[part 1 of 2: packages /CAN4/ISignalGroup to /CAN4/Cluster]
AUTOSAR XML (schema 4-3-0)
package /CAN4/ISignalGroup
  21 x i signal group:
    CAN4_SG_DKC1: i-signal=[CAN4_DKC_KeyNum_Sta, CAN4_DKC_KeyType_Sta, CAN4_DKC_PDkeyAreaRAPS_Sta, CAN4_DKC_ParkingMode_Cmd, CAN4_DKC_Re_VehData, CAN4_P_CommandToBCM, CAN4_P_CommandToPTG, CAN4_P_DKey_Area_LockUnlock, CAN4_P_DKey_Area_PS, CAN4_P_DKey_Area_PTG, CAN4_P_DKey_Welcome, CAN4_P_Dkey_Show_IVI, CAN4_P_KeyMiss, CAN4_P_KeyMode, CAN4_P_UID_LowPower], system-signal-group=CAN4_SG_DKC1
    CAN4_SG_DKC2: i-signal=[CAN4_EncryptionDATA_0_63, CAN4_EncryptionDATA_64_127, CAN4_Random_Number_X], system-signal-group=CAN4_SG_DKC2
    CAN4_SG_FD4_C100_0: i-signal=CAN4_FDC_CHA_EACEnDemand_Cmd, system-signal-group=CAN4_SG_FD4_C100_0
    CAN4_SG_FD4_CE100_0: i-signal=[CAN4_APS_Sta_System, CAN4_AllDoorSW, CAN4_AntiTheftSeatFold, CAN4_AntitheftSta, CAN4_BCM_DoorLock_Sta, CAN4_BrakeLamp, CAN4_CC_Crl_Sta, CAN4_CS_VCU1_CAN4, CAN4_CTDCtrl, CAN4_CTDLockSW, CAN4_CTDUnlockSW, CAN4_CrashDetd, CAN4_CtrlDrPwrStbA2, CAN4_CtrlFrBMSCCUCIR, CAN4_CtrlFrEDUINVERTER, CAN4_CtrlFrIRC1, CAN4_CtrlFrPwrStbA1P, CAN4_DKCAuthSta, CAN4_DKCTimeSN, CAN4_Dimmer, CAN4_DimmerEN, CAN4_DoorLockIND, CAN4_DrDoorSW, CAN4_Dr_SeatSta, CAN4_EquivAccPedalSWSta, CAN4_FD_DKC_VehData_Err, CAN4_FD_DKC_VehData_Sta, CAN4_FD_TBOX_DTCData_Err, CAN4_FD_TBOX_DTCData_Sta, CAN4_FD_TBOX_VehData_Err, CAN4_FD_TBOX_VehData_Sta, CAN4_Fr_ChargingDoorCtrl, CAN4_Fr_FogLamp, CAN4_Fr_Wiper_H, CAN4_Fr_Wiper_L, CAN4_HWResetSta, CAN4_H_Beam, CAN4_H_Beam_ADB, CAN4_HazardSW, CAN4_HoodSW, CAN4_HornCtrl, CAN4_LBSD, CAN4_LDRL, CAN4_LTurnLP, CAN4_L_APM_WdwEnable, CAN4_L_Beam, CAN4_LampPwr, CAN4_LockSetting, CAN4_MSA_Crl_Sta, CAN4_MirrorCtrl, CAN4_MirrorDefog, CAN4_PosLamp, CAN4_PsDoorSW, CAN4_PwrSta, CAN4_RBSD, CAN4_RC_VCU1_CAN4, CAN4_RDRL, CAN4_RLDoorSW, CAN4_RRDoorSW, CAN4_RTurnLP, CAN4_ReBrakeLPReq, CAN4_ReverseLamp, CAN4_RoomLampH, CAN4_RoomLampL, CAN4_Rr_ChargingDoorCtrl, CAN4_Rr_Defog, CAN4_Rr_FogLamp, CAN4_Rr_Wiper, CAN4_ShiftGearPosn, CAN4_TailgateHDSW, CAN4_TailgateRemote, CAN4_Tailgate_SW, CAN4_TimeSNDKCFbk, CAN4_TrunkRel, CAN4_WasherCtrl, CAN4_WiperFixMode], system-signal-group=CAN4_SG_FD4_CE100_0
    CAN4_SG_FD4_CE100_1: i-signal=[CAN4_ACSubMode, CAN4_APTC_ActFrRiPwr, CAN4_BatLoopActWtFlw, CAN4_BatteryMode, CAN4_CCU_ACLampSts, CAN4_CCU_ACMaxLampSts, CAN4_CCU_AutoLampSts, CAN4_CCU_AutoMidLampSts, CAN4_CCU_CbnPreACWkSts, CAN4_CCU_CbnPreEstimdTi, CAN4_CCU_CbnPreSts, CAN4_CCU_Dispaly_Request, CAN4_CCU_EcoSts, CAN4_CCU_FrtOnOffLampSts, CAN4_CCU_HEATMaxLampSts, CAN4_CCU_HiVoltageReq, CAN4_CCU_RrOnOffLampSts, CAN4_CCU_SyncLampSts, CAN4_CabinMode, CAN4_CoolgFanActDuty, CAN4_DeiceModReq, CAN4_EDriveMode, CAN4_FDC_THCM_CLEVentY_Sta, CAN4_FDC_THCM_CLEVentZ_Sta, CAN4_FDC_THCM_CLVent_Sta, CAN4_FDC_THCM_CREVentY_Sta, CAN4_FDC_THCM_CREVentZ_Sta, CAN4_FDC_THCM_CRVent_Sta, CAN4_FDC_THCM_DrEVentMode_Sta, CAN4_FDC_THCM_DrEVentY_Sta, CAN4_FDC_THCM_DrEVentZ_Sta, CAN4_FDC_THCM_DrVent_Sta, CAN4_FDC_THCM_PsEVentMode_Sta, CAN4_FDC_THCM_PsEVentY_Sta, CAN4_FDC_THCM_PsEVentZ_Sta, CAN4_FDC_THCM_PsVent_Sta, CAN4_FD_Blower_Cmd, CAN4_FD_Comp_Cmd, CAN4_FD_EWP1_Cmd, CAN4_FD_EWP2_Cmd, CAN4_FD_EWP3_Cmd, CAN4_FD_EXV1_Cmd, CAN4_FD_EXV2_Cmd, CAN4_FD_FWV_Cmd, CAN4_FD_FrLeAPTCHeatPwr_Cmd, CAN4_FD_FrRiAPTCHeatPwr_Cmd, CAN4_FD_FrWPTCHeatPwr_Cmd, CAN4_FD_RecyAuto_Cmd, CAN4_FD_RrAPTCHeatPwr_Cmd, CAN4_FD_SOTXV_Cmd, CAN4_FD_SOV1_Cmd, CAN4_FD_SOV2_Cmd, CAN4_FD_SOV3_Cmd, CAN4_FD_TWV_Cmd, CAN4_Fr_Coolantflow, CAN4_Fr_Coolanttemp, CAN4_HPThermalRecoveryReq, CAN4_Rr_Coolantflow, CAN4_Rr_Coolanttemp, CAN4_sigAirIntenZon1St, CAN4_sigAirIntenZon3St, CAN4_sigAmbAirT, CAN4_sigCbnAirT, CAN4_sigCbnPTCPwrAct, CAN4_sigCbnSolarLeft, CAN4_sigCbnSolarRight, CAN4_sigClmtCmprPwrAct, CAN4_sigClntTHvBattOut, CAN4_sigDfrstSt, CAN4_sigHvacSt, CAN4_sigRecircSt, CAN4_sigSetTempZon1St, CAN4_sigSetTempZon2St, CAN4_sigSetTempZon3St, CAN4_sigWindDirZon1St, CAN4_sigWindDirZon3St], system-signal-group=CAN4_SG_FD4_CE100_1
    CAN4_SG_FD4_CE100_2: i-signal=[CAN4_FD4_CE100_2_CS, CAN4_FD4_CE100_2_RC, CAN4_FDC_VCU_ReqHWReset_Cmd], system-signal-group=CAN4_SG_FD4_CE100_2
    CAN4_SG_FD4_CE100_3: i-signal=[CAN4_FDC_BCM_BBuzzer_Cmd, CAN4_FDC_BCM_BBuzzerout_Cmd, CAN4_FDC_BCM_EmExitLight_Cmd, CAN4_FDC_BCM_FrAtmoLamp_Cmd, CAN4_FDC_BCM_FrRmLampBright_Cmd, CAN4_FDC_BCM_FrRoomlamp_Cmd, CAN4_FDC_BCM_IBuzzerReq_Sta, CAN4_FDC_BCM_LSMLP_Cmd, CAN4_FDC_BCM_LTgateRel_Cmd, CAN4_FDC_BCM_RSMLP_Cmd, CAN4_FDC_BCM_RTgateRel_Cmd, CAN4_FDC_BCM_RevBuzzerout_Cmd, CAN4_FDC_BCM_RrAtmoLamp_Cmd, CAN4_FDC_BCM_RrRmLampBright_Cmd, CAN4_FDC_BCM_RrRoomlamp_Cmd, CAN4_FDC_BCM_STurnLpLeft_Cmd, CAN4_FDC_BCM_STurnLpRight_Cmd, CAN4_FDC_BCM_TgateHDSWL_Sta, CAN4_FDC_BCM_TgateHDSWR_Sta, CAN4_FDC_BCM_TgateSWL_Sta, CAN4_FDC_BCM_TgateSWR_Sta, CAN4_FDC_BCM_TurnLpLActive_Cmd, CAN4_FDC_BCM_TurnLpRActive_Cmd, CAN4_FDC_BCM_innerBuzzer_Cmd], system-signal-group=CAN4_SG_FD4_CE100_3
    CAN4_SG_FD4_CE200_0: i-signal=[CAN4_AmbLightBreath1, CAN4_AmbLightBreath2, CAN4_AmbLightBreath3, CAN4_AmbLightBreath4, CAN4_AmbLightBreath5, CAN4_AmbLightBreath6, CAN4_AmbLightBrightness1, CAN4_AmbLightBrightness2, CAN4_AmbLightBrightness3, CAN4_AmbLightBrightness4, CAN4_AmbLightBrightness5, CAN4_AmbLightBrightness6, CAN4_AmbLightColor1, CAN4_AmbLightColor2, CAN4_AmbLightColor3, CAN4_AmbLightColor4, CAN4_AmbLightColor5, CAN4_AmbLightColor6, CAN4_BCM_Buzzer_Req, CAN4_FDC_BCM_ATCtrl_Cmd, CAN4_FDC_BCM_DimSw, CAN4_FDC_BCM_FWasSw_Sta, CAN4_FDC_BCM_FWipSw_Sta, CAN4_FDC_BCM_HazardIND_Cmd, CAN4_FDC_BCM_LockAlarm_Cmd, CAN4_FDC_BCM_OutMode_Cmd, CAN4_FDC_BCM_PTGOpenHeight_Sta, CAN4_FDC_BCM_PassSW_Sta, CAN4_FDC_BCM_TurnSwTSetSta_Sta, CAN4_FDC_BCM_TurnSw_Sta, CAN4_FDC_BCM_UserHeightSet_Sta, CAN4_FDC_BCM_UserNow_Sta, CAN4_FDC_DKC_CommandToBCM_Cmd, CAN4_FDC_DKC_DKeyAreaPE_Sta, CAN4_FDC_DKC_SPTGDet_Cmd, CAN4_FDC_DKC_SPTGOpen_Cmd, CAN4_FDC_EChrg_SW_Sta, CAN4_FDC_THCM_ACTInitial_Cmd, CAN4_FDC_THCM_AirIntZ3_Sta, CAN4_FDHandleCmd, CAN4_FDLHandleLampCmd, CAN4_FDRHandleLampCmd, CAN4_WelcomeLight], system-signal-group=CAN4_SG_FD4_CE200_0
    CAN4_SG_FD4_OTA1: i-signal=[CAN4_OTA_DL_Available, CAN4_OTA_DL_Speed, CAN4_OTA_Debug_Code, CAN4_OTA_Emergency_Sta, CAN4_OTA_InVehicle_FW, CAN4_OTA_Lock_Req, CAN4_OTA_MDA_Status, CAN4_OTA_Mode, CAN4_OTA_Network_Type, CAN4_OTA_Permit_Agreed, CAN4_OTA_Progress_Rate, CAN4_OTA_Remained_Time, CAN4_OTA_TBOXResetReq, CAN4_OTA_Update_Available, CAN4_OTA_Updating_ECU_8bit], system-signal-group=CAN4_SG_FD4_OTA1
    CAN4_SG_GW4_CE100_0: i-signal=[CAN4_BrkPedalPos, CAN4_BrkPedalPos_Sta, CAN4_BrkSw_Sta, CAN4_BrkSw_V, CAN4_FDC_PTG_inner_SW_2, CAN4_L_Drv_CtrlCmd, CAN4_L_Pas_CtrlCmd, CAN4_L_RLD_CtrlCmd, CAN4_L_RRD_CtrlCmd, CAN4_MCPressure, CAN4_MCPressure_V, CAN4_VehSpeed], system-signal-group=CAN4_SG_GW4_CE100_0
    CAN4_SG_CGW_GW4_CE100_0: i-signal=[CAN4_AVM_parking_excute, CAN4_Approach_Unlock_SW, CAN4_ChrgInLockReq, CAN4_ChrgPlugSta, CAN4_DSEAT_anti_set, CAN4_DSEAT_entryfun_set, CAN4_DSEAT_vent_req, CAN4_Distance_unit, CAN4_ExtChrgSta, CAN4_HeadLampSW, CAN4_Hood_Latch_SW, CAN4_IVI_ChargePortSW_Sta, CAN4_IVI_DSEATHeater_Cmd, CAN4_IVI_ISA_OffsetSpd, CAN4_IVI_Located_STA, CAN4_IVI_PSEATHeater_Cmd, CAN4_IVI_PTG_Mode_SW, CAN4_IVI_PTG_Open_Height, CAN4_IVI_PTG_Sta_SW, CAN4_IVI_Time_Check, CAN4_IVI_Time_Day, CAN4_IVI_Time_Hour, CAN4_IVI_Time_Minute, CAN4_IVI_Time_Month, CAN4_IVI_Time_Second, CAN4_IVI_Time_Year, CAN4_IVI_TrailerCheckReq_Sta, CAN4_IVI_TrailerModeSW_Sta, CAN4_Light_ShowStart_Req, CAN4_Light_ShowStop_Req, CAN4_METER_KPH_Calcu, CAN4_OBCV2LSta, CAN4_OFF_AC_MODE, CAN4_PSEAT_vent_req, CAN4_SenstivityPosition, CAN4_TBOX_Remote_PW, CAN4_V2LSta, CAN4_Walkaway_Lock_SW, CAN4_WlcmLight_Mode], system-signal-group=CAN4_SG_CGW_GW4_CE100_0
    CAN4_SG_GW4_CE200_0: i-signal=[CAN4_IVI_LSEATvent_Cmd, CAN4_IVI_MLFMost_Cmd, CAN4_IVI_MLFootLift_Cmd, CAN4_IVI_MLNapMode_Cmd, CAN4_IVI_MLRecliner_Cmd, CAN4_IVI_MLRestore_Cmd, CAN4_IVI_MLSEATvent_Cmd, CAN4_IVI_MLSeatLift_Cmd, CAN4_IVI_MLSldRestore_Cmd, CAN4_IVI_MLSlider_Cmd, CAN4_IVI_MLZeroGravity_Cmd, CAN4_IVI_MRFMost_Cmd, CAN4_IVI_MRFootLift_Cmd, CAN4_IVI_MRNapMode_Cmd, CAN4_IVI_MRRecliner_Cmd, CAN4_IVI_MRRestore_Cmd, CAN4_IVI_MRSEATvent_Cmd, CAN4_IVI_MRSeatLift_Cmd, CAN4_IVI_MRSldRestore_Cmd, CAN4_IVI_MRSlider_Cmd, CAN4_IVI_MRZeroGravity_Cmd, CAN4_IVI_RSEATvent_Cmd], system-signal-group=CAN4_SG_GW4_CE200_0
    CAN4_SG_Z24_C1000_0: i-signal=[CAN4_Z24_CHA_AirPressureFC2_Sta, CAN4_Z24_CHA_AirPressurePC3_Sta, CAN4_Z24_CHA_AirPressureRC1_Sta], system-signal-group=CAN4_SG_Z24_C1000_0
    CAN4_SG_Z24_CE100_0: i-signal=[CAN4_Z24_BCM_EmExitOP_Sta, CAN4_Z24_BCM_FLTurnLampC_Sta, CAN4_Z24_BCM_FRTurnLampC_Sta, CAN4_Z24_BCM_FWiperAS_Sta, CAN4_Z24_BCM_FWiperProtection_Sta, CAN4_Z24_BCM_RLTurnLampC_Sta, CAN4_Z24_BCM_RRTurnLampC_Sta, CAN4_Z24_BCM_SeatBeltSW_Sta, CAN4_Z24_BCM_innerBuzzer_Sta], system-signal-group=CAN4_SG_Z24_CE100_0
    CAN4_SG_ZONE_DR1: i-signal=[CAN4_ACT1_Actuator_address, CAN4_ACT1_Actuator_set_position, CAN4_ACT1_Actuator_start_position, CAN4_ACT1_Applied_holding_current, CAN4_ACT1_Clear_Event_Flags, CAN4_ACT1_Emergency_run_position, CAN4_ACT1_Emergency_run_release, CAN4_ACT1_Rotation_direction, CAN4_ACT1_Save_programming_data, CAN4_ACT1_Select_position_specification, CAN4_ACT1_Speed_specification, CAN4_ACT1_Stall_detection_release, CAN4_ACT1_Stop_mode, CAN4_ACT2_Actuator_address, CAN4_ACT2_Actuator_set_position, CAN4_ACT2_Actuator_start_position, CAN4_ACT2_Applied_holding_current, CAN4_ACT2_Clear_Event_Flags, CAN4_ACT2_Emergency_run_position, CAN4_ACT2_Emergency_run_release, CAN4_ACT2_Rotation_direction, CAN4_ACT2_Save_programming_data, CAN4_ACT2_Select_position_specification, CAN4_ACT2_Speed_specification, CAN4_ACT2_Stall_detection_release, CAN4_ACT2_Stop_mode, CAN4_ACT3_Actuator_address, CAN4_ACT3_Actuator_set_position, CAN4_ACT3_Actuator_start_position, CAN4_ACT3_Applied_holding_current, CAN4_ACT3_Clear_Event_Flags, CAN4_ACT3_Emergency_run_position, CAN4_ACT3_Emergency_run_release, CAN4_ACT3_Rotation_direction, CAN4_ACT3_Save_programming_data, CAN4_ACT3_Select_position_specification, CAN4_ACT3_Speed_specification, CAN4_ACT3_Stall_detection_release, CAN4_ACT3_Stop_mode, CAN4_ACT4_Actuator_address, CAN4_ACT4_Actuator_set_position, CAN4_ACT4_Actuator_start_position, CAN4_ACT4_Applied_holding_current, CAN4_ACT4_Clear_Event_Flags, CAN4_ACT4_Emergency_run_position, CAN4_ACT4_Emergency_run_release, CAN4_ACT4_Rotation_direction, CAN4_ACT4_Save_programming_data, CAN4_ACT4_Select_position_specification, CAN4_ACT4_Speed_specification, CAN4_ACT4_Stall_detection_release, CAN4_ACT4_Stop_mode, CAN4_ACT5_Actuator_address, CAN4_ACT5_Actuator_set_position, CAN4_ACT5_Actuator_start_position, CAN4_ACT5_Applied_holding_current, CAN4_ACT5_Clear_Event_Flags, CAN4_ACT5_Emergency_run_position, CAN4_ACT5_Emergency_run_release, CAN4_ACT5_Rotation_direction, CAN4_ACT5_Save_programming_data, CAN4_ACT5_Select_position_specification, CAN4_ACT5_Speed_specification, CAN4_ACT5_Stall_detection_release, CAN4_ACT5_Stop_mode, CAN4_AllLockSta, CAN4_AutoLightSW, CAN4_BrakeLampFail, CAN4_DrLockSta, CAN4_HornSW, CAN4_MIRROR_FOLD_SW, CAN4_PsLockSta, CAN4_RLLockSta, CAN4_RLS_Exist, CAN4_RLTurnLPErr, CAN4_RLTurnLampC, CAN4_RRLockSta, CAN4_RRTurnLPErr, CAN4_RRTurnLampC, CAN4_RWiperAS, CAN4_RWiperProtection, CAN4_Wip_Speed, CAN4_WiperSWPos, CAN4_WiperZeroPosSW, CAN4_ZDR_THCM_IntakeFail_Sta, CAN4_ZDR_THCM_LINACT1_Sta, CAN4_ZDR_THCM_LINACT2_Sta, CAN4_ZDR_THCM_LINACT3_Sta, CAN4_ZDR_THCM_LINACT4_Sta, CAN4_ZDR_THCM_LINACT5_Sta, CAN4_ZDR_THCM_ModeFail_Sta], system-signal-group=CAN4_SG_ZONE_DR1
    CAN4_SG_ZONE_DR_VCU: i-signal=[CAN4_APTC_Err, CAN4_Blower_Err, CAN4_Blower_FB, CAN4_DrADASCurr, CAN4_DrAPWLINErr, CAN4_DrAPWStaErr, CAN4_DrAuBoxPwrN1Curr, CAN4_DrAuBoxPwrN2Curr, CAN4_DrColumnSWFault, CAN4_DrCtrlBDVolt, CAN4_DrCtrlTemp, CAN4_DrEOBDFault, CAN4_DrIVIFault, CAN4_DrInfoErrSta, CAN4_DrInfoFault, CAN4_DrONA1ErrSta, CAN4_DrPMMLVOutPErrLmp, CAN4_DrPMMLimpHomeActReq, CAN4_DrPMMSysErrLmp, CAN4_DrPowerTemp1, CAN4_DrPowerTemp2, CAN4_DrPwrInformationSta, CAN4_DrPwrONA1Curr, CAN4_DrPwrONA2Curr, CAN4_DrPwrSta, CAN4_DrPwrStdbyACurr, CAN4_DrPwrWinErrSta, CAN4_DrPwrWindowECUFault, CAN4_DrSCPSysErrLmp, CAN4_DrStdAErrSta, CAN4_DrTHCMFault, CAN4_RegenSW_Err, CAN4_SolarL, CAN4_SolarL_Err, CAN4_SolarR, CAN4_SolarR_Err, CAN4_T_Face_L, CAN4_T_Face_L_Err, CAN4_T_Face_R, CAN4_T_Face_R_Err, CAN4_T_Face_Rr, CAN4_T_Face_Rr_Err, CAN4_T_Foot_L, CAN4_T_Foot_L_Err, CAN4_T_Foot_R, CAN4_T_Foot_R_Err, CAN4_T_Foot_Rr, CAN4_T_Foot_Rr_Err, CAN4_Tevap, CAN4_Tevap_Err, CAN4_Tincar, CAN4_Tincar_Err, CAN4_ZDR_SYS_APMRetryCnt_Sta, CAN4_ZDR_SYS_BSWSleepReq_Sta, CAN4_ZDR_SYS_CSWRetryCnt_Sta, CAN4_ZDR_VCU_HWReset_Sta, CAN4_ZDR_VCU_PwrSupply_Sta, CAN4_ZoneDrMalfunLevel], system-signal-group=CAN4_SG_ZONE_DR_VCU
    CAN4_SG_ZONE_FR1: i-signal=[CAN4_BDC_1_MoveEnable, CAN4_BDC_1_ReqMovePos, CAN4_BMSChksmHSC6, CAN4_BMSEnbPTCHSC6, CAN4_BMSInptClntTemHSC6, CAN4_BMSPackVol_h6HSC6, CAN4_BMSReqMdHSC6, CAN4_BMSReqPWMHSC6, CAN4_BMSReqPwrHSC6, CAN4_BMSReqRlngCtrHSC6, CAN4_BMSReqTapPosHSC6, CAN4_CCM_SpdCmd, CAN4_CCV4_MoveEnable, CAN4_CCV4_ReqMovePos, CAN4_ChargeInletLockSta, CAN4_CompProEN, CAN4_EWP1_Default_Operation_EWP_Rq, CAN4_EWP1_RPM_Target_EWP_Rq, CAN4_EWP2_Default_Operation_EWP_Rq, CAN4_EWP2_RPM_Target_EWP_Rq, CAN4_EWP3_Default_Operation_EWP_Rq, CAN4_EWP3_RPM_Target_EWP_Rq, CAN4_EXV2_Cmd_Init_Rq, CAN4_EXV2_Cmd_Move_Enbl, CAN4_EXV2_Cmd_Set_Rq, CAN4_EXV_Cmd_Init_Rq, CAN4_EXV_Cmd_Move_Enbl, CAN4_EXV_Cmd_Set_Rq, CAN4_FLPosLPErr, CAN4_FLTurnLPErr, CAN4_FLTurnLampC, CAN4_FLTurn_Light_Warning, CAN4_FRPosLPErr, CAN4_FRTurnLPErr, CAN4_FRTurnLampC, CAN4_FRTurn_Light_Warning, CAN4_FWiperAS, CAN4_FWiperProtection, CAN4_LADBErr, CAN4_LADB_Hibeam_Indication, CAN4_LADB_Operation_Status, CAN4_LADB_Warning, CAN4_LAHB_Warning, CAN4_LDRLErr, CAN4_LDRL_Warning, CAN4_LH_BeamErr, CAN4_LLB_Warning, CAN4_LL_BeamErr, CAN4_Lposition_Lamp_Warning, CAN4_RADBErr, CAN4_RADB_Hibeam_Indication, CAN4_RADB_Operation_Status, CAN4_RADB_Warning, CAN4_RAHB_Warning, CAN4_RDRLErr, CAN4_RDRL_Warning, CAN4_RH_BeamErr, CAN4_RLB_Warning, CAN4_RL_BeamErr, CAN4_Rposition_Lamp_Warning, CAN4_TrailerCheck, CAN4_TrailerModeSta, CAN4_ZFR_BCM_ChargerDoorSW_Sta, CAN4_ZFR_EChrg_Active_Sta, CAN4_ZFR_EChrg_Sys_Sta, CAN4_ZFR_THCM_CLEVentActY_Sta, CAN4_ZFR_THCM_CLEVentActZ_Sta, CAN4_ZFR_THCM_CREVentActY_Sta, CAN4_ZFR_THCM_CREVentActZ_Sta, CAN4_ZFR_THCM_DrEVentActY_Sta, CAN4_ZFR_THCM_DrEVentActZ_Sta, CAN4_ZFR_THCM_PsEVentActY_Sta, CAN4_ZFR_THCM_PsEVentActZ_Sta], system-signal-group=CAN4_SG_ZONE_FR1
    CAN4_SG_ZONE_FR_VCU: i-signal=[CAN4_Bat_In_Temp, CAN4_Bat_In_Temp_Err, CAN4_Bat_Out_Temp, CAN4_Bat_Out_Temp_Err, CAN4_COMP_Err, CAN4_EACProtectEnable, CAN4_EWP1_Err, CAN4_EWP2_Err, CAN4_EWP3_Err, CAN4_EXV1_Err, CAN4_EXV2_Err, CAN4_FWV_Err, CAN4_Fan_Err, CAN4_FrBMSCCUCErr, CAN4_FrBMS_CCU_CIRCurr, CAN4_FrBMS_CCU_CIRFault, CAN4_FrCtrlBDVolt, CAN4_FrCtrlTemp, CAN4_FrEDUErr, CAN4_FrEDU_INVERTERCurr, CAN4_FrEDU_INVERTERFault, CAN4_FrIRC_1Curr, CAN4_FrIRC_2Curr, CAN4_FrPMMLVOutPErrLmp, CAN4_FrPMMLimpHomeActReq, CAN4_FrPMMSysErrLmp, CAN4_FrPowerTemp1, CAN4_FrPowerTemp2, CAN4_FrPwrONA1Fault, CAN4_FrPwrONA2Curr, CAN4_FrPwrONA3Curr, CAN4_FrPwrSta, CAN4_FrPwrStdbyA1Fault, CAN4_FrPwrStdbyA1PlusCurr, CAN4_FrPwrStdbyA1PlusFault, CAN4_FrPwrStdbyA2Curr, CAN4_FrPwrStdbyA2PlusCurr, CAN4_FrPwrStdbyA2PlusFault, CAN4_FrStdA1PCErr, CAN4_FrStdA2PCErr, CAN4_FrStdA2PErr, CAN4_Motor_In_Temp, CAN4_Motor_In_Temp_Err, CAN4_Motor_Out_Temp, CAN4_Motor_Out_Temp_Err, CAN4_PT_High_P, CAN4_PT_High_P_Err, CAN4_PT_High_T, CAN4_PT_High_Tact, CAN4_PT_High_Tact_Err, CAN4_PT_Low_P1, CAN4_PT_Low_P1_Err, CAN4_PT_Low_P2, CAN4_PT_Low_P2_Err, CAN4_PT_Low_T1, CAN4_PT_Low_T1_Err, CAN4_PT_Low_T2, CAN4_PT_Low_T2_Err, CAN4_SOTXV_Err, CAN4_SOV1_Err, CAN4_SOV2_Err, CAN4_SOV3_Err, CAN4_TWV_Err, CAN4_Tamb, CAN4_Tamb_Err, CAN4_WPTC_Err, CAN4_ZFR_SYS_BMSCCURetryCnt_Sta, CAN4_ZFR_SYS_BSWSleepReq_Sta, CAN4_ZFR_SYS_MCURetryCnt_Sta, CAN4_ZFR_VCU_HWReset_Sta, CAN4_ZFR_VCU_PwrSupply_Sta, CAN4_ZoneFrMalfunLevel], system-signal-group=CAN4_SG_ZONE_FR_VCU
    CAN4_SG_zGW_APTC1: i-signal=[CAN4_FrntPTCBusLineHiV, CAN4_FrntPTCComFlt, CAN4_FrntPTCFltSt, CAN4_FrntPTCHVOverUFlt, CAN4_FrntPTCHVUnderUFlt, CAN4_FrntPTCHWVers, CAN4_FrntPTCLVOverUFlt, CAN4_FrntPTCLVUnderUFlt, CAN4_FrntPTCLeActHeatPwr, CAN4_FrntPTCLeBusLineC, CAN4_FrntPTCLeCoreOverTFlt, CAN4_FrntPTCLeCoreT, CAN4_FrntPTCLeCoreTSnsrFlt, CAN4_FrntPTCLeIGBTOverTFlt, CAN4_FrntPTCLeIGBTShoCircFlt, CAN4_FrntPTCLeIGBTT, CAN4_FrntPTCLeIGBTTSnsrFlt, CAN4_FrntPTCLeOpentCircFlt, CAN4_FrntPTCLeOverAFlt, CAN4_FrntPTCPCBOverTFlt, CAN4_FrntPTCPCBT, CAN4_FrntPTCPCBTSnsrFlt, CAN4_FrntPTCRearLeActHeatPwr, CAN4_FrntPTCRearLeBusLineC, CAN4_FrntPTCRearLeCoreOverTFlt, CAN4_FrntPTCRearLeCoreT, CAN4_FrntPTCRearLeCoreTSnsrFlt, CAN4_FrntPTCRearLeIGBTShoCFlt, CAN4_FrntPTCRearLeOpentCircFlt, CAN4_FrntPTCRearLeOverAFlt, CAN4_FrntPTCRearRiActHeatPwr, CAN4_FrntPTCRearRiBusLineC, CAN4_FrntPTCRearRiCoreOverTFlt, CAN4_FrntPTCRearRiCoreT, CAN4_FrntPTCRearRiCoreTSnsrFlt, CAN4_FrntPTCRearRiIGBTShoCFlt, CAN4_FrntPTCRearRiOpentCircFlt, CAN4_FrntPTCRearRiOverAFlt, CAN4_FrntPTCRiActHeatPwr, CAN4_FrntPTCRiBusLineC, CAN4_FrntPTCRiCoreOverTFlt, CAN4_FrntPTCRiCoreT, CAN4_FrntPTCRiCoreTSnsrFlt, CAN4_FrntPTCRiIGBTOverTFlt, CAN4_FrntPTCRiIGBTShoCircFlt, CAN4_FrntPTCRiIGBTT, CAN4_FrntPTCRiIGBTTSnsrFlt, CAN4_FrntPTCRiOpentCircFlt, CAN4_FrntPTCRiOverAFlt, CAN4_FrntPTCSWVers, CAN4_FrntPTCSts, CAN4_FrntPTCSupplierCod], system-signal-group=CAN4_SG_zGW_APTC1
    CAN4_SG_zGW_CANFr1: i-signal=[CAN4_COMP_ActualPwr, CAN4_COMP_ComLost, CAN4_COMP_ConCur, CAN4_COMP_ConVolt, CAN4_COMP_CtrlCircFlt, CAN4_COMP_CurOverProtect, CAN4_COMP_CurVaild, CAN4_COMP_IPM_HWFLt, CAN4_COMP_IPM_TempOverFlt, CAN4_COMP_Init, CAN4_COMP_SpdVaild, CAN4_COMP_Sta, CAN4_COMP_StatorSpd, CAN4_COMP_VoltLessErr, CAN4_COMP_VoltOverErr, CAN4_COMP_VoltVaild, CAN4_EAC_DrvVoltFalt, CAN4_EAC_MotCrt, CAN4_EAC_MotorLackFalt, CAN4_EAC_OvLoadFalt, CAN4_EAC_Temp, CAN4_EAC_TempSnsrFalt, CAN4_PTC1_PowerConsumption, CAN4_PTCActuCrntHSC6, CAN4_PTCActuPWMDutyHSC6, CAN4_PTCActuPwrHSC6, CAN4_PTCActuVolHSC6, CAN4_PTCChksmHSC6, CAN4_PTCFltLvlHSC6, CAN4_PTCHVLckStsHSC6, CAN4_PTCIGBTOverHeatHSC6, CAN4_PTCIGBTStsHSC6, CAN4_PTCIGBTTemHSC6, CAN4_PTCNTCStsHSC6, CAN4_PTCOtptTemHSC6, CAN4_PTCOverCrntHSC6, CAN4_PTCOverHeatHSC6, CAN4_PTCOverVolHSC6, CAN4_PTCPCBTemHSC6, CAN4_PTCRlngCtrHSC6, CAN4_PTCSecChksmHSC6, CAN4_PTCSecRlngCtrHSC6, CAN4_PTCStsHSC6, CAN4_PTCUnderVolHSC6], system-signal-group=CAN4_SG_zGW_CANFr1
    CAN4_SG_zGW_LINDr1: i-signal=[CAN4_CSW_DimSw, CAN4_CSW_FWasSw_Sta, CAN4_CSW_FWipSw_Sta, CAN4_CSW_HW_version, CAN4_CSW_PassSW_Sta, CAN4_CSW_RWasSW_Sta, CAN4_CSW_RWipIntSw_Sta, CAN4_CSW_SW_version, CAN4_CSW_TurnSw_Sta, CAN4_CSW_resp_error, CAN4_FAPWL_01_LIN_Response_Error, CAN4_L_Drv_Motor_Relay_Error, CAN4_L_Drv_Motor_Ripple_Error, CAN4_L_Drv_OverHeat_Protect, CAN4_L_Drv_Val_Wdw_Opened, CAN4_L_Drv_Wdw_Init, CAN4_L_Drv_Wdw_LocalSwitch, CAN4_L_Drv_Wdw_OD_Sts, CAN4_L_Drv_Wdw_Obs_InhibitSts, CAN4_L_Drv_Wdw_Pas_Switch, CAN4_L_Drv_Wdw_PositionSts, CAN4_L_Drv_Wdw_RLD_Switch, CAN4_L_Drv_Wdw_RRD_Switch, CAN4_L_Drv_Wdw_Running_Sts, CAN4_L_Pas_Motor_Relay_Error, CAN4_L_Pas_Motor_Ripple_Error, CAN4_L_Pas_OverHeat_Protect, CAN4_L_Pas_Val_Wdw_Opened, CAN4_L_Pas_Wdw_Init, CAN4_L_Pas_Wdw_LocalSwitch, CAN4_L_Pas_Wdw_OD_Sts, CAN4_L_Pas_Wdw_Obs_InhibitSts, CAN4_L_Pas_Wdw_PositionSts, CAN4_L_Pas_Wdw_Running_Sts, CAN4_L_Power_Status, CAN4_L_RLD_Motor_Relay_Error, CAN4_L_RLD_Motor_Ripple_Error, CAN4_L_RLD_OverHeat_Protect, CAN4_L_RLD_Val_Wdw_Opened, CAN4_L_RLD_Wdw_Init, CAN4_L_RLD_Wdw_LocalSwitch, CAN4_L_RLD_Wdw_OD_Sts, CAN4_L_RLD_Wdw_Obs_InhibitSts, CAN4_L_RLD_Wdw_PositionSts, CAN4_L_RLD_Wdw_Running_Sts, CAN4_L_RRD_Motor_Relay_Error, CAN4_L_RRD_Motor_Ripple_Error, CAN4_L_RRD_OverHeat_Protect, CAN4_L_RRD_Val_Wdw_Opened, CAN4_L_RRD_Wdw_Init, CAN4_L_RRD_Wdw_LocalSwitch, CAN4_L_RRD_Wdw_OD_Sts, CAN4_L_RRD_Wdw_Obs_InhibitSts, CAN4_L_RRD_Wdw_PositionSts, CAN4_L_RRD_Wdw_Running_Sts, CAN4_RAPWL_01_LIN_Response_Error, CAN4_RLS_LIN_Resp_Err, CAN4_RLS_Lamp_Sta, CAN4_RLS_LightSnrErr, CAN4_RLS_RainSnrErr, CAN4_RLS_RainSnrWiperCmd, CAN4_SWC2_HW_Version, CAN4_SWC2_L_ADAS_Sta, CAN4_SWC2_L_DriveMode_Sta, CAN4_SWC2_L_Home_Sta, CAN4_SWC2_L_Left_Sta, CAN4_SWC2_L_RegenUp_Sta, CAN4_SWC2_L_Right_Sta, CAN4_SWC2_L_ScrollDown_Sta, CAN4_SWC2_L_ScrollPress_Sta, CAN4_SWC2_L_ScrollUp_Sta, CAN4_SWC2_R_Customize_Sta, CAN4_SWC2_R_Left_Sta, CAN4_SWC2_R_PageSwitch_Sta, CAN4_SWC2_R_RegenDown_Sta, CAN4_SWC2_R_Right_Sta, CAN4_SWC2_R_ScrollDown_Sta, CAN4_SWC2_R_ScrollPress_Sta, CAN4_SWC2_R_ScrollUp_Sta, CAN4_SWC2_R_VR_Sta, CAN4_SWC2_ResponseError, CAN4_SWC2_SW_Version, CAN4_SWC_ACC_Sta, CAN4_SWC_A_HW_version, CAN4_SWC_A_Resp_Err, CAN4_SWC_A_SW_version, CAN4_SWC_CANCEL_Sta, CAN4_SWC_Distance_Sta, CAN4_SWC_Down_Sta, CAN4_SWC_Drivemode_Sta, CAN4_SWC_LKA_Sta, CAN4_SWC_Left_Sta, CAN4_SWC_RegenDown, CAN4_SWC_RegenUp, CAN4_SWC_Res_Up_Sta, CAN4_SWC_Right_Sta, CAN4_SWC_Set_down_Sta, CAN4_SWC_Trip_Sta, CAN4_SWC_Undefined_Sta, CAN4_SWC_Up_Sta, CAN4_SWC_VR_Sta, CAN4_SWC_mode_Sta, CAN4_SWC_resp_error], system-signal-group=CAN4_SG_zGW_LINDr1
package /CAN4/Cluster
  can cluster CAN4: baudrate=500, can-fd-baudrate=2000
    can physical channel CAN4: comm-connectors=ConnCAN4
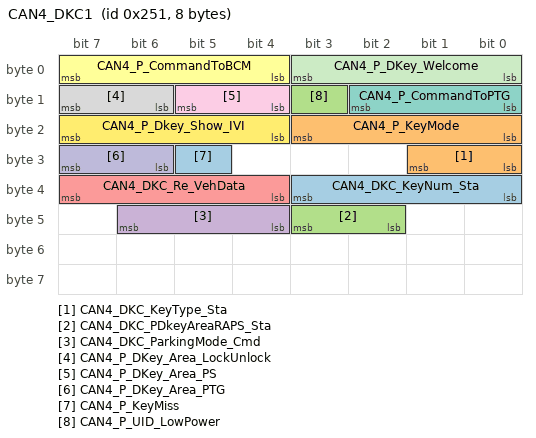
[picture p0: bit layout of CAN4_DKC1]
      frame CAN4_DKC1: id 0x251, frame-length=8, can-addressing-mode=STANDARD, can-fd-frame-support=true, can-frame-rx-behavior=CAN-FD, can-frame-tx-behavior=CAN-FD
        pdu CAN4_DKC1: length=8, minimum-delay=0.0, transmission-mode-true-timing={cyclic-timing=time-period=0.1, event-controlled-timing={number-of-repetitions=0, repetition-period=0}}, unused-bit-pattern=0
          mapping CAN4_SG_DKC1: i-signal-group=CAN4_SG_DKC1, start-position=0, transfer-property=TRIGGERED-ON-CHANGE
          signal CAN4_DKC_KeyNum_Sta: start 35, 4 bit, big-endian, i-signal-type=PRIMITIVE, init-value=constant-reference=Init_CAN4_DKC_KeyNum_Sta, base-type=uint8, implementation-data-type=uint8, transfer-property=TRIGGERED-ON-CHANGE
          signal CAN4_DKC_KeyType_Sta: start 25, 2 bit, big-endian, i-signal-type=PRIMITIVE, init-value=constant-reference=Init_CAN4_DKC_KeyType_Sta, base-type=uint8, implementation-data-type=uint8, transfer-property=TRIGGERED-ON-CHANGE
          signal CAN4_DKC_PDkeyAreaRAPS_Sta: start 43, 2 bit, big-endian, i-signal-type=PRIMITIVE, init-value=constant-reference=Init_CAN4_DKC_PDkeyAreaRAPS_Sta, base-type=uint8, implementation-data-type=uint8, transfer-property=TRIGGERED-ON-CHANGE
          signal CAN4_DKC_ParkingMode_Cmd: start 46, 3 bit, big-endian, i-signal-type=PRIMITIVE, init-value=constant-reference=Init_CAN4_DKC_ParkingMode_Cmd, base-type=uint8, implementation-data-type=uint8, transfer-property=TRIGGERED-ON-CHANGE
          signal CAN4_DKC_Re_VehData: start 39, 4 bit, big-endian, i-signal-type=PRIMITIVE, init-value=constant-reference=Init_CAN4_DKC_Re_VehData, base-type=uint8, implementation-data-type=uint8, transfer-property=TRIGGERED-ON-CHANGE
          signal CAN4_P_CommandToBCM: start 7, 4 bit, big-endian, i-signal-type=PRIMITIVE, init-value=constant-reference=Init_CAN4_P_CommandToBCM, base-type=uint8, implementation-data-type=uint8, transfer-property=TRIGGERED-ON-CHANGE
          signal CAN4_P_CommandToPTG: start 10, 3 bit, big-endian, i-signal-type=PRIMITIVE, init-value=constant-reference=Init_CAN4_P_CommandToPTG, base-type=uint8, implementation-data-type=uint8, transfer-property=PENDING
          signal CAN4_P_DKey_Area_LockUnlock: start 15, 2 bit, big-endian, i-signal-type=PRIMITIVE, init-value=constant-reference=Init_CAN4_P_DKey_Area_LockUnlock, base-type=uint8, implementation-data-type=uint8, transfer-property=PENDING
          signal CAN4_P_DKey_Area_PS: start 13, 2 bit, big-endian, i-signal-type=PRIMITIVE, init-value=constant-reference=Init_CAN4_P_DKey_Area_PS, base-type=uint8, implementation-data-type=uint8, transfer-property=PENDING
          signal CAN4_P_DKey_Area_PTG: start 31, 2 bit, big-endian, i-signal-type=PRIMITIVE, init-value=constant-reference=Init_CAN4_P_DKey_Area_PTG, base-type=uint8, implementation-data-type=uint8, transfer-property=PENDING
          signal CAN4_P_DKey_Welcome: start 3, 4 bit, big-endian, i-signal-type=PRIMITIVE, init-value=constant-reference=Init_CAN4_P_DKey_Welcome, base-type=uint8, implementation-data-type=uint8, transfer-property=PENDING
          signal CAN4_P_Dkey_Show_IVI: start 23, 4 bit, big-endian, i-signal-type=PRIMITIVE, init-value=constant-reference=Init_CAN4_P_Dkey_Show_IVI, base-type=uint8, implementation-data-type=uint8, transfer-property=PENDING
          signal CAN4_P_KeyMiss: start 29, 1 bit, big-endian, i-signal-type=PRIMITIVE, init-value=constant-reference=Init_CAN4_P_KeyMiss, base-type=uint8, implementation-data-type=uint8, transfer-property=PENDING
          signal CAN4_P_KeyMode: start 19, 4 bit, big-endian, i-signal-type=PRIMITIVE, init-value=constant-reference=Init_CAN4_P_KeyMode, base-type=uint8, implementation-data-type=uint8, transfer-property=TRIGGERED-ON-CHANGE
          signal CAN4_P_UID_LowPower: start 11, 1 bit, big-endian, i-signal-type=PRIMITIVE, init-value=constant-reference=Init_CAN4_P_UID_LowPower, base-type=uint8, implementation-data-type=uint8, transfer-property=TRIGGERED-ON-CHANGE
      frame CAN4_DKC2: id 0x252, frame-length=24, can-addressing-mode=STANDARD, can-fd-frame-support=true, can-frame-rx-behavior=CAN-FD, can-frame-tx-behavior=CAN-FD
        pdu CAN4_DKC2: length=24, minimum-delay=0.0, transmission-mode-true-timing={cyclic-timing=time-period=0.1, event-controlled-timing={number-of-repetitions=0, repetition-period=0}}, unused-bit-pattern=0
          mapping CAN4_SG_DKC2: i-signal-group=CAN4_SG_DKC2, start-position=0, transfer-property=TRIGGERED-ON-CHANGE
          signal CAN4_EncryptionDATA_0_63: start 135, 64 bit, big-endian, i-signal-type=PRIMITIVE, init-value=constant-reference=Init_CAN4_EncryptionDATA_0_63, base-type=uint64, implementation-data-type=uint64, transfer-property=TRIGGERED-ON-CHANGE
          signal CAN4_EncryptionDATA_64_127: start 71, 64 bit, big-endian, i-signal-type=PRIMITIVE, init-value=constant-reference=Init_CAN4_EncryptionDATA_64_127, base-type=uint64, implementation-data-type=uint64, transfer-property=TRIGGERED-ON-CHANGE
          signal CAN4_Random_Number_X: start 7, 64 bit, big-endian, i-signal-type=PRIMITIVE, init-value=constant-reference=Init_CAN4_Random_Number_X, base-type=uint64, implementation-data-type=uint64, transfer-property=PENDING
      frame CAN4_DiagFuncReqFT: id 0x7D0, frame-length=8, can-addressing-mode=STANDARD, can-fd-frame-support=true, can-frame-rx-behavior=CAN-FD, can-frame-tx-behavior=CAN-FD
        n pdu CAN4_DiagFuncReqFT: length=8
      frame CAN4_DiagPhysReqToAirPTC: id 0x6A5, frame-length=8, can-addressing-mode=STANDARD, can-fd-frame-support=true, can-frame-rx-behavior=CAN-FD, can-frame-tx-behavior=CAN-FD
        n pdu CAN4_DiagPhysReqToAirPTC: length=8
      frame CAN4_DiagPhysReqToCompressor: id 0x6C5, frame-length=8, can-addressing-mode=STANDARD, can-fd-frame-support=true, can-frame-rx-behavior=CAN-FD, can-frame-tx-behavior=CAN-FD
        n pdu CAN4_DiagPhysReqToCompressor: length=8
      frame CAN4_DiagPhysReqToDKC: id 0x685, frame-length=32, can-addressing-mode=STANDARD, can-fd-frame-support=true, can-frame-rx-behavior=CAN-FD, can-frame-tx-behavior=CAN-FD
        n pdu CAN4_DiagPhysReqToDKC: length=8
      frame CAN4_DiagPhysReqToWPTC: id 0x6B5, frame-length=8, can-addressing-mode=STANDARD, can-fd-frame-support=true, can-frame-rx-behavior=CAN-FD, can-frame-tx-behavior=CAN-FD
        n pdu CAN4_DiagPhysReqToWPTC: length=8
      frame CAN4_DiagPhysReqToZONE_DR: id 0x6C0, frame-length=64, can-addressing-mode=STANDARD, can-fd-frame-support=true, can-frame-rx-behavior=CAN-FD, can-frame-tx-behavior=CAN-FD
        n pdu CAN4_DiagPhysReqToZONE_DR: length=8
      frame CAN4_DiagPhysReqToZONE_FR: id 0x684, frame-length=64, can-addressing-mode=STANDARD, can-fd-frame-support=true, can-frame-rx-behavior=CAN-FD, can-frame-tx-behavior=CAN-FD
        n pdu CAN4_DiagPhysReqToZONE_FR: length=8
      frame CAN4_DiagPhysReqToZONE_FR_24: id 0x697, frame-length=64, can-addressing-mode=STANDARD, can-fd-frame-support=true, can-frame-rx-behavior=CAN-FD, can-frame-tx-behavior=CAN-FD
        n pdu CAN4_DiagPhysReqToZONE_FR_24: length=8
      frame CAN4_DiagRespFromAirPTC: id 0x625, frame-length=8, can-addressing-mode=STANDARD, can-fd-frame-support=true, can-frame-rx-behavior=CAN-FD, can-frame-tx-behavior=CAN-FD
        n pdu CAN4_DiagRespFromAirPTC: length=8
      frame CAN4_DiagRespFromCompressor: id 0x645, frame-length=8, can-addressing-mode=STANDARD, can-fd-frame-support=true, can-frame-rx-behavior=CAN-FD, can-frame-tx-behavior=CAN-FD
        n pdu CAN4_DiagRespFromCompressor: length=8
      frame CAN4_DiagRespFromDKC: id 0x605, frame-length=32, can-addressing-mode=STANDARD, can-fd-frame-support=true, can-frame-rx-behavior=CAN-FD, can-frame-tx-behavior=CAN-FD
        n pdu CAN4_DiagRespFromDKC: length=8
      frame CAN4_DiagRespFromWPTC: id 0x635, frame-length=8, can-addressing-mode=STANDARD, can-fd-frame-support=true, can-frame-rx-behavior=CAN-FD, can-frame-tx-behavior=CAN-FD
        n pdu CAN4_DiagRespFromWPTC: length=8
      frame CAN4_DiagRespFromZONE_DR: id 0x640, frame-length=64, can-addressing-mode=STANDARD, can-fd-frame-support=true, can-frame-rx-behavior=CAN-FD, can-frame-tx-behavior=CAN-FD
        n pdu CAN4_DiagRespFromZONE_DR: length=8
      frame CAN4_DiagRespFromZONE_FR: id 0x604, frame-length=64, can-addressing-mode=STANDARD, can-fd-frame-support=true, can-frame-rx-behavior=CAN-FD, can-frame-tx-behavior=CAN-FD
        n pdu CAN4_DiagRespFromZONE_FR: length=8
      frame CAN4_DiagRespFromZONE_FR_24: id 0x617, frame-length=64, can-addressing-mode=STANDARD, can-fd-frame-support=true, can-frame-rx-behavior=CAN-FD, can-frame-tx-behavior=CAN-FD
        n pdu CAN4_DiagRespFromZONE_FR_24: length=8
      frame CAN4_FD4_C100_0: id 0x202, frame-length=32, can-addressing-mode=STANDARD, can-fd-frame-support=true, can-frame-rx-behavior=CAN-FD, can-frame-tx-behavior=CAN-FD
        pdu CAN4_FD4_C100_0: length=32, minimum-delay=0.0, transmission-mode-true-timing=cyclic-timing=time-period=0.1, unused-bit-pattern=0
          mapping CAN4_SG_FD4_C100_0: i-signal-group=CAN4_SG_FD4_C100_0, start-position=0, transfer-property=PENDING
          signal CAN4_FDC_CHA_EACEnDemand_Cmd: start 8, 8 bit, little-endian, i-signal-type=PRIMITIVE, init-value=constant-reference=Init_CAN4_FDC_CHA_EACEnDemand_Cmd, base-type=uint8, implementation-data-type=uint8, transfer-property=PENDING
      frame CAN4_FD4_CE100_0: id 0x116, frame-length=32, can-addressing-mode=STANDARD, can-fd-frame-support=true, can-frame-rx-behavior=CAN-FD, can-frame-tx-behavior=CAN-FD
        pdu CAN4_FD4_CE100_0: length=32, minimum-delay=0.0, transmission-mode-true-timing=event-controlled-timing={number-of-repetitions=0, repetition-period=0}, unused-bit-pattern=0
          mapping CAN4_SG_FD4_CE100_0: i-signal-group=CAN4_SG_FD4_CE100_0, start-position=0, transfer-property=TRIGGERED
          signal CAN4_APS_Sta_System: start 213, 3 bit, big-endian, i-signal-type=PRIMITIVE, init-value=constant-reference=Init_CAN4_APS_Sta_System, base-type=uint8, implementation-data-type=uint8, transfer-property=TRIGGERED
          signal CAN4_AllDoorSW: start 155, 1 bit, big-endian, i-signal-type=PRIMITIVE, init-value=constant-reference=Init_CAN4_AllDoorSW, base-type=uint8, implementation-data-type=uint8, transfer-property=TRIGGERED
          signal CAN4_AntiTheftSeatFold: start 115, 1 bit, big-endian, i-signal-type=PRIMITIVE, init-value=constant-reference=Init_CAN4_AntiTheftSeatFold, base-type=uint8, implementation-data-type=uint8, transfer-property=TRIGGERED
          signal CAN4_AntitheftSta: start 114, 2 bit, big-endian, i-signal-type=PRIMITIVE, init-value=constant-reference=Init_CAN4_AntitheftSta, base-type=uint8, implementation-data-type=uint8, transfer-property=TRIGGERED
          signal CAN4_BCM_DoorLock_Sta: start 101, 1 bit, big-endian, i-signal-type=PRIMITIVE, init-value=constant-reference=Init_CAN4_BCM_DoorLock_Sta, base-type=uint8, implementation-data-type=uint8, transfer-property=TRIGGERED
          signal CAN4_BrakeLamp: start 121, 1 bit, big-endian, i-signal-type=PRIMITIVE, init-value=constant-reference=Init_CAN4_BrakeLamp, base-type=uint8, implementation-data-type=uint8, transfer-property=TRIGGERED
          signal CAN4_CC_Crl_Sta: start 18, 3 bit, big-endian, i-signal-type=PRIMITIVE, init-value=constant-reference=Init_CAN4_CC_Crl_Sta, base-type=uint8, implementation-data-type=uint8, transfer-property=TRIGGERED
          signal CAN4_CS_VCU1_CAN4: start 7, 8 bit, big-endian, i-signal-type=PRIMITIVE, init-value=constant-reference=Init_CAN4_CS_VCU1_CAN4, base-type=uint8, implementation-data-type=uint8, transfer-property=TRIGGERED
          signal CAN4_CTDCtrl: start 165, 2 bit, big-endian, i-signal-type=PRIMITIVE, init-value=constant-reference=Init_CAN4_CTDCtrl, base-type=uint8, implementation-data-type=uint8, transfer-property=TRIGGERED
          signal CAN4_CTDLockSW: start 215, 1 bit, big-endian, i-signal-type=PRIMITIVE, init-value=constant-reference=Init_CAN4_CTDLockSW, base-type=uint8, implementation-data-type=uint8, transfer-property=TRIGGERED
          signal CAN4_CTDUnlockSW: start 214, 1 bit, big-endian, i-signal-type=PRIMITIVE, init-value=constant-reference=Init_CAN4_CTDUnlockSW, base-type=uint8, implementation-data-type=uint8, transfer-property=TRIGGERED
          signal CAN4_CrashDetd: start 116, 1 bit, big-endian, i-signal-type=PRIMITIVE, init-value=constant-reference=Init_CAN4_CrashDetd, base-type=uint8, implementation-data-type=uint8, transfer-property=TRIGGERED
          signal CAN4_CtrlDrPwrStbA2: start 222, 1 bit, big-endian, i-signal-type=PRIMITIVE, init-value=constant-reference=Init_CAN4_CtrlDrPwrStbA2, base-type=uint8, implementation-data-type=uint8, transfer-property=TRIGGERED
          signal CAN4_CtrlFrBMSCCUCIR: start 200, 1 bit, big-endian, i-signal-type=PRIMITIVE, init-value=constant-reference=Init_CAN4_CtrlFrBMSCCUCIR, base-type=uint8, implementation-data-type=uint8, transfer-property=TRIGGERED
          signal CAN4_CtrlFrEDUINVERTER: start 201, 1 bit, big-endian, i-signal-type=PRIMITIVE, init-value=constant-reference=Init_CAN4_CtrlFrEDUINVERTER, base-type=uint8, implementation-data-type=uint8, transfer-property=TRIGGERED
          signal CAN4_CtrlFrIRC1: start 202, 1 bit, big-endian, i-signal-type=PRIMITIVE, init-value=constant-reference=Init_CAN4_CtrlFrIRC1, base-type=uint8, implementation-data-type=uint8, transfer-property=TRIGGERED
          signal CAN4_CtrlFrPwrStbA1P: start 203, 1 bit, big-endian, i-signal-type=PRIMITIVE, init-value=constant-reference=Init_CAN4_CtrlFrPwrStbA1P, base-type=uint8, implementation-data-type=uint8, transfer-property=TRIGGERED
          signal CAN4_DKCAuthSta: start 185, 2 bit, big-endian, i-signal-type=PRIMITIVE, init-value=constant-reference=Init_CAN4_DKCAuthSta, base-type=uint8, implementation-data-type=uint8, transfer-property=TRIGGERED
          signal CAN4_DKCTimeSN: start 39, 32 bit, big-endian, i-signal-type=PRIMITIVE, init-value=constant-reference=Init_CAN4_DKCTimeSN, base-type=uint32, implementation-data-type=uint32, transfer-property=TRIGGERED
          signal CAN4_Dimmer: start 110, 7 bit, big-endian, i-signal-type=PRIMITIVE, init-value=constant-reference=Init_CAN4_Dimmer, base-type=uint8, implementation-data-type=uint8, transfer-property=TRIGGERED
          signal CAN4_DimmerEN: start 100, 1 bit, big-endian, i-signal-type=PRIMITIVE, init-value=constant-reference=Init_CAN4_DimmerEN, base-type=uint8, implementation-data-type=uint8, transfer-property=TRIGGERED
          signal CAN4_DoorLockIND: start 156, 1 bit, big-endian, i-signal-type=PRIMITIVE, init-value=constant-reference=Init_CAN4_DoorLockIND, base-type=uint8, implementation-data-type=uint8, transfer-property=TRIGGERED
          signal CAN4_DrDoorSW: start 206, 1 bit, big-endian, i-signal-type=PRIMITIVE, init-value=constant-reference=Init_CAN4_DrDoorSW, base-type=uint8, implementation-data-type=uint8, transfer-property=TRIGGERED
          signal CAN4_Dr_SeatSta: start 23, 2 bit, big-endian, i-signal-type=PRIMITIVE, init-value=constant-reference=Init_CAN4_Dr_SeatSta, base-type=uint8, implementation-data-type=uint8, transfer-property=TRIGGERED
          signal CAN4_EquivAccPedalSWSta: start 103, 1 bit, big-endian, i-signal-type=PRIMITIVE, init-value=constant-reference=Init_CAN4_EquivAccPedalSWSta, base-type=uint8, implementation-data-type=uint8, transfer-property=TRIGGERED
          signal CAN4_FD_DKC_VehData_Err: start 183, 4 bit, big-endian, i-signal-type=PRIMITIVE, init-value=constant-reference=Init_CAN4_FD_DKC_VehData_Err, base-type=uint8, implementation-data-type=uint8, transfer-property=TRIGGERED
          signal CAN4_FD_DKC_VehData_Sta: start 171, 4 bit, big-endian, i-signal-type=PRIMITIVE, init-value=constant-reference=Init_CAN4_FD_DKC_VehData_Sta, base-type=uint8, implementation-data-type=uint8, transfer-property=TRIGGERED
          signal CAN4_FD_TBOX_DTCData_Err: start 191, 4 bit, big-endian, i-signal-type=PRIMITIVE, init-value=constant-reference=Init_CAN4_FD_TBOX_DTCData_Err, base-type=uint8, implementation-data-type=uint8, transfer-property=TRIGGERED
          signal CAN4_FD_TBOX_DTCData_Sta: start 179, 4 bit, big-endian, i-signal-type=PRIMITIVE, init-value=constant-reference=Init_CAN4_FD_TBOX_DTCData_Sta, base-type=uint8, implementation-data-type=uint8, transfer-property=TRIGGERED
          signal CAN4_FD_TBOX_VehData_Err: start 175, 4 bit, big-endian, i-signal-type=PRIMITIVE, init-value=constant-reference=Init_CAN4_FD_TBOX_VehData_Err, base-type=uint8, implementation-data-type=uint8, transfer-property=TRIGGERED
          signal CAN4_FD_TBOX_VehData_Sta: start 163, 4 bit, big-endian, i-signal-type=PRIMITIVE, init-value=constant-reference=Init_CAN4_FD_TBOX_VehData_Sta, base-type=uint8, implementation-data-type=uint8, transfer-property=TRIGGERED
          signal CAN4_Fr_ChargingDoorCtrl: start 159, 2 bit, big-endian, i-signal-type=PRIMITIVE, init-value=constant-reference=Init_CAN4_Fr_ChargingDoorCtrl, base-type=uint8, implementation-data-type=uint8, transfer-property=TRIGGERED
          signal CAN4_Fr_FogLamp: start 124, 1 bit, big-endian, i-signal-type=PRIMITIVE, init-value=constant-reference=Init_CAN4_Fr_FogLamp, base-type=uint8, implementation-data-type=uint8, transfer-property=TRIGGERED
          signal CAN4_Fr_Wiper_H: start 141, 1 bit, big-endian, i-signal-type=PRIMITIVE, init-value=constant-reference=Init_CAN4_Fr_Wiper_H, base-type=uint8, implementation-data-type=uint8, transfer-property=TRIGGERED
          signal CAN4_Fr_Wiper_L: start 142, 1 bit, big-endian, i-signal-type=PRIMITIVE, init-value=constant-reference=Init_CAN4_Fr_Wiper_L, base-type=uint8, implementation-data-type=uint8, transfer-property=TRIGGERED
          signal CAN4_HWResetSta: start 205, 2 bit, big-endian, i-signal-type=PRIMITIVE, init-value=constant-reference=Init_CAN4_HWResetSta, base-type=uint8, implementation-data-type=uint8, transfer-property=TRIGGERED
          signal CAN4_H_Beam: start 132, 1 bit, big-endian, i-signal-type=PRIMITIVE, init-value=constant-reference=Init_CAN4_H_Beam, base-type=uint8, implementation-data-type=uint8, transfer-property=TRIGGERED
          signal CAN4_H_Beam_ADB: start 24, 1 bit, big-endian, i-signal-type=PRIMITIVE, init-value=constant-reference=Init_CAN4_H_Beam_ADB, base-type=uint8, implementation-data-type=uint8, transfer-property=TRIGGERED
          signal CAN4_HazardSW: start 126, 1 bit, big-endian, i-signal-type=PRIMITIVE, init-value=constant-reference=Init_CAN4_HazardSW, base-type=uint8, implementation-data-type=uint8, transfer-property=TRIGGERED
          signal CAN4_HoodSW: start 157, 1 bit, big-endian, i-signal-type=PRIMITIVE, init-value=constant-reference=Init_CAN4_HoodSW, base-type=uint8, implementation-data-type=uint8, transfer-property=TRIGGERED
          signal CAN4_HornCtrl: start 102, 1 bit, big-endian, i-signal-type=PRIMITIVE, init-value=constant-reference=Init_CAN4_HornCtrl, base-type=uint8, implementation-data-type=uint8, transfer-property=TRIGGERED
          signal CAN4_LBSD: start 122, 1 bit, big-endian, i-signal-type=PRIMITIVE, init-value=constant-reference=Init_CAN4_LBSD, base-type=uint8, implementation-data-type=uint8, transfer-property=TRIGGERED
          signal CAN4_LDRL: start 134, 1 bit, big-endian, i-signal-type=PRIMITIVE, init-value=constant-reference=Init_CAN4_LDRL, base-type=uint8, implementation-data-type=uint8, transfer-property=TRIGGERED
          signal CAN4_LTurnLP: start 127, 1 bit, big-endian, i-signal-type=PRIMITIVE, init-value=constant-reference=Init_CAN4_LTurnLP, base-type=uint8, implementation-data-type=uint8, transfer-property=TRIGGERED
          signal CAN4_L_APM_WdwEnable: start 117, 1 bit, big-endian, i-signal-type=PRIMITIVE, init-value=constant-reference=Init_CAN4_L_APM_WdwEnable, base-type=uint8, implementation-data-type=uint8, transfer-property=TRIGGERED
          signal CAN4_L_Beam: start 131, 1 bit, big-endian, i-signal-type=PRIMITIVE, init-value=constant-reference=Init_CAN4_L_Beam, base-type=uint8, implementation-data-type=uint8, transfer-property=TRIGGERED
          signal CAN4_LampPwr: start 187, 1 bit, big-endian, i-signal-type=PRIMITIVE, init-value=constant-reference=Init_CAN4_LampPwr, base-type=uint8, implementation-data-type=uint8, transfer-property=TRIGGERED
          signal CAN4_LockSetting: start 118, 1 bit, big-endian, i-signal-type=PRIMITIVE, init-value=constant-reference=Init_CAN4_LockSetting, base-type=uint8, implementation-data-type=uint8, transfer-property=TRIGGERED
          signal CAN4_MSA_Crl_Sta: start 21, 3 bit, big-endian, i-signal-type=PRIMITIVE, init-value=constant-reference=Init_CAN4_MSA_Crl_Sta, base-type=uint8, implementation-data-type=uint8, transfer-property=TRIGGERED
          signal CAN4_MirrorCtrl: start 140, 2 bit, big-endian, i-signal-type=PRIMITIVE, init-value=constant-reference=Init_CAN4_MirrorCtrl, base-type=uint8, implementation-data-type=uint8, transfer-property=TRIGGERED
          signal CAN4_MirrorDefog: start 207, 1 bit, big-endian, i-signal-type=PRIMITIVE, init-value=constant-reference=Init_CAN4_MirrorDefog, base-type=uint8, implementation-data-type=uint8, transfer-property=TRIGGERED
          signal CAN4_PosLamp: start 133, 1 bit, big-endian, i-signal-type=PRIMITIVE, init-value=constant-reference=Init_CAN4_PosLamp, base-type=uint8, implementation-data-type=uint8, transfer-property=TRIGGERED
          signal CAN4_PsDoorSW: start 152, 1 bit, big-endian, i-signal-type=PRIMITIVE, init-value=constant-reference=Init_CAN4_PsDoorSW, base-type=uint8, implementation-data-type=uint8, transfer-property=TRIGGERED
          signal CAN4_PwrSta: start 28, 3 bit, big-endian, i-signal-type=PRIMITIVE, init-value=constant-reference=Init_CAN4_PwrSta, base-type=uint8, implementation-data-type=uint8, transfer-property=TRIGGERED
          signal CAN4_RBSD: start 123, 1 bit, big-endian, i-signal-type=PRIMITIVE, init-value=constant-reference=Init_CAN4_RBSD, base-type=uint8, implementation-data-type=uint8, transfer-property=TRIGGERED
          signal CAN4_RC_VCU1_CAN4: start 11, 4 bit, big-endian, i-signal-type=PRIMITIVE, init-value=constant-reference=Init_CAN4_RC_VCU1_CAN4, base-type=uint8, implementation-data-type=uint8, transfer-property=TRIGGERED
          signal CAN4_RDRL: start 135, 1 bit, big-endian, i-signal-type=PRIMITIVE, init-value=constant-reference=Init_CAN4_RDRL, base-type=uint8, implementation-data-type=uint8, transfer-property=TRIGGERED
          signal CAN4_RLDoorSW: start 153, 1 bit, big-endian, i-signal-type=PRIMITIVE, init-value=constant-reference=Init_CAN4_RLDoorSW, base-type=uint8, implementation-data-type=uint8, transfer-property=TRIGGERED
          signal CAN4_RRDoorSW: start 154, 1 bit, big-endian, i-signal-type=PRIMITIVE, init-value=constant-reference=Init_CAN4_RRDoorSW, base-type=uint8, implementation-data-type=uint8, transfer-property=TRIGGERED
          signal CAN4_RTurnLP: start 112, 1 bit, big-endian, i-signal-type=PRIMITIVE, init-value=constant-reference=Init_CAN4_RTurnLP, base-type=uint8, implementation-data-type=uint8, transfer-property=TRIGGERED
          signal CAN4_ReBrakeLPReq: start 25, 1 bit, big-endian, i-signal-type=PRIMITIVE, init-value=constant-reference=Init_CAN4_ReBrakeLPReq, base-type=uint8, implementation-data-type=uint8, transfer-property=TRIGGERED
          signal CAN4_ReverseLamp: start 120, 1 bit, big-endian, i-signal-type=PRIMITIVE, init-value=constant-reference=Init_CAN4_ReverseLamp, base-type=uint8, implementation-data-type=uint8, transfer-property=TRIGGERED
          signal CAN4_RoomLampH: start 99, 1 bit, big-endian, i-signal-type=PRIMITIVE, init-value=constant-reference=Init_CAN4_RoomLampH, base-type=uint8, implementation-data-type=uint8, transfer-property=TRIGGERED
          signal CAN4_RoomLampL: start 98, 1 bit, big-endian, i-signal-type=PRIMITIVE, init-value=constant-reference=Init_CAN4_RoomLampL, base-type=uint8, implementation-data-type=uint8, transfer-property=TRIGGERED
          signal CAN4_Rr_ChargingDoorCtrl: start 167, 2 bit, big-endian, i-signal-type=PRIMITIVE, init-value=constant-reference=Init_CAN4_Rr_ChargingDoorCtrl, base-type=uint8, implementation-data-type=uint8, transfer-property=TRIGGERED
          signal CAN4_Rr_Defog: start 136, 1 bit, big-endian, i-signal-type=PRIMITIVE, init-value=constant-reference=Init_CAN4_Rr_Defog, base-type=uint8, implementation-data-type=uint8, transfer-property=TRIGGERED
          signal CAN4_Rr_FogLamp: start 125, 1 bit, big-endian, i-signal-type=PRIMITIVE, init-value=constant-reference=Init_CAN4_Rr_FogLamp, base-type=uint8, implementation-data-type=uint8, transfer-property=TRIGGERED
          signal CAN4_Rr_Wiper: start 143, 1 bit, big-endian, i-signal-type=PRIMITIVE, init-value=constant-reference=Init_CAN4_Rr_Wiper, base-type=uint8, implementation-data-type=uint8, transfer-property=TRIGGERED
          signal CAN4_ShiftGearPosn: start 31, 3 bit, big-endian, i-signal-type=PRIMITIVE, init-value=constant-reference=Init_CAN4_ShiftGearPosn, base-type=uint8, implementation-data-type=uint8, transfer-property=TRIGGERED
          signal CAN4_TailgateHDSW: start 138, 1 bit, big-endian, i-signal-type=PRIMITIVE, init-value=constant-reference=Init_CAN4_TailgateHDSW, base-type=uint8, implementation-data-type=uint8, transfer-property=TRIGGERED
          signal CAN4_TailgateRemote: start 97, 2 bit, big-endian, i-signal-type=PRIMITIVE, init-value=constant-reference=Init_CAN4_TailgateRemote, base-type=uint8, implementation-data-type=uint8, transfer-property=TRIGGERED
          signal CAN4_Tailgate_SW: start 223, 1 bit, big-endian, i-signal-type=PRIMITIVE, init-value=constant-reference=Init_CAN4_Tailgate_SW, base-type=uint8, implementation-data-type=uint8, transfer-property=TRIGGERED
          signal CAN4_TimeSNDKCFbk: start 71, 32 bit, big-endian, i-signal-type=PRIMITIVE, init-value=constant-reference=Init_CAN4_TimeSNDKCFbk, base-type=uint32, implementation-data-type=uint32, transfer-property=TRIGGERED
          signal CAN4_TrunkRel: start 137, 1 bit, big-endian, i-signal-type=PRIMITIVE, init-value=constant-reference=Init_CAN4_TrunkRel, base-type=uint8, implementation-data-type=uint8, transfer-property=TRIGGERED
          signal CAN4_WasherCtrl: start 130, 2 bit, big-endian, i-signal-type=PRIMITIVE, init-value=constant-reference=Init_CAN4_WasherCtrl, base-type=uint8, implementation-data-type=uint8, transfer-property=TRIGGERED
          signal CAN4_WiperFixMode: start 128, 1 bit, big-endian, i-signal-type=PRIMITIVE, init-value=constant-reference=Init_CAN4_WiperFixMode, base-type=uint8, implementation-data-type=uint8, transfer-property=TRIGGERED
      frame CAN4_FD4_CE100_1: id 0x182, frame-length=64, can-addressing-mode=STANDARD, can-fd-frame-support=true, can-frame-rx-behavior=CAN-FD, can-frame-tx-behavior=CAN-FD
        pdu CAN4_FD4_CE100_1: length=64, minimum-delay=0.0, transmission-mode-true-timing={cyclic-timing=time-period=0.1, event-controlled-timing={number-of-repetitions=0, repetition-period=0}}, unused-bit-pattern=0
          mapping CAN4_SG_FD4_CE100_1: i-signal-group=CAN4_SG_FD4_CE100_1, start-position=0, transfer-property=TRIGGERED-ON-CHANGE
          signal CAN4_ACSubMode: start 187, 3 bit, big-endian, i-signal-type=PRIMITIVE, init-value=constant-reference=Init_CAN4_ACSubMode, base-type=uint8, implementation-data-type=uint8, transfer-property=PENDING
          signal CAN4_APTC_ActFrRiPwr: start 319, 8 bit, big-endian, i-signal-type=PRIMITIVE, init-value=constant-reference=Init_CAN4_APTC_ActFrRiPwr, base-type=uint8, implementation-data-type=uint8, transfer-property=TRIGGERED-ON-CHANGE
          signal CAN4_BatLoopActWtFlw: start 327, 8 bit, big-endian, i-signal-type=PRIMITIVE, init-value=constant-reference=Init_CAN4_BatLoopActWtFlw, base-type=uint8, implementation-data-type=uint8, transfer-property=PENDING
          signal CAN4_BatteryMode: start 134, 3 bit, big-endian, i-signal-type=PRIMITIVE, init-value=constant-reference=Init_CAN4_BatteryMode, base-type=uint8, implementation-data-type=uint8, transfer-property=PENDING
          signal CAN4_CCU_ACLampSts: start 22, 1 bit, big-endian, i-signal-type=PRIMITIVE, init-value=constant-reference=Init_CAN4_CCU_ACLampSts, base-type=uint8, implementation-data-type=uint8, transfer-property=PENDING
          signal CAN4_CCU_ACMaxLampSts: start 17, 1 bit, big-endian, i-signal-type=PRIMITIVE, init-value=constant-reference=Init_CAN4_CCU_ACMaxLampSts, base-type=uint8, implementation-data-type=uint8, transfer-property=PENDING
          signal CAN4_CCU_AutoLampSts: start 18, 1 bit, big-endian, i-signal-type=PRIMITIVE, init-value=constant-reference=Init_CAN4_CCU_AutoLampSts, base-type=uint8, implementation-data-type=uint8, transfer-property=PENDING
          signal CAN4_CCU_AutoMidLampSts: start 19, 1 bit, big-endian, i-signal-type=PRIMITIVE, init-value=constant-reference=Init_CAN4_CCU_AutoMidLampSts, base-type=uint8, implementation-data-type=uint8, transfer-property=PENDING
          signal CAN4_CCU_CbnPreACWkSts: start 211, 2 bit, big-endian, i-signal-type=PRIMITIVE, init-value=constant-reference=Init_CAN4_CCU_CbnPreACWkSts, base-type=uint8, implementation-data-type=uint8, transfer-property=PENDING
          signal CAN4_CCU_CbnPreEstimdTi: start 231, 6 bit, big-endian, i-signal-type=PRIMITIVE, init-value=constant-reference=Init_CAN4_CCU_CbnPreEstimdTi, base-type=uint8, implementation-data-type=uint8, transfer-property=PENDING
          signal CAN4_CCU_CbnPreSts: start 215, 2 bit, big-endian, i-signal-type=PRIMITIVE, init-value=constant-reference=Init_CAN4_CCU_CbnPreSts, base-type=uint8, implementation-data-type=uint8, transfer-property=PENDING
          signal CAN4_CCU_Dispaly_Request: start 21, 1 bit, big-endian, i-signal-type=PRIMITIVE, init-value=constant-reference=Init_CAN4_CCU_Dispaly_Request, base-type=uint8, implementation-data-type=uint8, transfer-property=PENDING
          signal CAN4_CCU_EcoSts: start 20, 1 bit, big-endian, i-signal-type=PRIMITIVE, init-value=constant-reference=Init_CAN4_CCU_EcoSts, base-type=uint8, implementation-data-type=uint8, transfer-property=PENDING
          signal CAN4_CCU_FrtOnOffLampSts: start 35, 1 bit, big-endian, i-signal-type=PRIMITIVE, init-value=constant-reference=Init_CAN4_CCU_FrtOnOffLampSts, base-type=uint8, implementation-data-type=uint8, transfer-property=PENDING
          signal CAN4_CCU_HEATMaxLampSts: start 23, 1 bit, big-endian, i-signal-type=PRIMITIVE, init-value=constant-reference=Init_CAN4_CCU_HEATMaxLampSts, base-type=uint8, implementation-data-type=uint8, transfer-property=PENDING
          signal CAN4_CCU_HiVoltageReq: start 199, 1 bit, big-endian, i-signal-type=PRIMITIVE, init-value=constant-reference=Init_CAN4_CCU_HiVoltageReq, base-type=uint8, implementation-data-type=uint8, transfer-property=PENDING
          signal CAN4_CCU_RrOnOffLampSts: start 39, 1 bit, big-endian, i-signal-type=PRIMITIVE, init-value=constant-reference=Init_CAN4_CCU_RrOnOffLampSts, base-type=uint8, implementation-data-type=uint8, transfer-property=PENDING
          signal CAN4_CCU_SyncLampSts: start 55, 1 bit, big-endian, i-signal-type=PRIMITIVE, init-value=constant-reference=Init_CAN4_CCU_SyncLampSts, base-type=uint8, implementation-data-type=uint8, transfer-property=PENDING
          signal CAN4_CabinMode: start 131, 4 bit, big-endian, i-signal-type=PRIMITIVE, init-value=constant-reference=Init_CAN4_CabinMode, base-type=uint8, implementation-data-type=uint8, transfer-property=PENDING
          signal CAN4_CoolgFanActDuty: start 335, 8 bit, big-endian, i-signal-type=PRIMITIVE, init-value=constant-reference=Init_CAN4_CoolgFanActDuty, base-type=uint8, implementation-data-type=uint8, transfer-property=TRIGGERED-ON-CHANGE
          signal CAN4_DeiceModReq: start 213, 2 bit, big-endian, i-signal-type=PRIMITIVE, init-value=constant-reference=Init_CAN4_DeiceModReq, base-type=uint8, implementation-data-type=uint8, transfer-property=PENDING
          signal CAN4_EDriveMode: start 79, 2 bit, big-endian, i-signal-type=PRIMITIVE, init-value=constant-reference=Init_CAN4_EDriveMode, base-type=uint8, implementation-data-type=uint8, transfer-property=PENDING
          signal CAN4_FDC_THCM_CLEVentY_Sta: start 374, 7 bit, big-endian, i-signal-type=PRIMITIVE, init-value=constant-reference=Init_CAN4_FDC_THCM_CLEVentY_Sta, base-type=uint8, implementation-data-type=uint8, transfer-property=PENDING
          signal CAN4_FDC_THCM_CLEVentZ_Sta: start 382, 7 bit, big-endian, i-signal-type=PRIMITIVE, init-value=constant-reference=Init_CAN4_FDC_THCM_CLEVentZ_Sta, base-type=uint8, implementation-data-type=uint8, transfer-property=PENDING
          signal CAN4_FDC_THCM_CLVent_Sta: start 359, 1 bit, big-endian, i-signal-type=PRIMITIVE, init-value=constant-reference=Init_CAN4_FDC_THCM_CLVent_Sta, base-type=uint8, implementation-data-type=uint8, transfer-property=TRIGGERED-ON-CHANGE
          signal CAN4_FDC_THCM_CREVentY_Sta: start 390, 7 bit, big-endian, i-signal-type=PRIMITIVE, init-value=constant-reference=Init_CAN4_FDC_THCM_CREVentY_Sta, base-type=uint8, implementation-data-type=uint8, transfer-property=PENDING
          signal CAN4_FDC_THCM_CREVentZ_Sta: start 398, 7 bit, big-endian, i-signal-type=PRIMITIVE, init-value=constant-reference=Init_CAN4_FDC_THCM_CREVentZ_Sta, base-type=uint8, implementation-data-type=uint8, transfer-property=PENDING
          signal CAN4_FDC_THCM_CRVent_Sta: start 367, 1 bit, big-endian, i-signal-type=PRIMITIVE, init-value=constant-reference=Init_CAN4_FDC_THCM_CRVent_Sta, base-type=uint8, implementation-data-type=uint8, transfer-property=TRIGGERED-ON-CHANGE
          signal CAN4_FDC_THCM_DrEVentMode_Sta: start 405, 3 bit, big-endian, i-signal-type=PRIMITIVE, init-value=constant-reference=Init_CAN4_FDC_THCM_DrEVentMode_Sta, base-type=uint8, implementation-data-type=uint8, transfer-property=TRIGGERED-ON-CHANGE
          signal CAN4_FDC_THCM_DrEVentY_Sta: start 342, 7 bit, big-endian, i-signal-type=PRIMITIVE, init-value=constant-reference=Init_CAN4_FDC_THCM_DrEVentY_Sta, base-type=uint8, implementation-data-type=uint8, transfer-property=PENDING
          signal CAN4_FDC_THCM_DrEVentZ_Sta: start 350, 7 bit, big-endian, i-signal-type=PRIMITIVE, init-value=constant-reference=Init_CAN4_FDC_THCM_DrEVentZ_Sta, base-type=uint8, implementation-data-type=uint8, transfer-property=PENDING
          signal CAN4_FDC_THCM_DrVent_Sta: start 343, 1 bit, big-endian, i-signal-type=PRIMITIVE, init-value=constant-reference=Init_CAN4_FDC_THCM_DrVent_Sta, base-type=uint8, implementation-data-type=uint8, transfer-property=TRIGGERED-ON-CHANGE
          signal CAN4_FDC_THCM_PsEVentMode_Sta: start 402, 3 bit, big-endian, i-signal-type=PRIMITIVE, init-value=constant-reference=Init_CAN4_FDC_THCM_PsEVentMode_Sta, base-type=uint8, implementation-data-type=uint8, transfer-property=TRIGGERED-ON-CHANGE
          signal CAN4_FDC_THCM_PsEVentY_Sta: start 358, 7 bit, big-endian, i-signal-type=PRIMITIVE, init-value=constant-reference=Init_CAN4_FDC_THCM_PsEVentY_Sta, base-type=uint8, implementation-data-type=uint8, transfer-property=PENDING
          signal CAN4_FDC_THCM_PsEVentZ_Sta: start 366, 7 bit, big-endian, i-signal-type=PRIMITIVE, init-value=constant-reference=Init_CAN4_FDC_THCM_PsEVentZ_Sta, base-type=uint8, implementation-data-type=uint8, transfer-property=PENDING
          signal CAN4_FDC_THCM_PsVent_Sta: start 351, 1 bit, big-endian, i-signal-type=PRIMITIVE, init-value=constant-reference=Init_CAN4_FDC_THCM_PsVent_Sta, base-type=uint8, implementation-data-type=uint8, transfer-property=TRIGGERED-ON-CHANGE
          signal CAN4_FD_Blower_Cmd: start 183, 8 bit, big-endian, i-signal-type=PRIMITIVE, init-value=constant-reference=Init_CAN4_FD_Blower_Cmd, base-type=uint8, implementation-data-type=uint8, transfer-property=TRIGGERED-ON-CHANGE
          signal CAN4_FD_Comp_Cmd: start 198, 15 bit, big-endian, i-signal-type=PRIMITIVE, init-value=constant-reference=Init_CAN4_FD_Comp_Cmd, base-type=uint16, implementation-data-type=uint16, transfer-property=TRIGGERED-ON-CHANGE
          signal CAN4_FD_EWP1_Cmd: start 311, 8 bit, big-endian, i-signal-type=PRIMITIVE, init-value=constant-reference=Init_CAN4_FD_EWP1_Cmd, base-type=uint8, implementation-data-type=uint8, transfer-property=PENDING
          signal CAN4_FD_EWP2_Cmd: start 303, 8 bit, big-endian, i-signal-type=PRIMITIVE, init-value=constant-reference=Init_CAN4_FD_EWP2_Cmd, base-type=uint8, implementation-data-type=uint8, transfer-property=PENDING
          signal CAN4_FD_EWP3_Cmd: start 295, 8 bit, big-endian, i-signal-type=PRIMITIVE, init-value=constant-reference=Init_CAN4_FD_EWP3_Cmd, base-type=uint8, implementation-data-type=uint8, transfer-property=PENDING
          signal CAN4_FD_EXV1_Cmd: start 209, 10 bit, big-endian, i-signal-type=PRIMITIVE, init-value=constant-reference=Init_CAN4_FD_EXV1_Cmd, base-type=uint16, implementation-data-type=uint16, transfer-property=PENDING
          signal CAN4_FD_EXV2_Cmd: start 225, 10 bit, big-endian, i-signal-type=PRIMITIVE, init-value=constant-reference=Init_CAN4_FD_EXV2_Cmd, base-type=uint16, implementation-data-type=uint16, transfer-property=PENDING
          signal CAN4_FD_FWV_Cmd: start 184, 1 bit, big-endian, i-signal-type=PRIMITIVE, init-value=constant-reference=Init_CAN4_FD_FWV_Cmd, base-type=uint8, implementation-data-type=uint8, transfer-property=PENDING
          signal CAN4_FD_FrLeAPTCHeatPwr_Cmd: start 263, 8 bit, big-endian, i-signal-type=PRIMITIVE, init-value=constant-reference=Init_CAN4_FD_FrLeAPTCHeatPwr_Cmd, base-type=uint8, implementation-data-type=uint8, transfer-property=TRIGGERED-ON-CHANGE
          signal CAN4_FD_FrRiAPTCHeatPwr_Cmd: start 255, 8 bit, big-endian, i-signal-type=PRIMITIVE, init-value=constant-reference=Init_CAN4_FD_FrRiAPTCHeatPwr_Cmd, base-type=uint8, implementation-data-type=uint8, transfer-property=TRIGGERED-ON-CHANGE
          signal CAN4_FD_FrWPTCHeatPwr_Cmd: start 279, 16 bit, big-endian, i-signal-type=PRIMITIVE, init-value=constant-reference=Init_CAN4_FD_FrWPTCHeatPwr_Cmd, base-type=uint16, implementation-data-type=uint16, transfer-property=TRIGGERED-ON-CHANGE
          signal CAN4_FD_RecyAuto_Cmd: start 127, 3 bit, big-endian, i-signal-type=PRIMITIVE, init-value=constant-reference=Init_CAN4_FD_RecyAuto_Cmd, base-type=uint8, implementation-data-type=uint8, transfer-property=PENDING
          signal CAN4_FD_RrAPTCHeatPwr_Cmd: start 271, 8 bit, big-endian, i-signal-type=PRIMITIVE, init-value=constant-reference=Init_CAN4_FD_RrAPTCHeatPwr_Cmd, base-type=uint8, implementation-data-type=uint8, transfer-property=TRIGGERED-ON-CHANGE
          signal CAN4_FD_SOTXV_Cmd: start 188, 1 bit, big-endian, i-signal-type=PRIMITIVE, init-value=constant-reference=Init_CAN4_FD_SOTXV_Cmd, base-type=uint8, implementation-data-type=uint8, transfer-property=PENDING
          signal CAN4_FD_SOV1_Cmd: start 189, 1 bit, big-endian, i-signal-type=PRIMITIVE, init-value=constant-reference=Init_CAN4_FD_SOV1_Cmd, base-type=uint8, implementation-data-type=uint8, transfer-property=PENDING
          signal CAN4_FD_SOV2_Cmd: start 190, 1 bit, big-endian, i-signal-type=PRIMITIVE, init-value=constant-reference=Init_CAN4_FD_SOV2_Cmd, base-type=uint8, implementation-data-type=uint8, transfer-property=PENDING
          signal CAN4_FD_SOV3_Cmd: start 191, 1 bit, big-endian, i-signal-type=PRIMITIVE, init-value=constant-reference=Init_CAN4_FD_SOV3_Cmd, base-type=uint8, implementation-data-type=uint8, transfer-property=PENDING
          signal CAN4_FD_TWV_Cmd: start 247, 8 bit, big-endian, i-signal-type=PRIMITIVE, init-value=constant-reference=Init_CAN4_FD_TWV_Cmd, base-type=uint8, implementation-data-type=uint8, transfer-property=PENDING
          signal CAN4_Fr_Coolantflow: start 77, 6 bit, big-endian, i-signal-type=PRIMITIVE, init-value=constant-reference=Init_CAN4_Fr_Coolantflow, base-type=uint8, implementation-data-type=uint8, transfer-property=PENDING
          signal CAN4_Fr_Coolanttemp: start 16, 9 bit, big-endian, i-signal-type=PRIMITIVE, init-value=constant-reference=Init_CAN4_Fr_Coolanttemp, base-type=uint16, implementation-data-type=uint16, transfer-property=PENDING
          signal CAN4_HPThermalRecoveryReq: start 71, 2 bit, big-endian, i-signal-type=PRIMITIVE, init-value=constant-reference=Init_CAN4_HPThermalRecoveryReq, base-type=uint8, implementation-data-type=uint8, transfer-property=PENDING
          signal CAN4_Rr_Coolantflow: start 166, 6 bit, big-endian, i-signal-type=PRIMITIVE, init-value=constant-reference=Init_CAN4_Rr_Coolantflow, base-type=uint8, implementation-data-type=uint8, transfer-property=PENDING
          signal CAN4_Rr_Coolanttemp: start 160, 9 bit, big-endian, i-signal-type=PRIMITIVE, init-value=constant-reference=Init_CAN4_Rr_Coolanttemp, base-type=uint16, implementation-data-type=uint16, transfer-property=PENDING
          signal CAN4_sigAirIntenZon1St: start 47, 4 bit, big-endian, i-signal-type=PRIMITIVE, init-value=constant-reference=Init_CAN4_sigAirIntenZon1St, base-type=uint8, implementation-data-type=uint8, transfer-property=PENDING
          signal CAN4_sigAirIntenZon3St: start 43, 4 bit, big-endian, i-signal-type=PRIMITIVE, init-value=constant-reference=Init_CAN4_sigAirIntenZon3St, base-type=uint8, implementation-data-type=uint8, transfer-property=PENDING
          signal CAN4_sigAmbAirT: start 111, 8 bit, big-endian, i-signal-type=PRIMITIVE, init-value=constant-reference=Init_CAN4_sigAmbAirT, base-type=uint8, implementation-data-type=uint8, transfer-property=PENDING
          signal CAN4_sigCbnAirT: start 103, 8 bit, big-endian, i-signal-type=PRIMITIVE, init-value=constant-reference=Init_CAN4_sigCbnAirT, base-type=uint8, implementation-data-type=uint8, transfer-property=PENDING
          signal CAN4_sigCbnPTCPwrAct: start 95, 8 bit, big-endian, i-signal-type=PRIMITIVE, init-value=constant-reference=Init_CAN4_sigCbnPTCPwrAct, base-type=uint8, implementation-data-type=uint8, transfer-property=PENDING
          signal CAN4_sigCbnSolarLeft: start 143, 8 bit, big-endian, i-signal-type=PRIMITIVE, init-value=constant-reference=Init_CAN4_sigCbnSolarLeft, base-type=uint8, implementation-data-type=uint8, transfer-property=PENDING
          signal CAN4_sigCbnSolarRight: start 119, 8 bit, big-endian, i-signal-type=PRIMITIVE, init-value=constant-reference=Init_CAN4_sigCbnSolarRight, base-type=uint8, implementation-data-type=uint8, transfer-property=PENDING
          signal CAN4_sigClmtCmprPwrAct: start 87, 8 bit, big-endian, i-signal-type=PRIMITIVE, init-value=constant-reference=Init_CAN4_sigClmtCmprPwrAct, base-type=uint8, implementation-data-type=uint8, transfer-property=PENDING
          signal CAN4_sigClntTHvBattOut: start 151, 8 bit, big-endian, i-signal-type=PRIMITIVE, init-value=constant-reference=Init_CAN4_sigClntTHvBattOut, base-type=uint8, implementation-data-type=uint8, transfer-property=PENDING
          signal CAN4_sigDfrstSt: start 54, 1 bit, big-endian, i-signal-type=PRIMITIVE, init-value=constant-reference=Init_CAN4_sigDfrstSt, base-type=uint8, implementation-data-type=uint8, transfer-property=PENDING
          signal CAN4_sigHvacSt: start 62, 1 bit, big-endian, i-signal-type=PRIMITIVE, init-value=constant-reference=Init_CAN4_sigHvacSt, base-type=uint8, implementation-data-type=uint8, transfer-property=PENDING
          signal CAN4_sigRecircSt: start 63, 1 bit, big-endian, i-signal-type=PRIMITIVE, init-value=constant-reference=Init_CAN4_sigRecircSt, base-type=uint8, implementation-data-type=uint8, transfer-property=PENDING
          signal CAN4_sigSetTempZon1St: start 69, 6 bit, big-endian, i-signal-type=PRIMITIVE, init-value=constant-reference=Init_CAN4_sigSetTempZon1St, base-type=uint8, implementation-data-type=uint8, transfer-property=PENDING
          signal CAN4_sigSetTempZon2St: start 61, 6 bit, big-endian, i-signal-type=PRIMITIVE, init-value=constant-reference=Init_CAN4_sigSetTempZon2St, base-type=uint8, implementation-data-type=uint8, transfer-property=PENDING
          signal CAN4_sigSetTempZon3St: start 53, 6 bit, big-endian, i-signal-type=PRIMITIVE, init-value=constant-reference=Init_CAN4_sigSetTempZon3St, base-type=uint8, implementation-data-type=uint8, transfer-property=PENDING
          signal CAN4_sigWindDirZon1St: start 38, 3 bit, big-endian, i-signal-type=PRIMITIVE, init-value=constant-reference=Init_CAN4_sigWindDirZon1St, base-type=uint8, implementation-data-type=uint8, transfer-property=PENDING
          signal CAN4_sigWindDirZon3St: start 34, 3 bit, big-endian, i-signal-type=PRIMITIVE, init-value=constant-reference=Init_CAN4_sigWindDirZon3St, base-type=uint8, implementation-data-type=uint8, transfer-property=PENDING
      frame CAN4_FD4_CE100_2: id 0x3A0, frame-length=32, can-addressing-mode=STANDARD, can-fd-frame-support=true, can-frame-rx-behavior=CAN-FD, can-frame-tx-behavior=CAN-FD
        pdu CAN4_FD4_CE100_2: length=32, minimum-delay=0.0, transmission-mode-true-timing={cyclic-timing=time-period=0.1, event-controlled-timing={number-of-repetitions=0, repetition-period=0}}, unused-bit-pattern=0
          mapping CAN4_SG_FD4_CE100_2: i-signal-group=CAN4_SG_FD4_CE100_2, start-position=0, transfer-property=TRIGGERED-ON-CHANGE
          signal CAN4_FD4_CE100_2_CS: start 7, 8 bit, big-endian, i-signal-type=PRIMITIVE, init-value=constant-reference=Init_CAN4_FD4_CE100_2_CS, base-type=uint8, implementation-data-type=uint8, transfer-property=TRIGGERED-ON-CHANGE
          signal CAN4_FD4_CE100_2_RC: start 11, 4 bit, big-endian, i-signal-type=PRIMITIVE, init-value=constant-reference=Init_CAN4_FD4_CE100_2_RC, base-type=uint8, implementation-data-type=uint8, transfer-property=TRIGGERED-ON-CHANGE
          signal CAN4_FDC_VCU_ReqHWReset_Cmd: start 20, 5 bit, big-endian, i-signal-type=PRIMITIVE, init-value=constant-reference=Init_CAN4_FDC_VCU_ReqHWReset_Cmd, base-type=uint8, implementation-data-type=uint8, transfer-property=TRIGGERED-ON-CHANGE
      frame CAN4_FD4_CE100_3: id 0x201, frame-length=32, can-addressing-mode=STANDARD, can-fd-frame-support=true, can-frame-rx-behavior=CAN-FD, can-frame-tx-behavior=CAN-FD
        pdu CAN4_FD4_CE100_3: length=32, minimum-delay=0.0, transmission-mode-true-timing={cyclic-timing=time-period=0.1, event-controlled-timing={number-of-repetitions=0, repetition-period=0}}, unused-bit-pattern=0
          mapping CAN4_SG_FD4_CE100_3: i-signal-group=CAN4_SG_FD4_CE100_3, start-position=0, transfer-property=TRIGGERED-ON-CHANGE
          signal CAN4_FDC_BCM_BBuzzer_Cmd: start 7, 1 bit, big-endian, i-signal-type=PRIMITIVE, init-value=constant-reference=Init_CAN4_FDC_BCM_BBuzzer_Cmd, base-type=uint8, implementation-data-type=uint8, transfer-property=TRIGGERED-ON-CHANGE
          signal CAN4_FDC_BCM_BBuzzerout_Cmd: start 6, 1 bit, big-endian, i-signal-type=PRIMITIVE, init-value=constant-reference=Init_CAN4_FDC_BCM_BBuzzerout_Cmd, base-type=uint8, implementation-data-type=uint8, transfer-property=TRIGGERED-ON-CHANGE
          signal CAN4_FDC_BCM_EmExitLight_Cmd: start 5, 1 bit, big-endian, i-signal-type=PRIMITIVE, init-value=constant-reference=Init_CAN4_FDC_BCM_EmExitLight_Cmd, base-type=uint8, implementation-data-type=uint8, transfer-property=TRIGGERED-ON-CHANGE
          signal CAN4_FDC_BCM_FrAtmoLamp_Cmd: start 4, 1 bit, big-endian, i-signal-type=PRIMITIVE, init-value=constant-reference=Init_CAN4_FDC_BCM_FrAtmoLamp_Cmd, base-type=uint8, implementation-data-type=uint8, transfer-property=TRIGGERED-ON-CHANGE
          signal CAN4_FDC_BCM_FrRmLampBright_Cmd: start 31, 4 bit, big-endian, i-signal-type=PRIMITIVE, init-value=constant-reference=Init_CAN4_FDC_BCM_FrRmLampBright_Cmd, base-type=uint8, implementation-data-type=uint8, transfer-property=TRIGGERED-ON-CHANGE
          signal CAN4_FDC_BCM_FrRoomlamp_Cmd: start 3, 1 bit, big-endian, i-signal-type=PRIMITIVE, init-value=constant-reference=Init_CAN4_FDC_BCM_FrRoomlamp_Cmd, base-type=uint8, implementation-data-type=uint8, transfer-property=TRIGGERED-ON-CHANGE
          signal CAN4_FDC_BCM_IBuzzerReq_Sta: start 23, 4 bit, big-endian, i-signal-type=PRIMITIVE, init-value=constant-reference=Init_CAN4_FDC_BCM_IBuzzerReq_Sta, base-type=uint8, implementation-data-type=uint8, transfer-property=TRIGGERED-ON-CHANGE
          signal CAN4_FDC_BCM_LSMLP_Cmd: start 2, 1 bit, big-endian, i-signal-type=PRIMITIVE, init-value=constant-reference=Init_CAN4_FDC_BCM_LSMLP_Cmd, base-type=uint8, implementation-data-type=uint8, transfer-property=TRIGGERED-ON-CHANGE
          signal CAN4_FDC_BCM_LTgateRel_Cmd: start 39, 1 bit, big-endian, i-signal-type=PRIMITIVE, init-value=constant-reference=Init_CAN4_FDC_BCM_LTgateRel_Cmd, base-type=uint8, implementation-data-type=uint8, transfer-property=TRIGGERED-ON-CHANGE
          signal CAN4_FDC_BCM_RSMLP_Cmd: start 1, 1 bit, big-endian, i-signal-type=PRIMITIVE, init-value=constant-reference=Init_CAN4_FDC_BCM_RSMLP_Cmd, base-type=uint8, implementation-data-type=uint8, transfer-property=TRIGGERED-ON-CHANGE
          signal CAN4_FDC_BCM_RTgateRel_Cmd: start 8, 1 bit, big-endian, i-signal-type=PRIMITIVE, init-value=constant-reference=Init_CAN4_FDC_BCM_RTgateRel_Cmd, base-type=uint8, implementation-data-type=uint8, transfer-property=TRIGGERED-ON-CHANGE
          signal CAN4_FDC_BCM_RevBuzzerout_Cmd: start 0, 1 bit, big-endian, i-signal-type=PRIMITIVE, init-value=constant-reference=Init_CAN4_FDC_BCM_RevBuzzerout_Cmd, base-type=uint8, implementation-data-type=uint8, transfer-property=TRIGGERED-ON-CHANGE
          signal CAN4_FDC_BCM_RrAtmoLamp_Cmd: start 15, 1 bit, big-endian, i-signal-type=PRIMITIVE, init-value=constant-reference=Init_CAN4_FDC_BCM_RrAtmoLamp_Cmd, base-type=uint8, implementation-data-type=uint8, transfer-property=TRIGGERED-ON-CHANGE
          signal CAN4_FDC_BCM_RrRmLampBright_Cmd: start 19, 4 bit, big-endian, i-signal-type=PRIMITIVE, init-value=constant-reference=Init_CAN4_FDC_BCM_RrRmLampBright_Cmd, base-type=uint8, implementation-data-type=uint8, transfer-property=TRIGGERED-ON-CHANGE
          signal CAN4_FDC_BCM_RrRoomlamp_Cmd: start 14, 1 bit, big-endian, i-signal-type=PRIMITIVE, init-value=constant-reference=Init_CAN4_FDC_BCM_RrRoomlamp_Cmd, base-type=uint8, implementation-data-type=uint8, transfer-property=TRIGGERED-ON-CHANGE
          signal CAN4_FDC_BCM_STurnLpLeft_Cmd: start 13, 1 bit, big-endian, i-signal-type=PRIMITIVE, init-value=constant-reference=Init_CAN4_FDC_BCM_STurnLpLeft_Cmd, base-type=uint8, implementation-data-type=uint8, transfer-property=TRIGGERED-ON-CHANGE
          signal CAN4_FDC_BCM_STurnLpRight_Cmd: start 12, 1 bit, big-endian, i-signal-type=PRIMITIVE, init-value=constant-reference=Init_CAN4_FDC_BCM_STurnLpRight_Cmd, base-type=uint8, implementation-data-type=uint8, transfer-property=TRIGGERED-ON-CHANGE
          signal CAN4_FDC_BCM_TgateHDSWL_Sta: start 25, 1 bit, big-endian, i-signal-type=PRIMITIVE, init-value=constant-reference=Init_CAN4_FDC_BCM_TgateHDSWL_Sta, base-type=uint8, implementation-data-type=uint8, transfer-property=TRIGGERED-ON-CHANGE
          signal CAN4_FDC_BCM_TgateHDSWR_Sta: start 24, 1 bit, big-endian, i-signal-type=PRIMITIVE, init-value=constant-reference=Init_CAN4_FDC_BCM_TgateHDSWR_Sta, base-type=uint8, implementation-data-type=uint8, transfer-property=TRIGGERED-ON-CHANGE
          signal CAN4_FDC_BCM_TgateSWL_Sta: start 27, 1 bit, big-endian, i-signal-type=PRIMITIVE, init-value=constant-reference=Init_CAN4_FDC_BCM_TgateSWL_Sta, base-type=uint8, implementation-data-type=uint8, transfer-property=TRIGGERED-ON-CHANGE
          signal CAN4_FDC_BCM_TgateSWR_Sta: start 26, 1 bit, big-endian, i-signal-type=PRIMITIVE, init-value=constant-reference=Init_CAN4_FDC_BCM_TgateSWR_Sta, base-type=uint8, implementation-data-type=uint8, transfer-property=TRIGGERED-ON-CHANGE
          signal CAN4_FDC_BCM_TurnLpLActive_Cmd: start 11, 1 bit, big-endian, i-signal-type=PRIMITIVE, init-value=constant-reference=Init_CAN4_FDC_BCM_TurnLpLActive_Cmd, base-type=uint8, implementation-data-type=uint8, transfer-property=TRIGGERED-ON-CHANGE
          signal CAN4_FDC_BCM_TurnLpRActive_Cmd: start 10, 1 bit, big-endian, i-signal-type=PRIMITIVE, init-value=constant-reference=Init_CAN4_FDC_BCM_TurnLpRActive_Cmd, base-type=uint8, implementation-data-type=uint8, transfer-property=TRIGGERED-ON-CHANGE
          signal CAN4_FDC_BCM_innerBuzzer_Cmd: start 9, 1 bit, big-endian, i-signal-type=PRIMITIVE, init-value=constant-reference=Init_CAN4_FDC_BCM_innerBuzzer_Cmd, base-type=uint8, implementation-data-type=uint8, transfer-property=TRIGGERED-ON-CHANGE
      frame CAN4_FD4_CE200_0: id 0x217, frame-length=32, can-addressing-mode=STANDARD, can-fd-frame-support=true, can-frame-rx-behavior=CAN-FD, can-frame-tx-behavior=CAN-FD
        pdu CAN4_FD4_CE200_0: length=32, minimum-delay=0.0, transmission-mode-true-timing={cyclic-timing=time-period=0.2, event-controlled-timing={number-of-repetitions=0, repetition-period=0}}, unused-bit-pattern=0
          mapping CAN4_SG_FD4_CE200_0: i-signal-group=CAN4_SG_FD4_CE200_0, start-position=0, transfer-property=TRIGGERED-ON-CHANGE
          signal CAN4_AmbLightBreath1: start 98, 3 bit, big-endian, i-signal-type=PRIMITIVE, init-value=constant-reference=Init_CAN4_AmbLightBreath1, base-type=uint8, implementation-data-type=uint8, transfer-property=TRIGGERED-ON-CHANGE
          signal CAN4_AmbLightBreath2: start 101, 3 bit, big-endian, i-signal-type=PRIMITIVE, init-value=constant-reference=Init_CAN4_AmbLightBreath2, base-type=uint8, implementation-data-type=uint8, transfer-property=TRIGGERED-ON-CHANGE
          signal CAN4_AmbLightBreath3: start 106, 3 bit, big-endian, i-signal-type=PRIMITIVE, init-value=constant-reference=Init_CAN4_AmbLightBreath3, base-type=uint8, implementation-data-type=uint8, transfer-property=TRIGGERED-ON-CHANGE
          signal CAN4_AmbLightBreath4: start 109, 3 bit, big-endian, i-signal-type=PRIMITIVE, init-value=constant-reference=Init_CAN4_AmbLightBreath4, base-type=uint8, implementation-data-type=uint8, transfer-property=TRIGGERED-ON-CHANGE
          signal CAN4_AmbLightBreath5: start 114, 3 bit, big-endian, i-signal-type=PRIMITIVE, init-value=constant-reference=Init_CAN4_AmbLightBreath5, base-type=uint8, implementation-data-type=uint8, transfer-property=TRIGGERED-ON-CHANGE
          signal CAN4_AmbLightBreath6: start 117, 3 bit, big-endian, i-signal-type=PRIMITIVE, init-value=constant-reference=Init_CAN4_AmbLightBreath6, base-type=uint8, implementation-data-type=uint8, transfer-property=TRIGGERED-ON-CHANGE
          signal CAN4_AmbLightBrightness1: start 54, 7 bit, big-endian, i-signal-type=PRIMITIVE, init-value=constant-reference=Init_CAN4_AmbLightBrightness1, base-type=uint8, implementation-data-type=uint8, transfer-property=TRIGGERED-ON-CHANGE
          signal CAN4_AmbLightBrightness2: start 62, 7 bit, big-endian, i-signal-type=PRIMITIVE, init-value=constant-reference=Init_CAN4_AmbLightBrightness2, base-type=uint8, implementation-data-type=uint8, transfer-property=TRIGGERED-ON-CHANGE
          signal CAN4_AmbLightBrightness3: start 70, 7 bit, big-endian, i-signal-type=PRIMITIVE, init-value=constant-reference=Init_CAN4_AmbLightBrightness3, base-type=uint8, implementation-data-type=uint8, transfer-property=TRIGGERED-ON-CHANGE
          signal CAN4_AmbLightBrightness4: start 78, 7 bit, big-endian, i-signal-type=PRIMITIVE, init-value=constant-reference=Init_CAN4_AmbLightBrightness4, base-type=uint8, implementation-data-type=uint8, transfer-property=TRIGGERED-ON-CHANGE
          signal CAN4_AmbLightBrightness5: start 86, 7 bit, big-endian, i-signal-type=PRIMITIVE, init-value=constant-reference=Init_CAN4_AmbLightBrightness5, base-type=uint8, implementation-data-type=uint8, transfer-property=TRIGGERED-ON-CHANGE
          signal CAN4_AmbLightBrightness6: start 94, 7 bit, big-endian, i-signal-type=PRIMITIVE, init-value=constant-reference=Init_CAN4_AmbLightBrightness6, base-type=uint8, implementation-data-type=uint8, transfer-property=TRIGGERED-ON-CHANGE
          signal CAN4_AmbLightColor1: start 5, 6 bit, big-endian, i-signal-type=PRIMITIVE, init-value=constant-reference=Init_CAN4_AmbLightColor1, base-type=uint8, implementation-data-type=uint8, transfer-property=TRIGGERED-ON-CHANGE
          signal CAN4_AmbLightColor2: start 13, 6 bit, big-endian, i-signal-type=PRIMITIVE, init-value=constant-reference=Init_CAN4_AmbLightColor2, base-type=uint8, implementation-data-type=uint8, transfer-property=TRIGGERED-ON-CHANGE
          signal CAN4_AmbLightColor3: start 21, 6 bit, big-endian, i-signal-type=PRIMITIVE, init-value=constant-reference=Init_CAN4_AmbLightColor3, base-type=uint8, implementation-data-type=uint8, transfer-property=TRIGGERED-ON-CHANGE
          signal CAN4_AmbLightColor4: start 29, 6 bit, big-endian, i-signal-type=PRIMITIVE, init-value=constant-reference=Init_CAN4_AmbLightColor4, base-type=uint8, implementation-data-type=uint8, transfer-property=TRIGGERED-ON-CHANGE
          signal CAN4_AmbLightColor5: start 37, 6 bit, big-endian, i-signal-type=PRIMITIVE, init-value=constant-reference=Init_CAN4_AmbLightColor5, base-type=uint8, implementation-data-type=uint8, transfer-property=TRIGGERED-ON-CHANGE
          signal CAN4_AmbLightColor6: start 45, 6 bit, big-endian, i-signal-type=PRIMITIVE, init-value=constant-reference=Init_CAN4_AmbLightColor6, base-type=uint8, implementation-data-type=uint8, transfer-property=TRIGGERED-ON-CHANGE
          signal CAN4_BCM_Buzzer_Req: start 63, 1 bit, big-endian, i-signal-type=PRIMITIVE, init-value=constant-reference=Init_CAN4_BCM_Buzzer_Req, base-type=uint8, implementation-data-type=uint8, transfer-property=TRIGGERED-ON-CHANGE
          signal CAN4_FDC_BCM_ATCtrl_Cmd: start 103, 2 bit, big-endian, i-signal-type=PRIMITIVE, init-value=constant-reference=Init_CAN4_FDC_BCM_ATCtrl_Cmd, base-type=uint8, implementation-data-type=uint8, transfer-property=TRIGGERED-ON-CHANGE
          signal CAN4_FDC_BCM_DimSw: start 95, 1 bit, big-endian, i-signal-type=PRIMITIVE, init-value=constant-reference=Init_CAN4_FDC_BCM_DimSw, base-type=uint8, implementation-data-type=uint8, transfer-property=TRIGGERED-ON-CHANGE
          signal CAN4_FDC_BCM_FWasSw_Sta: start 127, 2 bit, big-endian, i-signal-type=PRIMITIVE, init-value=constant-reference=Init_CAN4_FDC_BCM_FWasSw_Sta, base-type=uint8, implementation-data-type=uint8, transfer-property=TRIGGERED-ON-CHANGE
          signal CAN4_FDC_BCM_FWipSw_Sta: start 135, 3 bit, big-endian, i-signal-type=PRIMITIVE, init-value=constant-reference=Init_CAN4_FDC_BCM_FWipSw_Sta, base-type=uint8, implementation-data-type=uint8, transfer-property=TRIGGERED-ON-CHANGE
          signal CAN4_FDC_BCM_HazardIND_Cmd: start 167, 1 bit, big-endian, i-signal-type=PRIMITIVE, init-value=constant-reference=Init_CAN4_FDC_BCM_HazardIND_Cmd, base-type=uint8, implementation-data-type=uint8, transfer-property=TRIGGERED-ON-CHANGE
          signal CAN4_FDC_BCM_LockAlarm_Cmd: start 111, 2 bit, big-endian, i-signal-type=PRIMITIVE, init-value=constant-reference=Init_CAN4_FDC_BCM_LockAlarm_Cmd, base-type=uint8, implementation-data-type=uint8, transfer-property=TRIGGERED-ON-CHANGE
          signal CAN4_FDC_BCM_OutMode_Cmd: start 163, 4 bit, big-endian, i-signal-type=PRIMITIVE, init-value=constant-reference=Init_CAN4_FDC_BCM_OutMode_Cmd, base-type=uint8, implementation-data-type=uint8, transfer-property=PENDING
          signal CAN4_FDC_BCM_PTGOpenHeight_Sta: start 125, 3 bit, big-endian, i-signal-type=PRIMITIVE, init-value=constant-reference=Init_CAN4_FDC_BCM_PTGOpenHeight_Sta, base-type=uint8, implementation-data-type=uint8, transfer-property=TRIGGERED-ON-CHANGE
          signal CAN4_FDC_BCM_PassSW_Sta: start 55, 1 bit, big-endian, i-signal-type=PRIMITIVE, init-value=constant-reference=Init_CAN4_FDC_BCM_PassSW_Sta, base-type=uint8, implementation-data-type=uint8, transfer-property=TRIGGERED-ON-CHANGE
          signal CAN4_FDC_BCM_TurnSwTSetSta_Sta: start 39, 2 bit, big-endian, i-signal-type=PRIMITIVE, init-value=constant-reference=Init_CAN4_FDC_BCM_TurnSwTSetSta_Sta, base-type=uint8, implementation-data-type=uint8, transfer-property=TRIGGERED-ON-CHANGE
          signal CAN4_FDC_BCM_TurnSw_Sta: start 119, 2 bit, big-endian, i-signal-type=PRIMITIVE, init-value=constant-reference=Init_CAN4_FDC_BCM_TurnSw_Sta, base-type=uint8, implementation-data-type=uint8, transfer-property=TRIGGERED-ON-CHANGE
          signal CAN4_FDC_BCM_UserHeightSet_Sta: start 129, 10 bit, big-endian, i-signal-type=PRIMITIVE, init-value=constant-reference=Init_CAN4_FDC_BCM_UserHeightSet_Sta, base-type=uint16, implementation-data-type=uint16, transfer-property=TRIGGERED-ON-CHANGE
          signal CAN4_FDC_BCM_UserNow_Sta: start 122, 3 bit, big-endian, i-signal-type=PRIMITIVE, init-value=constant-reference=Init_CAN4_FDC_BCM_UserNow_Sta, base-type=uint8, implementation-data-type=uint8, transfer-property=TRIGGERED-ON-CHANGE
          signal CAN4_FDC_DKC_CommandToBCM_Cmd: start 159, 4 bit, big-endian, i-signal-type=PRIMITIVE, init-value=constant-reference=Init_CAN4_FDC_DKC_CommandToBCM_Cmd, base-type=uint8, implementation-data-type=uint8, transfer-property=TRIGGERED-ON-CHANGE
          signal CAN4_FDC_DKC_DKeyAreaPE_Sta: start 47, 2 bit, big-endian, i-signal-type=PRIMITIVE, init-value=constant-reference=Init_CAN4_FDC_DKC_DKeyAreaPE_Sta, base-type=uint8, implementation-data-type=uint8, transfer-property=TRIGGERED-ON-CHANGE
          signal CAN4_FDC_DKC_SPTGDet_Cmd: start 131, 1 bit, big-endian, i-signal-type=PRIMITIVE, init-value=constant-reference=Init_CAN4_FDC_DKC_SPTGDet_Cmd, base-type=uint8, implementation-data-type=uint8, transfer-property=TRIGGERED-ON-CHANGE
          signal CAN4_FDC_DKC_SPTGOpen_Cmd: start 130, 1 bit, big-endian, i-signal-type=PRIMITIVE, init-value=constant-reference=Init_CAN4_FDC_DKC_SPTGOpen_Cmd, base-type=uint8, implementation-data-type=uint8, transfer-property=TRIGGERED-ON-CHANGE
          signal CAN4_FDC_EChrg_SW_Sta: start 175, 2 bit, big-endian, i-signal-type=PRIMITIVE, init-value=constant-reference=Init_CAN4_FDC_EChrg_SW_Sta, base-type=uint8, implementation-data-type=uint8, transfer-property=TRIGGERED-ON-CHANGE
          signal CAN4_FDC_THCM_ACTInitial_Cmd: start 132, 1 bit, big-endian, i-signal-type=PRIMITIVE, init-value=constant-reference=Init_CAN4_FDC_THCM_ACTInitial_Cmd, base-type=uint8, implementation-data-type=uint8, transfer-property=TRIGGERED-ON-CHANGE
          signal CAN4_FDC_THCM_AirIntZ3_Sta: start 166, 3 bit, big-endian, i-signal-type=PRIMITIVE, init-value=constant-reference=Init_CAN4_FDC_THCM_AirIntZ3_Sta, base-type=uint8, implementation-data-type=uint8, transfer-property=TRIGGERED-ON-CHANGE
          signal CAN4_FDHandleCmd: start 31, 2 bit, big-endian, i-signal-type=PRIMITIVE, init-value=constant-reference=Init_CAN4_FDHandleCmd, base-type=uint8, implementation-data-type=uint8, transfer-property=TRIGGERED-ON-CHANGE
          signal CAN4_FDLHandleLampCmd: start 87, 1 bit, big-endian, i-signal-type=PRIMITIVE, init-value=constant-reference=Init_CAN4_FDLHandleLampCmd, base-type=uint8, implementation-data-type=uint8, transfer-property=TRIGGERED-ON-CHANGE
          signal CAN4_FDRHandleLampCmd: start 79, 1 bit, big-endian, i-signal-type=PRIMITIVE, init-value=constant-reference=Init_CAN4_FDRHandleLampCmd, base-type=uint8, implementation-data-type=uint8, transfer-property=TRIGGERED-ON-CHANGE
          signal CAN4_WelcomeLight: start 23, 2 bit, big-endian, i-signal-type=PRIMITIVE, init-value=constant-reference=Init_CAN4_WelcomeLight, base-type=uint8, implementation-data-type=uint8, transfer-property=TRIGGERED-ON-CHANGE
      frame CAN4_FD4_OTA1: id 0x438, frame-length=12, can-addressing-mode=STANDARD, can-fd-frame-support=true, can-frame-rx-behavior=CAN-FD, can-frame-tx-behavior=CAN-FD
        pdu CAN4_FD4_OTA1: length=12, minimum-delay=0.0, transmission-mode-true-timing={cyclic-timing=time-period=0.2, event-controlled-timing={number-of-repetitions=0, repetition-period=0}}, unused-bit-pattern=0
          mapping CAN4_SG_FD4_OTA1: i-signal-group=CAN4_SG_FD4_OTA1, start-position=0, transfer-property=TRIGGERED-ON-CHANGE
          signal CAN4_OTA_DL_Available: start 8, 1 bit, big-endian, i-signal-type=PRIMITIVE, init-value=constant-reference=Init_CAN4_OTA_DL_Available, base-type=uint8, implementation-data-type=uint8, transfer-property=TRIGGERED-ON-CHANGE
          signal CAN4_OTA_DL_Speed: start 27, 20 bit, big-endian, i-signal-type=PRIMITIVE, init-value=constant-reference=Init_CAN4_OTA_DL_Speed, base-type=uint32, implementation-data-type=uint32, transfer-property=TRIGGERED-ON-CHANGE
          signal CAN4_OTA_Debug_Code: start 79, 8 bit, big-endian, i-signal-type=PRIMITIVE, init-value=constant-reference=Init_CAN4_OTA_Debug_Code, base-type=uint8, implementation-data-type=uint8, transfer-property=PENDING
          signal CAN4_OTA_Emergency_Sta: start 61, 2 bit, big-endian, i-signal-type=PRIMITIVE, init-value=constant-reference=Init_CAN4_OTA_Emergency_Sta, base-type=uint8, implementation-data-type=uint8, transfer-property=TRIGGERED-ON-CHANGE
          signal CAN4_OTA_InVehicle_FW: start 29, 2 bit, big-endian, i-signal-type=PRIMITIVE, init-value=constant-reference=Init_CAN4_OTA_InVehicle_FW, base-type=uint8, implementation-data-type=uint8, transfer-property=TRIGGERED-ON-CHANGE
          signal CAN4_OTA_Lock_Req: start 31, 1 bit, big-endian, i-signal-type=PRIMITIVE, init-value=constant-reference=Init_CAN4_OTA_Lock_Req, base-type=uint8, implementation-data-type=uint8, transfer-property=TRIGGERED-ON-CHANGE
          signal CAN4_OTA_MDA_Status: start 52, 5 bit, big-endian, i-signal-type=PRIMITIVE, init-value=constant-reference=Init_CAN4_OTA_MDA_Status, base-type=uint8, implementation-data-type=uint8, transfer-property=TRIGGERED-ON-CHANGE
          signal CAN4_OTA_Mode: start 9, 1 bit, big-endian, i-signal-type=PRIMITIVE, init-value=constant-reference=Init_CAN4_OTA_Mode, base-type=uint8, implementation-data-type=uint8, transfer-property=TRIGGERED-ON-CHANGE
          signal CAN4_OTA_Network_Type: start 11, 2 bit, big-endian, i-signal-type=PRIMITIVE, init-value=constant-reference=Init_CAN4_OTA_Network_Type, base-type=uint8, implementation-data-type=uint8, transfer-property=TRIGGERED-ON-CHANGE
          signal CAN4_OTA_Permit_Agreed: start 63, 1 bit, big-endian, i-signal-type=PRIMITIVE, init-value=constant-reference=Init_CAN4_OTA_Permit_Agreed, base-type=uint8, implementation-data-type=uint8, transfer-property=PENDING
          signal CAN4_OTA_Progress_Rate: start 7, 8 bit, big-endian, i-signal-type=PRIMITIVE, init-value=constant-reference=Init_CAN4_OTA_Progress_Rate, base-type=uint8, implementation-data-type=uint8, transfer-property=TRIGGERED-ON-CHANGE
          signal CAN4_OTA_Remained_Time: start 58, 11 bit, big-endian, i-signal-type=PRIMITIVE, init-value=constant-reference=Init_CAN4_OTA_Remained_Time, base-type=uint16, implementation-data-type=uint16, transfer-property=PENDING
          signal CAN4_OTA_TBOXResetReq: start 30, 1 bit, big-endian, i-signal-type=PRIMITIVE, init-value=constant-reference=Init_CAN4_OTA_TBOXResetReq, base-type=uint8, implementation-data-type=uint8, transfer-property=TRIGGERED-ON-CHANGE
          signal CAN4_OTA_Update_Available: start 62, 1 bit, big-endian, i-signal-type=PRIMITIVE, init-value=constant-reference=Init_CAN4_OTA_Update_Available, base-type=uint8, implementation-data-type=uint8, transfer-property=TRIGGERED-ON-CHANGE
          signal CAN4_OTA_Updating_ECU_8bit: start 23, 8 bit, big-endian, i-signal-type=PRIMITIVE, init-value=constant-reference=Init_CAN4_OTA_Updating_ECU_8bit, base-type=uint8, implementation-data-type=uint8, transfer-property=TRIGGERED-ON-CHANGE
      frame CAN4_GW4_CE100_0: id 0x253, frame-length=32, can-addressing-mode=STANDARD, can-fd-frame-support=true, can-frame-rx-behavior=CAN-FD, can-frame-tx-behavior=CAN-FD
        pdu CAN4_GW4_CE100_0: length=32, minimum-delay=0.0, transmission-mode-true-timing={cyclic-timing=time-period=0.1, event-controlled-timing={number-of-repetitions=0, repetition-period=0}}, unused-bit-pattern=0
          mapping CAN4_SG_GW4_CE100_0: i-signal-group=CAN4_SG_GW4_CE100_0, start-position=0, transfer-property=TRIGGERED-ON-CHANGE
          mapping CAN4_SG_CGW_GW4_CE100_0: i-signal-group=CAN4_SG_CGW_GW4_CE100_0, start-position=0, transfer-property=TRIGGERED-ON-CHANGE
          signal CAN4_AVM_parking_excute: start 151, 2 bit, big-endian, i-signal-type=PRIMITIVE, init-value=constant-reference=Init_CAN4_AVM_parking_excute, base-type=uint8, implementation-data-type=uint8, transfer-property=TRIGGERED-ON-CHANGE
          signal CAN4_Approach_Unlock_SW: start 15, 1 bit, big-endian, i-signal-type=PRIMITIVE, init-value=constant-reference=Init_CAN4_Approach_Unlock_SW, base-type=uint8, implementation-data-type=uint8, transfer-property=TRIGGERED-ON-CHANGE
          signal CAN4_BrkPedalPos: start 135, 8 bit, big-endian, i-signal-type=PRIMITIVE, init-value=constant-reference=Init_CAN4_BrkPedalPos, base-type=uint8, implementation-data-type=uint8, transfer-property=TRIGGERED-ON-CHANGE
          signal CAN4_BrkPedalPos_Sta: start 103, 1 bit, big-endian, i-signal-type=PRIMITIVE, init-value=constant-reference=Init_CAN4_BrkPedalPos_Sta, base-type=uint8, implementation-data-type=uint8, transfer-property=TRIGGERED-ON-CHANGE
          signal CAN4_BrkSw_Sta: start 31, 1 bit, big-endian, i-signal-type=PRIMITIVE, init-value=constant-reference=Init_CAN4_BrkSw_Sta, base-type=uint8, implementation-data-type=uint8, transfer-property=TRIGGERED-ON-CHANGE
          signal CAN4_BrkSw_V: start 111, 1 bit, big-endian, i-signal-type=PRIMITIVE, init-value=constant-reference=Init_CAN4_BrkSw_V, base-type=uint8, implementation-data-type=uint8, transfer-property=TRIGGERED-ON-CHANGE
          signal CAN4_ChrgInLockReq: start 87, 2 bit, big-endian, i-signal-type=PRIMITIVE, init-value=constant-reference=Init_CAN4_ChrgInLockReq, base-type=uint8, implementation-data-type=uint8, transfer-property=TRIGGERED-ON-CHANGE
          signal CAN4_ChrgPlugSta: start 183, 2 bit, big-endian, i-signal-type=PRIMITIVE, init-value=constant-reference=Init_CAN4_ChrgPlugSta, base-type=uint8, implementation-data-type=uint8, transfer-property=TRIGGERED-ON-CHANGE
          signal CAN4_DSEAT_anti_set: start 39, 1 bit, big-endian, i-signal-type=PRIMITIVE, init-value=constant-reference=Init_CAN4_DSEAT_anti_set, base-type=uint8, implementation-data-type=uint8, transfer-property=TRIGGERED-ON-CHANGE
          signal CAN4_DSEAT_entryfun_set: start 47, 1 bit, big-endian, i-signal-type=PRIMITIVE, init-value=constant-reference=Init_CAN4_DSEAT_entryfun_set, base-type=uint8, implementation-data-type=uint8, transfer-property=TRIGGERED-ON-CHANGE
          signal CAN4_DSEAT_vent_req: start 95, 3 bit, big-endian, i-signal-type=PRIMITIVE, init-value=constant-reference=Init_CAN4_DSEAT_vent_req, base-type=uint8, implementation-data-type=uint8, transfer-property=TRIGGERED-ON-CHANGE
          signal CAN4_Distance_unit: start 71, 1 bit, big-endian, i-signal-type=PRIMITIVE, init-value=constant-reference=Init_CAN4_Distance_unit, base-type=uint8, implementation-data-type=uint8, transfer-property=TRIGGERED-ON-CHANGE
          signal CAN4_ExtChrgSta: start 181, 2 bit, big-endian, i-signal-type=PRIMITIVE, init-value=constant-reference=Init_CAN4_ExtChrgSta, base-type=uint8, implementation-data-type=uint8, transfer-property=TRIGGERED-ON-CHANGE
          signal CAN4_FDC_PTG_inner_SW_2: start 5, 2 bit, big-endian, i-signal-type=PRIMITIVE, init-value=constant-reference=Init_CAN4_FDC_PTG_inner_SW_2, base-type=uint8, implementation-data-type=uint8, transfer-property=TRIGGERED-ON-CHANGE
          signal CAN4_HeadLampSW: start 102, 2 bit, big-endian, i-signal-type=PRIMITIVE, init-value=constant-reference=Init_CAN4_HeadLampSW, base-type=uint8, implementation-data-type=uint8, transfer-property=TRIGGERED-ON-CHANGE
          signal CAN4_Hood_Latch_SW: start 79, 2 bit, big-endian, i-signal-type=PRIMITIVE, init-value=constant-reference=Init_CAN4_Hood_Latch_SW, base-type=uint8, implementation-data-type=uint8, transfer-property=TRIGGERED-ON-CHANGE
          signal CAN4_IVI_ChargePortSW_Sta: start 3, 1 bit, big-endian, i-signal-type=PRIMITIVE, init-value=constant-reference=Init_CAN4_IVI_ChargePortSW_Sta, base-type=uint8, implementation-data-type=uint8, transfer-property=TRIGGERED-ON-CHANGE
          signal CAN4_IVI_DSEATHeater_Cmd: start 110, 3 bit, big-endian, i-signal-type=PRIMITIVE, init-value=constant-reference=Init_CAN4_IVI_DSEATHeater_Cmd, base-type=uint8, implementation-data-type=uint8, transfer-property=TRIGGERED-ON-CHANGE
          signal CAN4_IVI_ISA_OffsetSpd: start 55, 4 bit, big-endian, i-signal-type=PRIMITIVE, init-value=constant-reference=Init_CAN4_IVI_ISA_OffsetSpd, base-type=uint8, implementation-data-type=uint8, transfer-property=TRIGGERED-ON-CHANGE
          signal CAN4_IVI_Located_STA: start 7, 2 bit, big-endian, i-signal-type=PRIMITIVE, init-value=constant-reference=Init_CAN4_IVI_Located_STA, base-type=uint8, implementation-data-type=uint8, transfer-property=TRIGGERED-ON-CHANGE
          signal CAN4_IVI_PSEATHeater_Cmd: start 118, 3 bit, big-endian, i-signal-type=PRIMITIVE, init-value=constant-reference=Init_CAN4_IVI_PSEATHeater_Cmd, base-type=uint8, implementation-data-type=uint8, transfer-property=TRIGGERED-ON-CHANGE
          signal CAN4_IVI_PTG_Mode_SW: start 46, 2 bit, big-endian, i-signal-type=PRIMITIVE, init-value=constant-reference=Init_CAN4_IVI_PTG_Mode_SW, base-type=uint8, implementation-data-type=uint8, transfer-property=TRIGGERED-ON-CHANGE
          signal CAN4_IVI_PTG_Open_Height: start 2, 3 bit, big-endian, i-signal-type=PRIMITIVE, init-value=constant-reference=Init_CAN4_IVI_PTG_Open_Height, base-type=uint8, implementation-data-type=uint8, transfer-property=TRIGGERED-ON-CHANGE
          signal CAN4_IVI_PTG_Sta_SW: start 41, 2 bit, big-endian, i-signal-type=PRIMITIVE, init-value=constant-reference=Init_CAN4_IVI_PTG_Sta_SW, base-type=uint8, implementation-data-type=uint8, transfer-property=TRIGGERED-ON-CHANGE
          signal CAN4_IVI_Time_Check: start 63, 8 bit, big-endian, i-signal-type=PRIMITIVE, init-value=constant-reference=Init_CAN4_IVI_Time_Check, base-type=uint8, implementation-data-type=uint8, transfer-property=PENDING
          signal CAN4_IVI_Time_Day: start 92, 5 bit, big-endian, i-signal-type=PRIMITIVE, init-value=constant-reference=Init_CAN4_IVI_Time_Day, base-type=uint8, implementation-data-type=uint8, transfer-property=PENDING
          signal CAN4_IVI_Time_Hour: start 100, 5 bit, big-endian, i-signal-type=PRIMITIVE, init-value=constant-reference=Init_CAN4_IVI_Time_Hour, base-type=uint8, implementation-data-type=uint8, transfer-property=PENDING
          signal CAN4_IVI_Time_Minute: start 77, 6 bit, big-endian, i-signal-type=PRIMITIVE, init-value=constant-reference=Init_CAN4_IVI_Time_Minute, base-type=uint8, implementation-data-type=uint8, transfer-property=PENDING
          signal CAN4_IVI_Time_Month: start 107, 4 bit, big-endian, i-signal-type=PRIMITIVE, init-value=constant-reference=Init_CAN4_IVI_Time_Month, base-type=uint8, implementation-data-type=uint8, transfer-property=PENDING
          signal CAN4_IVI_Time_Second: start 85, 6 bit, big-endian, i-signal-type=PRIMITIVE, init-value=constant-reference=Init_CAN4_IVI_Time_Second, base-type=uint8, implementation-data-type=uint8, transfer-property=PENDING
          signal CAN4_IVI_Time_Year: start 70, 7 bit, big-endian, i-signal-type=PRIMITIVE, init-value=constant-reference=Init_CAN4_IVI_Time_Year, base-type=uint8, implementation-data-type=uint8, transfer-property=PENDING
          signal CAN4_IVI_TrailerCheckReq_Sta: start 148, 1 bit, big-endian, i-signal-type=PRIMITIVE, init-value=constant-reference=Init_CAN4_IVI_TrailerCheckReq_Sta, base-type=uint8, implementation-data-type=uint8, transfer-property=TRIGGERED-ON-CHANGE
          signal CAN4_IVI_TrailerModeSW_Sta: start 149, 1 bit, big-endian, i-signal-type=PRIMITIVE, init-value=constant-reference=Init_CAN4_IVI_TrailerModeSW_Sta, base-type=uint8, implementation-data-type=uint8, transfer-property=TRIGGERED-ON-CHANGE
          signal CAN4_L_Drv_CtrlCmd: start 38, 7 bit, big-endian, i-signal-type=PRIMITIVE, init-value=constant-reference=Init_CAN4_L_Drv_CtrlCmd, base-type=uint8, implementation-data-type=uint8, transfer-property=TRIGGERED-ON-CHANGE
          signal CAN4_L_Pas_CtrlCmd: start 30, 7 bit, big-endian, i-signal-type=PRIMITIVE, init-value=constant-reference=Init_CAN4_L_Pas_CtrlCmd, base-type=uint8, implementation-data-type=uint8, transfer-property=TRIGGERED-ON-CHANGE
          signal CAN4_L_RLD_CtrlCmd: start 22, 7 bit, big-endian, i-signal-type=PRIMITIVE, init-value=constant-reference=Init_CAN4_L_RLD_CtrlCmd, base-type=uint8, implementation-data-type=uint8, transfer-property=TRIGGERED-ON-CHANGE
          signal CAN4_L_RRD_CtrlCmd: start 14, 7 bit, big-endian, i-signal-type=PRIMITIVE, init-value=constant-reference=Init_CAN4_L_RRD_CtrlCmd, base-type=uint8, implementation-data-type=uint8, transfer-property=TRIGGERED-ON-CHANGE
          signal CAN4_Light_ShowStart_Req: start 147, 1 bit, big-endian, i-signal-type=PRIMITIVE, init-value=constant-reference=Init_CAN4_Light_ShowStart_Req, base-type=uint8, implementation-data-type=uint8, transfer-property=TRIGGERED-ON-CHANGE
          signal CAN4_Light_ShowStop_Req: start 146, 1 bit, big-endian, i-signal-type=PRIMITIVE, init-value=constant-reference=Init_CAN4_Light_ShowStop_Req, base-type=uint8, implementation-data-type=uint8, transfer-property=TRIGGERED-ON-CHANGE
          signal CAN4_MCPressure: start 115, 12 bit, big-endian, i-signal-type=PRIMITIVE, init-value=constant-reference=Init_CAN4_MCPressure, base-type=uint16, implementation-data-type=uint16, transfer-property=TRIGGERED-ON-CHANGE
          signal CAN4_MCPressure_V: start 119, 1 bit, big-endian, i-signal-type=PRIMITIVE, init-value=constant-reference=Init_CAN4_MCPressure_V, base-type=uint8, implementation-data-type=uint8, transfer-property=TRIGGERED-ON-CHANGE
          signal CAN4_METER_KPH_Calcu: start 159, 8 bit, big-endian, i-signal-type=PRIMITIVE, init-value=constant-reference=Init_CAN4_METER_KPH_Calcu, base-type=uint8, implementation-data-type=uint8, transfer-property=PENDING
          signal CAN4_OBCV2LSta: start 179, 2 bit, big-endian, i-signal-type=PRIMITIVE, init-value=constant-reference=Init_CAN4_OBCV2LSta, base-type=uint8, implementation-data-type=uint8, transfer-property=TRIGGERED-ON-CHANGE
          signal CAN4_OFF_AC_MODE: start 143, 3 bit, big-endian, i-signal-type=PRIMITIVE, init-value=constant-reference=Init_CAN4_OFF_AC_MODE, base-type=uint8, implementation-data-type=uint8, transfer-property=TRIGGERED-ON-CHANGE
          signal CAN4_PSEAT_vent_req: start 44, 3 bit, big-endian, i-signal-type=PRIMITIVE, init-value=constant-reference=Init_CAN4_PSEAT_vent_req, base-type=uint8, implementation-data-type=uint8, transfer-property=TRIGGERED-ON-CHANGE
          signal CAN4_SenstivityPosition: start 51, 4 bit, big-endian, i-signal-type=PRIMITIVE, init-value=constant-reference=Init_CAN4_SenstivityPosition, base-type=uint8, implementation-data-type=uint8, transfer-property=PENDING
          signal CAN4_TBOX_Remote_PW: start 140, 5 bit, big-endian, i-signal-type=PRIMITIVE, init-value=constant-reference=Init_CAN4_TBOX_Remote_PW, base-type=uint8, implementation-data-type=uint8, transfer-property=TRIGGERED-ON-CHANGE
          signal CAN4_V2LSta: start 177, 2 bit, big-endian, i-signal-type=PRIMITIVE, init-value=constant-reference=Init_CAN4_V2LSta, base-type=uint8, implementation-data-type=uint8, transfer-property=TRIGGERED-ON-CHANGE
          signal CAN4_VehSpeed: start 243, 12 bit, big-endian, i-signal-type=PRIMITIVE, init-value=constant-reference=Init_CAN4_VehSpeed, base-type=uint16, implementation-data-type=uint16, transfer-property=PENDING
          signal CAN4_Walkaway_Lock_SW: start 23, 1 bit, big-endian, i-signal-type=PRIMITIVE, init-value=constant-reference=Init_CAN4_Walkaway_Lock_SW, base-type=uint8, implementation-data-type=uint8, transfer-property=TRIGGERED-ON-CHANGE
          signal CAN4_WlcmLight_Mode: start 145, 2 bit, big-endian, i-signal-type=PRIMITIVE, init-value=constant-reference=Init_CAN4_WlcmLight_Mode, base-type=uint8, implementation-data-type=uint8, transfer-property=TRIGGERED-ON-CHANGE
      frame CAN4_GW4_CE200_0: id 0x255, frame-length=32, can-addressing-mode=STANDARD, can-fd-frame-support=true, can-frame-rx-behavior=CAN-FD, can-frame-tx-behavior=CAN-FD
        pdu CAN4_GW4_CE200_0: length=32, minimum-delay=0.0, transmission-mode-true-timing={cyclic-timing=time-period=0.2, event-controlled-timing={number-of-repetitions=0, repetition-period=0}}, unused-bit-pattern=0
          mapping CAN4_SG_GW4_CE200_0: i-signal-group=CAN4_SG_GW4_CE200_0, start-position=0, transfer-property=TRIGGERED-ON-CHANGE
          signal CAN4_IVI_LSEATvent_Cmd: start 37, 3 bit, big-endian, i-signal-type=PRIMITIVE, init-value=constant-reference=Init_CAN4_IVI_LSEATvent_Cmd, base-type=uint8, implementation-data-type=uint8, transfer-property=TRIGGERED-ON-CHANGE
          signal CAN4_IVI_MLFMost_Cmd: start 13, 1 bit, big-endian, i-signal-type=PRIMITIVE, init-value=constant-reference=Init_CAN4_IVI_MLFMost_Cmd, base-type=uint8, implementation-data-type=uint8, transfer-property=TRIGGERED-ON-CHANGE
          signal CAN4_IVI_MLFootLift_Cmd: start 1, 2 bit, big-endian, i-signal-type=PRIMITIVE, init-value=constant-reference=Init_CAN4_IVI_MLFootLift_Cmd, base-type=uint8, implementation-data-type=uint8, transfer-property=TRIGGERED-ON-CHANGE
          signal CAN4_IVI_MLNapMode_Cmd: start 11, 1 bit, big-endian, i-signal-type=PRIMITIVE, init-value=constant-reference=Init_CAN4_IVI_MLNapMode_Cmd, base-type=uint8, implementation-data-type=uint8, transfer-property=TRIGGERED-ON-CHANGE
          signal CAN4_IVI_MLRecliner_Cmd: start 7, 2 bit, big-endian, i-signal-type=PRIMITIVE, init-value=constant-reference=Init_CAN4_IVI_MLRecliner_Cmd, base-type=uint8, implementation-data-type=uint8, transfer-property=TRIGGERED-ON-CHANGE
          signal CAN4_IVI_MLRestore_Cmd: start 12, 1 bit, big-endian, i-signal-type=PRIMITIVE, init-value=constant-reference=Init_CAN4_IVI_MLRestore_Cmd, base-type=uint8, implementation-data-type=uint8, transfer-property=TRIGGERED-ON-CHANGE
          signal CAN4_IVI_MLSEATvent_Cmd: start 10, 3 bit, big-endian, i-signal-type=PRIMITIVE, init-value=constant-reference=Init_CAN4_IVI_MLSEATvent_Cmd, base-type=uint8, implementation-data-type=uint8, transfer-property=TRIGGERED-ON-CHANGE
          signal CAN4_IVI_MLSeatLift_Cmd: start 5, 2 bit, big-endian, i-signal-type=PRIMITIVE, init-value=constant-reference=Init_CAN4_IVI_MLSeatLift_Cmd, base-type=uint8, implementation-data-type=uint8, transfer-property=TRIGGERED-ON-CHANGE
          signal CAN4_IVI_MLSldRestore_Cmd: start 14, 1 bit, big-endian, i-signal-type=PRIMITIVE, init-value=constant-reference=Init_CAN4_IVI_MLSldRestore_Cmd, base-type=uint8, implementation-data-type=uint8, transfer-property=TRIGGERED-ON-CHANGE
          signal CAN4_IVI_MLSlider_Cmd: start 3, 2 bit, big-endian, i-signal-type=PRIMITIVE, init-value=constant-reference=Init_CAN4_IVI_MLSlider_Cmd, base-type=uint8, implementation-data-type=uint8, transfer-property=TRIGGERED-ON-CHANGE
          signal CAN4_IVI_MLZeroGravity_Cmd: start 15, 1 bit, big-endian, i-signal-type=PRIMITIVE, init-value=constant-reference=Init_CAN4_IVI_MLZeroGravity_Cmd, base-type=uint8, implementation-data-type=uint8, transfer-property=TRIGGERED-ON-CHANGE
          signal CAN4_IVI_MRFMost_Cmd: start 29, 1 bit, big-endian, i-signal-type=PRIMITIVE, init-value=constant-reference=Init_CAN4_IVI_MRFMost_Cmd, base-type=uint8, implementation-data-type=uint8, transfer-property=TRIGGERED-ON-CHANGE
          signal CAN4_IVI_MRFootLift_Cmd: start 17, 2 bit, big-endian, i-signal-type=PRIMITIVE, init-value=constant-reference=Init_CAN4_IVI_MRFootLift_Cmd, base-type=uint8, implementation-data-type=uint8, transfer-property=TRIGGERED-ON-CHANGE
          signal CAN4_IVI_MRNapMode_Cmd: start 27, 1 bit, big-endian, i-signal-type=PRIMITIVE, init-value=constant-reference=Init_CAN4_IVI_MRNapMode_Cmd, base-type=uint8, implementation-data-type=uint8, transfer-property=TRIGGERED-ON-CHANGE
          signal CAN4_IVI_MRRecliner_Cmd: start 23, 2 bit, big-endian, i-signal-type=PRIMITIVE, init-value=constant-reference=Init_CAN4_IVI_MRRecliner_Cmd, base-type=uint8, implementation-data-type=uint8, transfer-property=TRIGGERED-ON-CHANGE
          signal CAN4_IVI_MRRestore_Cmd: start 28, 1 bit, big-endian, i-signal-type=PRIMITIVE, init-value=constant-reference=Init_CAN4_IVI_MRRestore_Cmd, base-type=uint8, implementation-data-type=uint8, transfer-property=TRIGGERED-ON-CHANGE
          signal CAN4_IVI_MRSEATvent_Cmd: start 26, 3 bit, big-endian, i-signal-type=PRIMITIVE, init-value=constant-reference=Init_CAN4_IVI_MRSEATvent_Cmd, base-type=uint8, implementation-data-type=uint8, transfer-property=TRIGGERED-ON-CHANGE
          signal CAN4_IVI_MRSeatLift_Cmd: start 21, 2 bit, big-endian, i-signal-type=PRIMITIVE, init-value=constant-reference=Init_CAN4_IVI_MRSeatLift_Cmd, base-type=uint8, implementation-data-type=uint8, transfer-property=TRIGGERED-ON-CHANGE
          signal CAN4_IVI_MRSldRestore_Cmd: start 30, 1 bit, big-endian, i-signal-type=PRIMITIVE, init-value=constant-reference=Init_CAN4_IVI_MRSldRestore_Cmd, base-type=uint8, implementation-data-type=uint8, transfer-property=TRIGGERED-ON-CHANGE
          signal CAN4_IVI_MRSlider_Cmd: start 19, 2 bit, big-endian, i-signal-type=PRIMITIVE, init-value=constant-reference=Init_CAN4_IVI_MRSlider_Cmd, base-type=uint8, implementation-data-type=uint8, transfer-property=TRIGGERED-ON-CHANGE
          signal CAN4_IVI_MRZeroGravity_Cmd: start 31, 1 bit, big-endian, i-signal-type=PRIMITIVE, init-value=constant-reference=Init_CAN4_IVI_MRZeroGravity_Cmd, base-type=uint8, implementation-data-type=uint8, transfer-property=TRIGGERED-ON-CHANGE
          signal CAN4_IVI_RSEATvent_Cmd: start 34, 3 bit, big-endian, i-signal-type=PRIMITIVE, init-value=constant-reference=Init_CAN4_IVI_RSEATvent_Cmd, base-type=uint8, implementation-data-type=uint8, transfer-property=TRIGGERED-ON-CHANGE
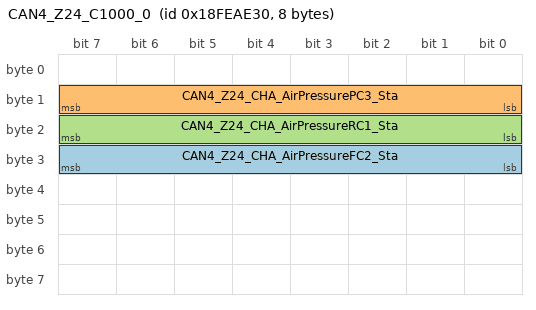
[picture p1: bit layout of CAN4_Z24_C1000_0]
      frame CAN4_Z24_C1000_0: id 0x18FEAE30, frame-length=8, can-addressing-mode=EXTENDED, can-fd-frame-support=false, can-frame-rx-behavior=CAN-20, can-frame-tx-behavior=CAN-20
        pdu CAN4_Z24_C1000_0: length=8, minimum-delay=0.0, transmission-mode-true-timing=cyclic-timing=time-period=1, unused-bit-pattern=0
          mapping CAN4_SG_Z24_C1000_0: i-signal-group=CAN4_SG_Z24_C1000_0, start-position=0, transfer-property=PENDING
          signal CAN4_Z24_CHA_AirPressureFC2_Sta: start 24, 8 bit, little-endian, i-signal-type=PRIMITIVE, init-value=constant-reference=Init_CAN4_Z24_CHA_AirPressureFC2_Sta, base-type=uint8, implementation-data-type=uint8, transfer-property=PENDING
          signal CAN4_Z24_CHA_AirPressurePC3_Sta: start 8, 8 bit, little-endian, i-signal-type=PRIMITIVE, init-value=constant-reference=Init_CAN4_Z24_CHA_AirPressurePC3_Sta, base-type=uint8, implementation-data-type=uint8, transfer-property=PENDING
          signal CAN4_Z24_CHA_AirPressureRC1_Sta: start 16, 8 bit, little-endian, i-signal-type=PRIMITIVE, init-value=constant-reference=Init_CAN4_Z24_CHA_AirPressureRC1_Sta, base-type=uint8, implementation-data-type=uint8, transfer-property=PENDING
      frame CAN4_Z24_CE100_0: id 0x203, frame-length=32, can-addressing-mode=STANDARD, can-fd-frame-support=true, can-frame-rx-behavior=CAN-FD, can-frame-tx-behavior=CAN-FD
        pdu CAN4_Z24_CE100_0: length=32, minimum-delay=0.0, transmission-mode-true-timing={cyclic-timing=time-period=0.1, event-controlled-timing={number-of-repetitions=0, repetition-period=0}}, unused-bit-pattern=0
          mapping CAN4_SG_Z24_CE100_0: i-signal-group=CAN4_SG_Z24_CE100_0, start-position=0, transfer-property=TRIGGERED-ON-CHANGE
          signal CAN4_Z24_BCM_EmExitOP_Sta: start 37, 1 bit, big-endian, i-signal-type=PRIMITIVE, init-value=constant-reference=Init_CAN4_Z24_BCM_EmExitOP_Sta, base-type=uint8, implementation-data-type=uint8, transfer-property=TRIGGERED-ON-CHANGE
          signal CAN4_Z24_BCM_FLTurnLampC_Sta: start 7, 8 bit, big-endian, i-signal-type=PRIMITIVE, init-value=constant-reference=Init_CAN4_Z24_BCM_FLTurnLampC_Sta, base-type=uint8, implementation-data-type=uint8, transfer-property=TRIGGERED-ON-CHANGE
          signal CAN4_Z24_BCM_FRTurnLampC_Sta: start 15, 8 bit, big-endian, i-signal-type=PRIMITIVE, init-value=constant-reference=Init_CAN4_Z24_BCM_FRTurnLampC_Sta, base-type=uint8, implementation-data-type=uint8, transfer-property=TRIGGERED-ON-CHANGE
          signal CAN4_Z24_BCM_FWiperAS_Sta: start 38, 1 bit, big-endian, i-signal-type=PRIMITIVE, init-value=constant-reference=Init_CAN4_Z24_BCM_FWiperAS_Sta, base-type=uint8, implementation-data-type=uint8, transfer-property=TRIGGERED-ON-CHANGE
          signal CAN4_Z24_BCM_FWiperProtection_Sta: start 39, 1 bit, big-endian, i-signal-type=PRIMITIVE, init-value=constant-reference=Init_CAN4_Z24_BCM_FWiperProtection_Sta, base-type=uint8, implementation-data-type=uint8, transfer-property=TRIGGERED-ON-CHANGE
          signal CAN4_Z24_BCM_RLTurnLampC_Sta: start 23, 8 bit, big-endian, i-signal-type=PRIMITIVE, init-value=constant-reference=Init_CAN4_Z24_BCM_RLTurnLampC_Sta, base-type=uint8, implementation-data-type=uint8, transfer-property=TRIGGERED-ON-CHANGE
          signal CAN4_Z24_BCM_RRTurnLampC_Sta: start 31, 8 bit, big-endian, i-signal-type=PRIMITIVE, init-value=constant-reference=Init_CAN4_Z24_BCM_RRTurnLampC_Sta, base-type=uint8, implementation-data-type=uint8, transfer-property=TRIGGERED-ON-CHANGE
          signal CAN4_Z24_BCM_SeatBeltSW_Sta: start 35, 1 bit, big-endian, i-signal-type=PRIMITIVE, init-value=constant-reference=Init_CAN4_Z24_BCM_SeatBeltSW_Sta, base-type=uint8, implementation-data-type=uint8, transfer-property=TRIGGERED-ON-CHANGE
          signal CAN4_Z24_BCM_innerBuzzer_Sta: start 36, 1 bit, big-endian, i-signal-type=PRIMITIVE, init-value=constant-reference=Init_CAN4_Z24_BCM_innerBuzzer_Sta, base-type=uint8, implementation-data-type=uint8, transfer-property=TRIGGERED-ON-CHANGE
      frame CAN4_ZONE_DR1: id 0x325, frame-length=48, can-addressing-mode=STANDARD, can-fd-frame-support=true, can-frame-rx-behavior=CAN-FD, can-frame-tx-behavior=CAN-FD
        pdu CAN4_ZONE_DR1: length=48, minimum-delay=0.0, transmission-mode-true-timing={cyclic-timing=time-period=0.1, event-controlled-timing={number-of-repetitions=0, repetition-period=0}}, unused-bit-pattern=0
          mapping CAN4_SG_ZONE_DR1: i-signal-group=CAN4_SG_ZONE_DR1, start-position=0, transfer-property=TRIGGERED-ON-CHANGE
          signal CAN4_ACT1_Actuator_address: start 383, 8 bit, big-endian, i-signal-type=PRIMITIVE, init-value=constant-reference=Init_CAN4_ACT1_Actuator_address, base-type=uint8, implementation-data-type=uint8, transfer-property=PENDING
          signal CAN4_ACT1_Actuator_set_position: start 351, 16 bit, big-endian, i-signal-type=PRIMITIVE, init-value=constant-reference=Init_CAN4_ACT1_Actuator_set_position, base-type=uint16, implementation-data-type=uint16, transfer-property=PENDING
          signal CAN4_ACT1_Actuator_start_position: start 335, 16 bit, big-endian, i-signal-type=PRIMITIVE, init-value=constant-reference=Init_CAN4_ACT1_Actuator_start_position, base-type=uint16, implementation-data-type=uint16, transfer-property=PENDING
          signal CAN4_ACT1_Applied_holding_current: start 361, 2 bit, big-endian, i-signal-type=PRIMITIVE, init-value=constant-reference=Init_CAN4_ACT1_Applied_holding_current, base-type=uint8, implementation-data-type=uint8, transfer-property=PENDING
          signal CAN4_ACT1_Clear_Event_Flags: start 375, 4 bit, big-endian, i-signal-type=PRIMITIVE, init-value=constant-reference=Init_CAN4_ACT1_Clear_Event_Flags, base-type=uint8, implementation-data-type=uint8, transfer-property=PENDING
          signal CAN4_ACT1_Emergency_run_position: start 323, 2 bit, big-endian, i-signal-type=PRIMITIVE, init-value=constant-reference=Init_CAN4_ACT1_Emergency_run_position, base-type=uint8, implementation-data-type=uint8, transfer-property=PENDING
          signal CAN4_ACT1_Emergency_run_release: start 321, 2 bit, big-endian, i-signal-type=PRIMITIVE, init-value=constant-reference=Init_CAN4_ACT1_Emergency_run_release, base-type=uint8, implementation-data-type=uint8, transfer-property=PENDING
          signal CAN4_ACT1_Rotation_direction: start 325, 2 bit, big-endian, i-signal-type=PRIMITIVE, init-value=constant-reference=Init_CAN4_ACT1_Rotation_direction, base-type=uint8, implementation-data-type=uint8, transfer-property=PENDING
          signal CAN4_ACT1_Save_programming_data: start 369, 2 bit, big-endian, i-signal-type=PRIMITIVE, init-value=constant-reference=Init_CAN4_ACT1_Save_programming_data, base-type=uint8, implementation-data-type=uint8, transfer-property=PENDING
          signal CAN4_ACT1_Select_position_specification: start 363, 2 bit, big-endian, i-signal-type=PRIMITIVE, init-value=constant-reference=Init_CAN4_ACT1_Select_position_specification, base-type=uint8, implementation-data-type=uint8, transfer-property=PENDING
          signal CAN4_ACT1_Speed_specification: start 367, 4 bit, big-endian, i-signal-type=PRIMITIVE, init-value=constant-reference=Init_CAN4_ACT1_Speed_specification, base-type=uint8, implementation-data-type=uint8, transfer-property=PENDING
          signal CAN4_ACT1_Stall_detection_release: start 371, 2 bit, big-endian, i-signal-type=PRIMITIVE, init-value=constant-reference=Init_CAN4_ACT1_Stall_detection_release, base-type=uint8, implementation-data-type=uint8, transfer-property=PENDING
          signal CAN4_ACT1_Stop_mode: start 327, 2 bit, big-endian, i-signal-type=PRIMITIVE, init-value=constant-reference=Init_CAN4_ACT1_Stop_mode, base-type=uint8, implementation-data-type=uint8, transfer-property=PENDING
          signal CAN4_ACT2_Actuator_address: start 319, 8 bit, big-endian, i-signal-type=PRIMITIVE, init-value=constant-reference=Init_CAN4_ACT2_Actuator_address, base-type=uint8, implementation-data-type=uint8, transfer-property=PENDING
          signal CAN4_ACT2_Actuator_set_position: start 287, 16 bit, big-endian, i-signal-type=PRIMITIVE, init-value=constant-reference=Init_CAN4_ACT2_Actuator_set_position, base-type=uint16, implementation-data-type=uint16, transfer-property=PENDING
          signal CAN4_ACT2_Actuator_start_position: start 271, 16 bit, big-endian, i-signal-type=PRIMITIVE, init-value=constant-reference=Init_CAN4_ACT2_Actuator_start_position, base-type=uint16, implementation-data-type=uint16, transfer-property=PENDING
          signal CAN4_ACT2_Applied_holding_current: start 297, 2 bit, big-endian, i-signal-type=PRIMITIVE, init-value=constant-reference=Init_CAN4_ACT2_Applied_holding_current, base-type=uint8, implementation-data-type=uint8, transfer-property=PENDING
          signal CAN4_ACT2_Clear_Event_Flags: start 311, 4 bit, big-endian, i-signal-type=PRIMITIVE, init-value=constant-reference=Init_CAN4_ACT2_Clear_Event_Flags, base-type=uint8, implementation-data-type=uint8, transfer-property=PENDING
          signal CAN4_ACT2_Emergency_run_position: start 259, 2 bit, big-endian, i-signal-type=PRIMITIVE, init-value=constant-reference=Init_CAN4_ACT2_Emergency_run_position, base-type=uint8, implementation-data-type=uint8, transfer-property=PENDING
          signal CAN4_ACT2_Emergency_run_release: start 257, 2 bit, big-endian, i-signal-type=PRIMITIVE, init-value=constant-reference=Init_CAN4_ACT2_Emergency_run_release, base-type=uint8, implementation-data-type=uint8, transfer-property=PENDING
          signal CAN4_ACT2_Rotation_direction: start 261, 2 bit, big-endian, i-signal-type=PRIMITIVE, init-value=constant-reference=Init_CAN4_ACT2_Rotation_direction, base-type=uint8, implementation-data-type=uint8, transfer-property=PENDING
          signal CAN4_ACT2_Save_programming_data: start 305, 2 bit, big-endian, i-signal-type=PRIMITIVE, init-value=constant-reference=Init_CAN4_ACT2_Save_programming_data, base-type=uint8, implementation-data-type=uint8, transfer-property=PENDING
          signal CAN4_ACT2_Select_position_specification: start 299, 2 bit, big-endian, i-signal-type=PRIMITIVE, init-value=constant-reference=Init_CAN4_ACT2_Select_position_specification, base-type=uint8, implementation-data-type=uint8, transfer-property=PENDING
          signal CAN4_ACT2_Speed_specification: start 303, 4 bit, big-endian, i-signal-type=PRIMITIVE, init-value=constant-reference=Init_CAN4_ACT2_Speed_specification, base-type=uint8, implementation-data-type=uint8, transfer-property=PENDING
          signal CAN4_ACT2_Stall_detection_release: start 307, 2 bit, big-endian, i-signal-type=PRIMITIVE, init-value=constant-reference=Init_CAN4_ACT2_Stall_detection_release, base-type=uint8, implementation-data-type=uint8, transfer-property=PENDING
          signal CAN4_ACT2_Stop_mode: start 263, 2 bit, big-endian, i-signal-type=PRIMITIVE, init-value=constant-reference=Init_CAN4_ACT2_Stop_mode, base-type=uint8, implementation-data-type=uint8, transfer-property=PENDING
          signal CAN4_ACT3_Actuator_address: start 255, 8 bit, big-endian, i-signal-type=PRIMITIVE, init-value=constant-reference=Init_CAN4_ACT3_Actuator_address, base-type=uint8, implementation-data-type=uint8, transfer-property=PENDING
          signal CAN4_ACT3_Actuator_set_position: start 223, 16 bit, big-endian, i-signal-type=PRIMITIVE, init-value=constant-reference=Init_CAN4_ACT3_Actuator_set_position, base-type=uint16, implementation-data-type=uint16, transfer-property=PENDING
          signal CAN4_ACT3_Actuator_start_position: start 207, 16 bit, big-endian, i-signal-type=PRIMITIVE, init-value=constant-reference=Init_CAN4_ACT3_Actuator_start_position, base-type=uint16, implementation-data-type=uint16, transfer-property=PENDING
          signal CAN4_ACT3_Applied_holding_current: start 233, 2 bit, big-endian, i-signal-type=PRIMITIVE, init-value=constant-reference=Init_CAN4_ACT3_Applied_holding_current, base-type=uint8, implementation-data-type=uint8, transfer-property=PENDING
          signal CAN4_ACT3_Clear_Event_Flags: start 247, 4 bit, big-endian, i-signal-type=PRIMITIVE, init-value=constant-reference=Init_CAN4_ACT3_Clear_Event_Flags, base-type=uint8, implementation-data-type=uint8, transfer-property=PENDING
          signal CAN4_ACT3_Emergency_run_position: start 195, 2 bit, big-endian, i-signal-type=PRIMITIVE, init-value=constant-reference=Init_CAN4_ACT3_Emergency_run_position, base-type=uint8, implementation-data-type=uint8, transfer-property=PENDING
          signal CAN4_ACT3_Emergency_run_release: start 193, 2 bit, big-endian, i-signal-type=PRIMITIVE, init-value=constant-reference=Init_CAN4_ACT3_Emergency_run_release, base-type=uint8, implementation-data-type=uint8, transfer-property=PENDING
          signal CAN4_ACT3_Rotation_direction: start 197, 2 bit, big-endian, i-signal-type=PRIMITIVE, init-value=constant-reference=Init_CAN4_ACT3_Rotation_direction, base-type=uint8, implementation-data-type=uint8, transfer-property=PENDING
          signal CAN4_ACT3_Save_programming_data: start 241, 2 bit, big-endian, i-signal-type=PRIMITIVE, init-value=constant-reference=Init_CAN4_ACT3_Save_programming_data, base-type=uint8, implementation-data-type=uint8, transfer-property=PENDING
          signal CAN4_ACT3_Select_position_specification: start 235, 2 bit, big-endian, i-signal-type=PRIMITIVE, init-value=constant-reference=Init_CAN4_ACT3_Select_position_specification, base-type=uint8, implementation-data-type=uint8, transfer-property=PENDING
          signal CAN4_ACT3_Speed_specification: start 239, 4 bit, big-endian, i-signal-type=PRIMITIVE, init-value=constant-reference=Init_CAN4_ACT3_Speed_specification, base-type=uint8, implementation-data-type=uint8, transfer-property=PENDING
          signal CAN4_ACT3_Stall_detection_release: start 243, 2 bit, big-endian, i-signal-type=PRIMITIVE, init-value=constant-reference=Init_CAN4_ACT3_Stall_detection_release, base-type=uint8, implementation-data-type=uint8, transfer-property=PENDING
          signal CAN4_ACT3_Stop_mode: start 199, 2 bit, big-endian, i-signal-type=PRIMITIVE, init-value=constant-reference=Init_CAN4_ACT3_Stop_mode, base-type=uint8, implementation-data-type=uint8, transfer-property=PENDING
          signal CAN4_ACT4_Actuator_address: start 191, 8 bit, big-endian, i-signal-type=PRIMITIVE, init-value=constant-reference=Init_CAN4_ACT4_Actuator_address, base-type=uint8, implementation-data-type=uint8, transfer-property=PENDING
          signal CAN4_ACT4_Actuator_set_position: start 159, 16 bit, big-endian, i-signal-type=PRIMITIVE, init-value=constant-reference=Init_CAN4_ACT4_Actuator_set_position, base-type=uint16, implementation-data-type=uint16, transfer-property=PENDING
          signal CAN4_ACT4_Actuator_start_position: start 143, 16 bit, big-endian, i-signal-type=PRIMITIVE, init-value=constant-reference=Init_CAN4_ACT4_Actuator_start_position, base-type=uint16, implementation-data-type=uint16, transfer-property=PENDING
          signal CAN4_ACT4_Applied_holding_current: start 169, 2 bit, big-endian, i-signal-type=PRIMITIVE, init-value=constant-reference=Init_CAN4_ACT4_Applied_holding_current, base-type=uint8, implementation-data-type=uint8, transfer-property=PENDING
          signal CAN4_ACT4_Clear_Event_Flags: start 183, 4 bit, big-endian, i-signal-type=PRIMITIVE, init-value=constant-reference=Init_CAN4_ACT4_Clear_Event_Flags, base-type=uint8, implementation-data-type=uint8, transfer-property=PENDING
          signal CAN4_ACT4_Emergency_run_position: start 131, 2 bit, big-endian, i-signal-type=PRIMITIVE, init-value=constant-reference=Init_CAN4_ACT4_Emergency_run_position, base-type=uint8, implementation-data-type=uint8, transfer-property=PENDING
          signal CAN4_ACT4_Emergency_run_release: start 129, 2 bit, big-endian, i-signal-type=PRIMITIVE, init-value=constant-reference=Init_CAN4_ACT4_Emergency_run_release, base-type=uint8, implementation-data-type=uint8, transfer-property=PENDING
          signal CAN4_ACT4_Rotation_direction: start 133, 2 bit, big-endian, i-signal-type=PRIMITIVE, init-value=constant-reference=Init_CAN4_ACT4_Rotation_direction, base-type=uint8, implementation-data-type=uint8, transfer-property=PENDING
          signal CAN4_ACT4_Save_programming_data: start 177, 2 bit, big-endian, i-signal-type=PRIMITIVE, init-value=constant-reference=Init_CAN4_ACT4_Save_programming_data, base-type=uint8, implementation-data-type=uint8, transfer-property=PENDING
          signal CAN4_ACT4_Select_position_specification: start 171, 2 bit, big-endian, i-signal-type=PRIMITIVE, init-value=constant-reference=Init_CAN4_ACT4_Select_position_specification, base-type=uint8, implementation-data-type=uint8, transfer-property=PENDING
          signal CAN4_ACT4_Speed_specification: start 175, 4 bit, big-endian, i-signal-type=PRIMITIVE, init-value=constant-reference=Init_CAN4_ACT4_Speed_specification, base-type=uint8, implementation-data-type=uint8, transfer-property=PENDING
          signal CAN4_ACT4_Stall_detection_release: start 179, 2 bit, big-endian, i-signal-type=PRIMITIVE, init-value=constant-reference=Init_CAN4_ACT4_Stall_detection_release, base-type=uint8, implementation-data-type=uint8, transfer-property=PENDING
          signal CAN4_ACT4_Stop_mode: start 135, 2 bit, big-endian, i-signal-type=PRIMITIVE, init-value=constant-reference=Init_CAN4_ACT4_Stop_mode, base-type=uint8, implementation-data-type=uint8, transfer-property=PENDING
          signal CAN4_ACT5_Actuator_address: start 127, 8 bit, big-endian, i-signal-type=PRIMITIVE, init-value=constant-reference=Init_CAN4_ACT5_Actuator_address, base-type=uint8, implementation-data-type=uint8, transfer-property=PENDING
          signal CAN4_ACT5_Actuator_set_position: start 95, 16 bit, big-endian, i-signal-type=PRIMITIVE, init-value=constant-reference=Init_CAN4_ACT5_Actuator_set_position, base-type=uint16, implementation-data-type=uint16, transfer-property=PENDING
          signal CAN4_ACT5_Actuator_start_position: start 79, 16 bit, big-endian, i-signal-type=PRIMITIVE, init-value=constant-reference=Init_CAN4_ACT5_Actuator_start_position, base-type=uint16, implementation-data-type=uint16, transfer-property=PENDING
          signal CAN4_ACT5_Applied_holding_current: start 105, 2 bit, big-endian, i-signal-type=PRIMITIVE, init-value=constant-reference=Init_CAN4_ACT5_Applied_holding_current, base-type=uint8, implementation-data-type=uint8, transfer-property=PENDING
          signal CAN4_ACT5_Clear_Event_Flags: start 119, 4 bit, big-endian, i-signal-type=PRIMITIVE, init-value=constant-reference=Init_CAN4_ACT5_Clear_Event_Flags, base-type=uint8, implementation-data-type=uint8, transfer-property=PENDING
          signal CAN4_ACT5_Emergency_run_position: start 67, 2 bit, big-endian, i-signal-type=PRIMITIVE, init-value=constant-reference=Init_CAN4_ACT5_Emergency_run_position, base-type=uint8, implementation-data-type=uint8, transfer-property=PENDING
          signal CAN4_ACT5_Emergency_run_release: start 65, 2 bit, big-endian, i-signal-type=PRIMITIVE, init-value=constant-reference=Init_CAN4_ACT5_Emergency_run_release, base-type=uint8, implementation-data-type=uint8, transfer-property=PENDING
          signal CAN4_ACT5_Rotation_direction: start 69, 2 bit, big-endian, i-signal-type=PRIMITIVE, init-value=constant-reference=Init_CAN4_ACT5_Rotation_direction, base-type=uint8, implementation-data-type=uint8, transfer-property=PENDING
          signal CAN4_ACT5_Save_programming_data: start 113, 2 bit, big-endian, i-signal-type=PRIMITIVE, init-value=constant-reference=Init_CAN4_ACT5_Save_programming_data, base-type=uint8, implementation-data-type=uint8, transfer-property=PENDING
          signal CAN4_ACT5_Select_position_specification: start 107, 2 bit, big-endian, i-signal-type=PRIMITIVE, init-value=constant-reference=Init_CAN4_ACT5_Select_position_specification, base-type=uint8, implementation-data-type=uint8, transfer-property=PENDING
          signal CAN4_ACT5_Speed_specification: start 111, 4 bit, big-endian, i-signal-type=PRIMITIVE, init-value=constant-reference=Init_CAN4_ACT5_Speed_specification, base-type=uint8, implementation-data-type=uint8, transfer-property=PENDING
          signal CAN4_ACT5_Stall_detection_release: start 115, 2 bit, big-endian, i-signal-type=PRIMITIVE, init-value=constant-reference=Init_CAN4_ACT5_Stall_detection_release, base-type=uint8, implementation-data-type=uint8, transfer-property=PENDING
          signal CAN4_ACT5_Stop_mode: start 71, 2 bit, big-endian, i-signal-type=PRIMITIVE, init-value=constant-reference=Init_CAN4_ACT5_Stop_mode, base-type=uint8, implementation-data-type=uint8, transfer-property=PENDING
          signal CAN4_AllLockSta: start 25, 1 bit, big-endian, i-signal-type=PRIMITIVE, init-value=constant-reference=Init_CAN4_AllLockSta, base-type=uint8, implementation-data-type=uint8, transfer-property=TRIGGERED-ON-CHANGE
          signal CAN4_AutoLightSW: start 35, 1 bit, big-endian, i-signal-type=PRIMITIVE, init-value=constant-reference=Init_CAN4_AutoLightSW, base-type=uint8, implementation-data-type=uint8, transfer-property=TRIGGERED-ON-CHANGE
          signal CAN4_BrakeLampFail: start 29, 1 bit, big-endian, i-signal-type=PRIMITIVE, init-value=constant-reference=Init_CAN4_BrakeLampFail, base-type=uint8, implementation-data-type=uint8, transfer-property=TRIGGERED-ON-CHANGE
          signal CAN4_DrLockSta: start 24, 1 bit, big-endian, i-signal-type=PRIMITIVE, init-value=constant-reference=Init_CAN4_DrLockSta, base-type=uint8, implementation-data-type=uint8, transfer-property=TRIGGERED-ON-CHANGE
          signal CAN4_HornSW: start 30, 1 bit, big-endian, i-signal-type=PRIMITIVE, init-value=constant-reference=Init_CAN4_HornSW, base-type=uint8, implementation-data-type=uint8, transfer-property=TRIGGERED-ON-CHANGE
          signal CAN4_MIRROR_FOLD_SW: start 26, 1 bit, big-endian, i-signal-type=PRIMITIVE, init-value=constant-reference=Init_CAN4_MIRROR_FOLD_SW, base-type=uint8, implementation-data-type=uint8, transfer-property=TRIGGERED-ON-CHANGE
          signal CAN4_PsLockSta: start 38, 1 bit, big-endian, i-signal-type=PRIMITIVE, init-value=constant-reference=Init_CAN4_PsLockSta, base-type=uint8, implementation-data-type=uint8, transfer-property=TRIGGERED-ON-CHANGE
          signal CAN4_RLLockSta: start 37, 1 bit, big-endian, i-signal-type=PRIMITIVE, init-value=constant-reference=Init_CAN4_RLLockSta, base-type=uint8, implementation-data-type=uint8, transfer-property=TRIGGERED-ON-CHANGE
          signal CAN4_RLS_Exist: start 39, 1 bit, big-endian, i-signal-type=PRIMITIVE, init-value=constant-reference=Init_CAN4_RLS_Exist, base-type=uint8, implementation-data-type=uint8, transfer-property=TRIGGERED-ON-CHANGE
          signal CAN4_RLTurnLPErr: start 23, 1 bit, big-endian, i-signal-type=PRIMITIVE, init-value=constant-reference=Init_CAN4_RLTurnLPErr, base-type=uint8, implementation-data-type=uint8, transfer-property=TRIGGERED-ON-CHANGE
          signal CAN4_RLTurnLampC: start 63, 8 bit, big-endian, i-signal-type=PRIMITIVE, init-value=constant-reference=Init_CAN4_RLTurnLampC, base-type=uint8, implementation-data-type=uint8, transfer-property=TRIGGERED-ON-CHANGE
          signal CAN4_RRLockSta: start 36, 1 bit, big-endian, i-signal-type=PRIMITIVE, init-value=constant-reference=Init_CAN4_RRLockSta, base-type=uint8, implementation-data-type=uint8, transfer-property=TRIGGERED-ON-CHANGE
          signal CAN4_RRTurnLPErr: start 22, 1 bit, big-endian, i-signal-type=PRIMITIVE, init-value=constant-reference=Init_CAN4_RRTurnLPErr, base-type=uint8, implementation-data-type=uint8, transfer-property=TRIGGERED-ON-CHANGE
          signal CAN4_RRTurnLampC: start 55, 8 bit, big-endian, i-signal-type=PRIMITIVE, init-value=constant-reference=Init_CAN4_RRTurnLampC, base-type=uint8, implementation-data-type=uint8, transfer-property=TRIGGERED-ON-CHANGE
          signal CAN4_RWiperAS: start 27, 1 bit, big-endian, i-signal-type=PRIMITIVE, init-value=constant-reference=Init_CAN4_RWiperAS, base-type=uint8, implementation-data-type=uint8, transfer-property=TRIGGERED-ON-CHANGE
          signal CAN4_RWiperProtection: start 28, 1 bit, big-endian, i-signal-type=PRIMITIVE, init-value=constant-reference=Init_CAN4_RWiperProtection, base-type=uint8, implementation-data-type=uint8, transfer-property=TRIGGERED-ON-CHANGE
          signal CAN4_Wip_Speed: start 33, 2 bit, big-endian, i-signal-type=PRIMITIVE, init-value=constant-reference=Init_CAN4_Wip_Speed, base-type=uint8, implementation-data-type=uint8, transfer-property=TRIGGERED-ON-CHANGE
          signal CAN4_WiperSWPos: start 47, 8 bit, big-endian, i-signal-type=PRIMITIVE, init-value=constant-reference=Init_CAN4_WiperSWPos, base-type=uint8, implementation-data-type=uint8, transfer-property=TRIGGERED-ON-CHANGE
          signal CAN4_WiperZeroPosSW: start 34, 1 bit, big-endian, i-signal-type=PRIMITIVE, init-value=constant-reference=Init_CAN4_WiperZeroPosSW, base-type=uint8, implementation-data-type=uint8, transfer-property=TRIGGERED-ON-CHANGE
          signal CAN4_ZDR_THCM_IntakeFail_Sta: start 15, 2 bit, big-endian, i-signal-type=PRIMITIVE, init-value=constant-reference=Init_CAN4_ZDR_THCM_IntakeFail_Sta, base-type=uint8, implementation-data-type=uint8, transfer-property=TRIGGERED-ON-CHANGE
          signal CAN4_ZDR_THCM_LINACT1_Sta: start 11, 2 bit, big-endian, i-signal-type=PRIMITIVE, init-value=constant-reference=Init_CAN4_ZDR_THCM_LINACT1_Sta, base-type=uint8, implementation-data-type=uint8, transfer-property=TRIGGERED-ON-CHANGE
          signal CAN4_ZDR_THCM_LINACT2_Sta: start 9, 2 bit, big-endian, i-signal-type=PRIMITIVE, init-value=constant-reference=Init_CAN4_ZDR_THCM_LINACT2_Sta, base-type=uint8, implementation-data-type=uint8, transfer-property=TRIGGERED-ON-CHANGE
          signal CAN4_ZDR_THCM_LINACT3_Sta: start 21, 2 bit, big-endian, i-signal-type=PRIMITIVE, init-value=constant-reference=Init_CAN4_ZDR_THCM_LINACT3_Sta, base-type=uint8, implementation-data-type=uint8, transfer-property=TRIGGERED-ON-CHANGE
          signal CAN4_ZDR_THCM_LINACT4_Sta: start 19, 2 bit, big-endian, i-signal-type=PRIMITIVE, init-value=constant-reference=Init_CAN4_ZDR_THCM_LINACT4_Sta, base-type=uint8, implementation-data-type=uint8, transfer-property=TRIGGERED-ON-CHANGE
          signal CAN4_ZDR_THCM_LINACT5_Sta: start 17, 2 bit, big-endian, i-signal-type=PRIMITIVE, init-value=constant-reference=Init_CAN4_ZDR_THCM_LINACT5_Sta, base-type=uint8, implementation-data-type=uint8, transfer-property=TRIGGERED-ON-CHANGE
          signal CAN4_ZDR_THCM_ModeFail_Sta: start 13, 2 bit, big-endian, i-signal-type=PRIMITIVE, init-value=constant-reference=Init_CAN4_ZDR_THCM_ModeFail_Sta, base-type=uint8, implementation-data-type=uint8, transfer-property=TRIGGERED-ON-CHANGE
      frame CAN4_ZONE_DR_VCU: id 0x1F1, frame-length=48, can-addressing-mode=STANDARD, can-fd-frame-support=true, can-frame-rx-behavior=CAN-FD, can-frame-tx-behavior=CAN-FD
        pdu CAN4_ZONE_DR_VCU: length=48, minimum-delay=0.0, transmission-mode-true-timing={cyclic-timing=time-period=0.02, event-controlled-timing={number-of-repetitions=0, repetition-period=0}}, unused-bit-pattern=0
          mapping CAN4_SG_ZONE_DR_VCU: i-signal-group=CAN4_SG_ZONE_DR_VCU, start-position=0, transfer-property=TRIGGERED-ON-CHANGE
          signal CAN4_APTC_Err: start 215, 2 bit, big-endian, i-signal-type=PRIMITIVE, init-value=constant-reference=Init_CAN4_APTC_Err, base-type=uint8, implementation-data-type=uint8, transfer-property=TRIGGERED-ON-CHANGE
          signal CAN4_Blower_Err: start 213, 2 bit, big-endian, i-signal-type=PRIMITIVE, init-value=constant-reference=Init_CAN4_Blower_Err, base-type=uint8, implementation-data-type=uint8, transfer-property=TRIGGERED-ON-CHANGE
          signal CAN4_Blower_FB: start 71, 4 bit, big-endian, i-signal-type=PRIMITIVE, init-value=constant-reference=Init_CAN4_Blower_FB, base-type=uint8, implementation-data-type=uint8, transfer-property=PENDING
          signal CAN4_DrADASCurr: start 23, 8 bit, big-endian, i-signal-type=PRIMITIVE, init-value=constant-reference=Init_CAN4_DrADASCurr, base-type=uint8, implementation-data-type=uint8, transfer-property=PENDING
          signal CAN4_DrAPWLINErr: start 254, 1 bit, big-endian, i-signal-type=PRIMITIVE, init-value=constant-reference=Init_CAN4_DrAPWLINErr, base-type=uint8, implementation-data-type=uint8, transfer-property=TRIGGERED-ON-CHANGE
          signal CAN4_DrAPWStaErr: start 4, 1 bit, big-endian, i-signal-type=PRIMITIVE, init-value=constant-reference=Init_CAN4_DrAPWStaErr, base-type=uint8, implementation-data-type=uint8, transfer-property=TRIGGERED-ON-CHANGE
          signal CAN4_DrAuBoxPwrN1Curr: start 39, 8 bit, big-endian, i-signal-type=PRIMITIVE, init-value=constant-reference=Init_CAN4_DrAuBoxPwrN1Curr, base-type=uint8, implementation-data-type=uint8, transfer-property=PENDING
          signal CAN4_DrAuBoxPwrN2Curr: start 31, 8 bit, big-endian, i-signal-type=PRIMITIVE, init-value=constant-reference=Init_CAN4_DrAuBoxPwrN2Curr, base-type=uint8, implementation-data-type=uint8, transfer-property=PENDING
          signal CAN4_DrColumnSWFault: start 9, 2 bit, big-endian, i-signal-type=PRIMITIVE, init-value=constant-reference=Init_CAN4_DrColumnSWFault, base-type=uint8, implementation-data-type=uint8, transfer-property=PENDING
          signal CAN4_DrCtrlBDVolt: start 67, 12 bit, big-endian, i-signal-type=PRIMITIVE, init-value=constant-reference=Init_CAN4_DrCtrlBDVolt, base-type=uint16, implementation-data-type=uint16, transfer-property=PENDING
          signal CAN4_DrCtrlTemp: start 87, 16 bit, big-endian, i-signal-type=PRIMITIVE, init-value=constant-reference=Init_CAN4_DrCtrlTemp, base-type=uint16, implementation-data-type=uint16, transfer-property=PENDING
          signal CAN4_DrEOBDFault: start 1, 2 bit, big-endian, i-signal-type=PRIMITIVE, init-value=constant-reference=Init_CAN4_DrEOBDFault, base-type=uint8, implementation-data-type=uint8, transfer-property=PENDING
          signal CAN4_DrIVIFault: start 3, 2 bit, big-endian, i-signal-type=PRIMITIVE, init-value=constant-reference=Init_CAN4_DrIVIFault, base-type=uint8, implementation-data-type=uint8, transfer-property=PENDING
          signal CAN4_DrInfoErrSta: start 253, 1 bit, big-endian, i-signal-type=PRIMITIVE, init-value=constant-reference=Init_CAN4_DrInfoErrSta, base-type=uint8, implementation-data-type=uint8, transfer-property=TRIGGERED-ON-CHANGE
          signal CAN4_DrInfoFault: start 15, 2 bit, big-endian, i-signal-type=PRIMITIVE, init-value=constant-reference=Init_CAN4_DrInfoFault, base-type=uint8, implementation-data-type=uint8, transfer-property=PENDING
          signal CAN4_DrONA1ErrSta: start 252, 1 bit, big-endian, i-signal-type=PRIMITIVE, init-value=constant-reference=Init_CAN4_DrONA1ErrSta, base-type=uint8, implementation-data-type=uint8, transfer-property=TRIGGERED-ON-CHANGE
          signal CAN4_DrPMMLVOutPErrLmp: start 6, 1 bit, big-endian, i-signal-type=PRIMITIVE, init-value=constant-reference=Init_CAN4_DrPMMLVOutPErrLmp, base-type=uint8, implementation-data-type=uint8, transfer-property=TRIGGERED-ON-CHANGE
          signal CAN4_DrPMMLimpHomeActReq: start 5, 1 bit, big-endian, i-signal-type=PRIMITIVE, init-value=constant-reference=Init_CAN4_DrPMMLimpHomeActReq, base-type=uint8, implementation-data-type=uint8, transfer-property=TRIGGERED-ON-CHANGE
          signal CAN4_DrPMMSysErrLmp: start 7, 1 bit, big-endian, i-signal-type=PRIMITIVE, init-value=constant-reference=Init_CAN4_DrPMMSysErrLmp, base-type=uint8, implementation-data-type=uint8, transfer-property=TRIGGERED-ON-CHANGE
          signal CAN4_DrPowerTemp1: start 103, 16 bit, big-endian, i-signal-type=PRIMITIVE, init-value=constant-reference=Init_CAN4_DrPowerTemp1, base-type=uint16, implementation-data-type=uint16, transfer-property=PENDING
          signal CAN4_DrPowerTemp2: start 119, 16 bit, big-endian, i-signal-type=PRIMITIVE, init-value=constant-reference=Init_CAN4_DrPowerTemp2, base-type=uint16, implementation-data-type=uint16, transfer-property=PENDING
          signal CAN4_DrPwrInformationSta: start 261, 1 bit, big-endian, i-signal-type=PRIMITIVE, init-value=constant-reference=Init_CAN4_DrPwrInformationSta, base-type=uint8, implementation-data-type=uint8, transfer-property=TRIGGERED-ON-CHANGE
          signal CAN4_DrPwrONA1Curr: start 63, 8 bit, big-endian, i-signal-type=PRIMITIVE, init-value=constant-reference=Init_CAN4_DrPwrONA1Curr, base-type=uint8, implementation-data-type=uint8, transfer-property=PENDING
          signal CAN4_DrPwrONA2Curr: start 55, 8 bit, big-endian, i-signal-type=PRIMITIVE, init-value=constant-reference=Init_CAN4_DrPwrONA2Curr, base-type=uint8, implementation-data-type=uint8, transfer-property=PENDING
          signal CAN4_DrPwrSta: start 258, 3 bit, big-endian, i-signal-type=PRIMITIVE, init-value=constant-reference=Init_CAN4_DrPwrSta, base-type=uint8, implementation-data-type=uint8, transfer-property=TRIGGERED-ON-CHANGE
          signal CAN4_DrPwrStdbyACurr: start 47, 8 bit, big-endian, i-signal-type=PRIMITIVE, init-value=constant-reference=Init_CAN4_DrPwrStdbyACurr, base-type=uint8, implementation-data-type=uint8, transfer-property=PENDING
          signal CAN4_DrPwrWinErrSta: start 255, 1 bit, big-endian, i-signal-type=PRIMITIVE, init-value=constant-reference=Init_CAN4_DrPwrWinErrSta, base-type=uint8, implementation-data-type=uint8, transfer-property=TRIGGERED-ON-CHANGE
          signal CAN4_DrPwrWindowECUFault: start 13, 2 bit, big-endian, i-signal-type=PRIMITIVE, init-value=constant-reference=Init_CAN4_DrPwrWindowECUFault, base-type=uint8, implementation-data-type=uint8, transfer-property=PENDING
          signal CAN4_DrSCPSysErrLmp: start 260, 1 bit, big-endian, i-signal-type=PRIMITIVE, init-value=constant-reference=Init_CAN4_DrSCPSysErrLmp, base-type=uint8, implementation-data-type=uint8, transfer-property=TRIGGERED-ON-CHANGE
          signal CAN4_DrStdAErrSta: start 251, 1 bit, big-endian, i-signal-type=PRIMITIVE, init-value=constant-reference=Init_CAN4_DrStdAErrSta, base-type=uint8, implementation-data-type=uint8, transfer-property=TRIGGERED-ON-CHANGE
          signal CAN4_DrTHCMFault: start 11, 2 bit, big-endian, i-signal-type=PRIMITIVE, init-value=constant-reference=Init_CAN4_DrTHCMFault, base-type=uint8, implementation-data-type=uint8, transfer-property=PENDING
          signal CAN4_RegenSW_Err: start 262, 1 bit, big-endian, i-signal-type=PRIMITIVE, init-value=constant-reference=Init_CAN4_RegenSW_Err, base-type=uint8, implementation-data-type=uint8, transfer-property=TRIGGERED-ON-CHANGE
          signal CAN4_SolarL: start 207, 8 bit, big-endian, i-signal-type=PRIMITIVE, init-value=constant-reference=Init_CAN4_SolarL, base-type=uint8, implementation-data-type=uint8, transfer-property=PENDING
          signal CAN4_SolarL_Err: start 225, 2 bit, big-endian, i-signal-type=PRIMITIVE, init-value=constant-reference=Init_CAN4_SolarL_Err, base-type=uint8, implementation-data-type=uint8, transfer-property=TRIGGERED-ON-CHANGE
          signal CAN4_SolarR: start 199, 8 bit, big-endian, i-signal-type=PRIMITIVE, init-value=constant-reference=Init_CAN4_SolarR, base-type=uint8, implementation-data-type=uint8, transfer-property=PENDING
          signal CAN4_SolarR_Err: start 227, 2 bit, big-endian, i-signal-type=PRIMITIVE, init-value=constant-reference=Init_CAN4_SolarR_Err, base-type=uint8, implementation-data-type=uint8, transfer-property=TRIGGERED-ON-CHANGE
          signal CAN4_T_Face_L: start 175, 8 bit, big-endian, i-signal-type=PRIMITIVE, init-value=constant-reference=Init_CAN4_T_Face_L, base-type=uint8, implementation-data-type=uint8, transfer-property=PENDING
          signal CAN4_T_Face_L_Err: start 217, 2 bit, big-endian, i-signal-type=PRIMITIVE, init-value=constant-reference=Init_CAN4_T_Face_L_Err, base-type=uint8, implementation-data-type=uint8, transfer-property=TRIGGERED-ON-CHANGE
          signal CAN4_T_Face_R: start 167, 8 bit, big-endian, i-signal-type=PRIMITIVE, init-value=constant-reference=Init_CAN4_T_Face_R, base-type=uint8, implementation-data-type=uint8, transfer-property=PENDING
          signal CAN4_T_Face_R_Err: start 221, 2 bit, big-endian, i-signal-type=PRIMITIVE, init-value=constant-reference=Init_CAN4_T_Face_R_Err, base-type=uint8, implementation-data-type=uint8, transfer-property=TRIGGERED-ON-CHANGE
          signal CAN4_T_Face_Rr: start 151, 8 bit, big-endian, i-signal-type=PRIMITIVE, init-value=constant-reference=Init_CAN4_T_Face_Rr, base-type=uint8, implementation-data-type=uint8, transfer-property=PENDING
          signal CAN4_T_Face_Rr_Err: start 209, 2 bit, big-endian, i-signal-type=PRIMITIVE, init-value=constant-reference=Init_CAN4_T_Face_Rr_Err, base-type=uint8, implementation-data-type=uint8, transfer-property=TRIGGERED-ON-CHANGE
          signal CAN4_T_Foot_L: start 159, 8 bit, big-endian, i-signal-type=PRIMITIVE, init-value=constant-reference=Init_CAN4_T_Foot_L, base-type=uint8, implementation-data-type=uint8, transfer-property=PENDING
          signal CAN4_T_Foot_L_Err: start 219, 2 bit, big-endian, i-signal-type=PRIMITIVE, init-value=constant-reference=Init_CAN4_T_Foot_L_Err, base-type=uint8, implementation-data-type=uint8, transfer-property=TRIGGERED-ON-CHANGE
          signal CAN4_T_Foot_R: start 135, 8 bit, big-endian, i-signal-type=PRIMITIVE, init-value=constant-reference=Init_CAN4_T_Foot_R, base-type=uint8, implementation-data-type=uint8, transfer-property=PENDING
          signal CAN4_T_Foot_R_Err: start 223, 2 bit, big-endian, i-signal-type=PRIMITIVE, init-value=constant-reference=Init_CAN4_T_Foot_R_Err, base-type=uint8, implementation-data-type=uint8, transfer-property=TRIGGERED-ON-CHANGE
          signal CAN4_T_Foot_Rr: start 143, 8 bit, big-endian, i-signal-type=PRIMITIVE, init-value=constant-reference=Init_CAN4_T_Foot_Rr, base-type=uint8, implementation-data-type=uint8, transfer-property=PENDING
          signal CAN4_T_Foot_Rr_Err: start 211, 2 bit, big-endian, i-signal-type=PRIMITIVE, init-value=constant-reference=Init_CAN4_T_Foot_Rr_Err, base-type=uint8, implementation-data-type=uint8, transfer-property=TRIGGERED-ON-CHANGE
          signal CAN4_Tevap: start 183, 8 bit, big-endian, i-signal-type=PRIMITIVE, init-value=constant-reference=Init_CAN4_Tevap, base-type=uint8, implementation-data-type=uint8, transfer-property=PENDING
          signal CAN4_Tevap_Err: start 229, 2 bit, big-endian, i-signal-type=PRIMITIVE, init-value=constant-reference=Init_CAN4_Tevap_Err, base-type=uint8, implementation-data-type=uint8, transfer-property=TRIGGERED-ON-CHANGE
          signal CAN4_Tincar: start 191, 8 bit, big-endian, i-signal-type=PRIMITIVE, init-value=constant-reference=Init_CAN4_Tincar, base-type=uint8, implementation-data-type=uint8, transfer-property=PENDING
          signal CAN4_Tincar_Err: start 231, 2 bit, big-endian, i-signal-type=PRIMITIVE, init-value=constant-reference=Init_CAN4_Tincar_Err, base-type=uint8, implementation-data-type=uint8, transfer-property=TRIGGERED-ON-CHANGE
          signal CAN4_ZDR_SYS_APMRetryCnt_Sta: start 247, 8 bit, big-endian, i-signal-type=PRIMITIVE, init-value=constant-reference=Init_CAN4_ZDR_SYS_APMRetryCnt_Sta, base-type=uint8, implementation-data-type=uint8, transfer-property=TRIGGERED-ON-CHANGE
          signal CAN4_ZDR_SYS_BSWSleepReq_Sta: start 259, 1 bit, big-endian, i-signal-type=PRIMITIVE, init-value=constant-reference=Init_CAN4_ZDR_SYS_BSWSleepReq_Sta, base-type=uint8, implementation-data-type=uint8, transfer-property=TRIGGERED-ON-CHANGE
          signal CAN4_ZDR_SYS_CSWRetryCnt_Sta: start 239, 8 bit, big-endian, i-signal-type=PRIMITIVE, init-value=constant-reference=Init_CAN4_ZDR_SYS_CSWRetryCnt_Sta, base-type=uint8, implementation-data-type=uint8, transfer-property=TRIGGERED-ON-CHANGE
          signal CAN4_ZDR_VCU_HWReset_Sta: start 268, 5 bit, big-endian, i-signal-type=PRIMITIVE, init-value=constant-reference=Init_CAN4_ZDR_VCU_HWReset_Sta, base-type=uint8, implementation-data-type=uint8, transfer-property=TRIGGERED-ON-CHANGE
          signal CAN4_ZDR_VCU_PwrSupply_Sta: start 263, 1 bit, big-endian, i-signal-type=PRIMITIVE, init-value=constant-reference=Init_CAN4_ZDR_VCU_PwrSupply_Sta, base-type=uint8, implementation-data-type=uint8, transfer-property=TRIGGERED-ON-CHANGE
          signal CAN4_ZoneDrMalfunLevel: start 250, 3 bit, big-endian, i-signal-type=PRIMITIVE, init-value=constant-reference=Init_CAN4_ZoneDrMalfunLevel, base-type=uint8, implementation-data-type=uint8, transfer-property=TRIGGERED-ON-CHANGE
      frame CAN4_ZONE_FR1: id 0x31C, frame-length=64, can-addressing-mode=STANDARD, can-fd-frame-support=true, can-frame-rx-behavior=CAN-FD, can-frame-tx-behavior=CAN-FD
        pdu CAN4_ZONE_FR1: length=64, minimum-delay=0.0, transmission-mode-true-timing={cyclic-timing=time-period=0.1, event-controlled-timing={number-of-repetitions=0, repetition-period=0}}, unused-bit-pattern=0
          mapping CAN4_SG_ZONE_FR1: i-signal-group=CAN4_SG_ZONE_FR1, start-position=0, transfer-property=TRIGGERED-ON-CHANGE
          signal CAN4_BDC_1_MoveEnable: start 173, 1 bit, big-endian, i-signal-type=PRIMITIVE, init-value=constant-reference=Init_CAN4_BDC_1_MoveEnable, base-type=uint8, implementation-data-type=uint8, transfer-property=PENDING
          signal CAN4_BDC_1_ReqMovePos: start 143, 8 bit, big-endian, i-signal-type=PRIMITIVE, init-value=constant-reference=Init_CAN4_BDC_1_ReqMovePos, base-type=uint8, implementation-data-type=uint8, transfer-property=PENDING
          signal CAN4_BMSChksmHSC6: start 47, 8 bit, big-endian, i-signal-type=PRIMITIVE, init-value=constant-reference=Init_CAN4_BMSChksmHSC6, base-type=uint8, implementation-data-type=uint8, transfer-property=PENDING
          signal CAN4_BMSEnbPTCHSC6: start 69, 1 bit, big-endian, i-signal-type=PRIMITIVE, init-value=constant-reference=Init_CAN4_BMSEnbPTCHSC6, base-type=uint8, implementation-data-type=uint8, transfer-property=PENDING
          signal CAN4_BMSInptClntTemHSC6: start 24, 9 bit, big-endian, i-signal-type=PRIMITIVE, init-value=constant-reference=Init_CAN4_BMSInptClntTemHSC6, base-type=uint16, implementation-data-type=uint16, transfer-property=PENDING
          signal CAN4_BMSPackVol_h6HSC6: start 67, 12 bit, big-endian, i-signal-type=PRIMITIVE, init-value=constant-reference=Init_CAN4_BMSPackVol_h6HSC6, base-type=uint16, implementation-data-type=uint16, transfer-property=PENDING
          signal CAN4_BMSReqMdHSC6: start 71, 2 bit, big-endian, i-signal-type=PRIMITIVE, init-value=constant-reference=Init_CAN4_BMSReqMdHSC6, base-type=uint8, implementation-data-type=uint8, transfer-property=PENDING
          signal CAN4_BMSReqPWMHSC6: start 31, 7 bit, big-endian, i-signal-type=PRIMITIVE, init-value=constant-reference=Init_CAN4_BMSReqPWMHSC6, base-type=uint8, implementation-data-type=uint8, transfer-property=PENDING
          signal CAN4_BMSReqPwrHSC6: start 15, 16 bit, big-endian, i-signal-type=PRIMITIVE, init-value=constant-reference=Init_CAN4_BMSReqPwrHSC6, base-type=uint16, implementation-data-type=uint16, transfer-property=PENDING
          signal CAN4_BMSReqRlngCtrHSC6: start 7, 4 bit, big-endian, i-signal-type=PRIMITIVE, init-value=constant-reference=Init_CAN4_BMSReqRlngCtrHSC6, base-type=uint8, implementation-data-type=uint8, transfer-property=PENDING
          signal CAN4_BMSReqTapPosHSC6: start 3, 4 bit, big-endian, i-signal-type=PRIMITIVE, init-value=constant-reference=Init_CAN4_BMSReqTapPosHSC6, base-type=uint8, implementation-data-type=uint8, transfer-property=PENDING
          signal CAN4_CCM_SpdCmd: start 54, 15 bit, big-endian, i-signal-type=PRIMITIVE, init-value=constant-reference=Init_CAN4_CCM_SpdCmd, base-type=uint16, implementation-data-type=uint16, transfer-property=PENDING
          signal CAN4_CCV4_MoveEnable: start 168, 1 bit, big-endian, i-signal-type=PRIMITIVE, init-value=constant-reference=Init_CAN4_CCV4_MoveEnable, base-type=uint8, implementation-data-type=uint8, transfer-property=PENDING
          signal CAN4_CCV4_ReqMovePos: start 169, 1 bit, big-endian, i-signal-type=PRIMITIVE, init-value=constant-reference=Init_CAN4_CCV4_ReqMovePos, base-type=uint8, implementation-data-type=uint8, transfer-property=PENDING
          signal CAN4_ChargeInletLockSta: start 55, 1 bit, big-endian, i-signal-type=PRIMITIVE, init-value=constant-reference=Init_CAN4_ChargeInletLockSta, base-type=uint8, implementation-data-type=uint8, transfer-property=TRIGGERED-ON-CHANGE
          signal CAN4_CompProEN: start 68, 1 bit, big-endian, i-signal-type=PRIMITIVE, init-value=constant-reference=Init_CAN4_CompProEN, base-type=uint8, implementation-data-type=uint8, transfer-property=PENDING
          signal CAN4_EWP1_Default_Operation_EWP_Rq: start 170, 1 bit, big-endian, i-signal-type=PRIMITIVE, init-value=constant-reference=Init_CAN4_EWP1_Default_Operation_EWP_Rq, base-type=uint8, implementation-data-type=uint8, transfer-property=PENDING
          signal CAN4_EWP1_RPM_Target_EWP_Rq: start 119, 8 bit, big-endian, i-signal-type=PRIMITIVE, init-value=constant-reference=Init_CAN4_EWP1_RPM_Target_EWP_Rq, base-type=uint8, implementation-data-type=uint8, transfer-property=PENDING
          signal CAN4_EWP2_Default_Operation_EWP_Rq: start 171, 1 bit, big-endian, i-signal-type=PRIMITIVE, init-value=constant-reference=Init_CAN4_EWP2_Default_Operation_EWP_Rq, base-type=uint8, implementation-data-type=uint8, transfer-property=PENDING
          signal CAN4_EWP2_RPM_Target_EWP_Rq: start 127, 8 bit, big-endian, i-signal-type=PRIMITIVE, init-value=constant-reference=Init_CAN4_EWP2_RPM_Target_EWP_Rq, base-type=uint8, implementation-data-type=uint8, transfer-property=PENDING
          signal CAN4_EWP3_Default_Operation_EWP_Rq: start 172, 1 bit, big-endian, i-signal-type=PRIMITIVE, init-value=constant-reference=Init_CAN4_EWP3_Default_Operation_EWP_Rq, base-type=uint8, implementation-data-type=uint8, transfer-property=PENDING
          signal CAN4_EWP3_RPM_Target_EWP_Rq: start 135, 8 bit, big-endian, i-signal-type=PRIMITIVE, init-value=constant-reference=Init_CAN4_EWP3_RPM_Target_EWP_Rq, base-type=uint8, implementation-data-type=uint8, transfer-property=PENDING
          signal CAN4_EXV2_Cmd_Init_Rq: start 162, 3 bit, big-endian, i-signal-type=PRIMITIVE, init-value=constant-reference=Init_CAN4_EXV2_Cmd_Init_Rq, base-type=uint8, implementation-data-type=uint8, transfer-property=PENDING
          signal CAN4_EXV2_Cmd_Move_Enbl: start 167, 1 bit, big-endian, i-signal-type=PRIMITIVE, init-value=constant-reference=Init_CAN4_EXV2_Cmd_Move_Enbl, base-type=uint8, implementation-data-type=uint8, transfer-property=PENDING
          signal CAN4_EXV2_Cmd_Set_Rq: start 103, 16 bit, big-endian, i-signal-type=PRIMITIVE, init-value=constant-reference=Init_CAN4_EXV2_Cmd_Set_Rq, base-type=uint16, implementation-data-type=uint16, transfer-property=PENDING
          signal CAN4_EXV_Cmd_Init_Rq: start 165, 3 bit, big-endian, i-signal-type=PRIMITIVE, init-value=constant-reference=Init_CAN4_EXV_Cmd_Init_Rq, base-type=uint8, implementation-data-type=uint8, transfer-property=PENDING
          signal CAN4_EXV_Cmd_Move_Enbl: start 166, 1 bit, big-endian, i-signal-type=PRIMITIVE, init-value=constant-reference=Init_CAN4_EXV_Cmd_Move_Enbl, base-type=uint8, implementation-data-type=uint8, transfer-property=PENDING
          signal CAN4_EXV_Cmd_Set_Rq: start 87, 16 bit, big-endian, i-signal-type=PRIMITIVE, init-value=constant-reference=Init_CAN4_EXV_Cmd_Set_Rq, base-type=uint16, implementation-data-type=uint16, transfer-property=PENDING
          signal CAN4_FLPosLPErr: start 197, 1 bit, big-endian, i-signal-type=PRIMITIVE, init-value=constant-reference=Init_CAN4_FLPosLPErr, base-type=uint8, implementation-data-type=uint8, transfer-property=TRIGGERED-ON-CHANGE
          signal CAN4_FLTurnLPErr: start 198, 1 bit, big-endian, i-signal-type=PRIMITIVE, init-value=constant-reference=Init_CAN4_FLTurnLPErr, base-type=uint8, implementation-data-type=uint8, transfer-property=TRIGGERED-ON-CHANGE
          signal CAN4_FLTurnLampC: start 159, 8 bit, big-endian, i-signal-type=PRIMITIVE, init-value=constant-reference=Init_CAN4_FLTurnLampC, base-type=uint8, implementation-data-type=uint8, transfer-property=TRIGGERED-ON-CHANGE
          signal CAN4_FLTurn_Light_Warning: start 203, 1 bit, big-endian, i-signal-type=PRIMITIVE, init-value=constant-reference=Init_CAN4_FLTurn_Light_Warning, base-type=uint8, implementation-data-type=uint8, transfer-property=PENDING
          signal CAN4_FRPosLPErr: start 213, 1 bit, big-endian, i-signal-type=PRIMITIVE, init-value=constant-reference=Init_CAN4_FRPosLPErr, base-type=uint8, implementation-data-type=uint8, transfer-property=TRIGGERED-ON-CHANGE
          signal CAN4_FRTurnLPErr: start 214, 1 bit, big-endian, i-signal-type=PRIMITIVE, init-value=constant-reference=Init_CAN4_FRTurnLPErr, base-type=uint8, implementation-data-type=uint8, transfer-property=TRIGGERED-ON-CHANGE
          signal CAN4_FRTurnLampC: start 151, 8 bit, big-endian, i-signal-type=PRIMITIVE, init-value=constant-reference=Init_CAN4_FRTurnLampC, base-type=uint8, implementation-data-type=uint8, transfer-property=TRIGGERED-ON-CHANGE
          signal CAN4_FRTurn_Light_Warning: start 219, 1 bit, big-endian, i-signal-type=PRIMITIVE, init-value=constant-reference=Init_CAN4_FRTurn_Light_Warning, base-type=uint8, implementation-data-type=uint8, transfer-property=PENDING
          signal CAN4_FWiperAS: start 175, 1 bit, big-endian, i-signal-type=PRIMITIVE, init-value=constant-reference=Init_CAN4_FWiperAS, base-type=uint8, implementation-data-type=uint8, transfer-property=TRIGGERED-ON-CHANGE
          signal CAN4_FWiperProtection: start 174, 1 bit, big-endian, i-signal-type=PRIMITIVE, init-value=constant-reference=Init_CAN4_FWiperProtection, base-type=uint8, implementation-data-type=uint8, transfer-property=TRIGGERED-ON-CHANGE
          signal CAN4_LADBErr: start 194, 1 bit, big-endian, i-signal-type=PRIMITIVE, init-value=constant-reference=Init_CAN4_LADBErr, base-type=uint8, implementation-data-type=uint8, transfer-property=TRIGGERED-ON-CHANGE
          signal CAN4_LADB_Hibeam_Indication: start 192, 1 bit, big-endian, i-signal-type=PRIMITIVE, init-value=constant-reference=Init_CAN4_LADB_Hibeam_Indication, base-type=uint8, implementation-data-type=uint8, transfer-property=PENDING
          signal CAN4_LADB_Operation_Status: start 207, 1 bit, big-endian, i-signal-type=PRIMITIVE, init-value=constant-reference=Init_CAN4_LADB_Operation_Status, base-type=uint8, implementation-data-type=uint8, transfer-property=PENDING
          signal CAN4_LADB_Warning: start 206, 1 bit, big-endian, i-signal-type=PRIMITIVE, init-value=constant-reference=Init_CAN4_LADB_Warning, base-type=uint8, implementation-data-type=uint8, transfer-property=PENDING
          signal CAN4_LAHB_Warning: start 204, 1 bit, big-endian, i-signal-type=PRIMITIVE, init-value=constant-reference=Init_CAN4_LAHB_Warning, base-type=uint8, implementation-data-type=uint8, transfer-property=PENDING
          signal CAN4_LDRLErr: start 193, 1 bit, big-endian, i-signal-type=PRIMITIVE, init-value=constant-reference=Init_CAN4_LDRLErr, base-type=uint8, implementation-data-type=uint8, transfer-property=TRIGGERED-ON-CHANGE
          signal CAN4_LDRL_Warning: start 202, 1 bit, big-endian, i-signal-type=PRIMITIVE, init-value=constant-reference=Init_CAN4_LDRL_Warning, base-type=uint8, implementation-data-type=uint8, transfer-property=PENDING
          signal CAN4_LH_BeamErr: start 195, 1 bit, big-endian, i-signal-type=PRIMITIVE, init-value=constant-reference=Init_CAN4_LH_BeamErr, base-type=uint8, implementation-data-type=uint8, transfer-property=TRIGGERED-ON-CHANGE
          signal CAN4_LLB_Warning: start 205, 1 bit, big-endian, i-signal-type=PRIMITIVE, init-value=constant-reference=Init_CAN4_LLB_Warning, base-type=uint8, implementation-data-type=uint8, transfer-property=PENDING
          signal CAN4_LL_BeamErr: start 196, 1 bit, big-endian, i-signal-type=PRIMITIVE, init-value=constant-reference=Init_CAN4_LL_BeamErr, base-type=uint8, implementation-data-type=uint8, transfer-property=TRIGGERED-ON-CHANGE
          signal CAN4_Lposition_Lamp_Warning: start 199, 1 bit, big-endian, i-signal-type=PRIMITIVE, init-value=constant-reference=Init_CAN4_Lposition_Lamp_Warning, base-type=uint8, implementation-data-type=uint8, transfer-property=PENDING
          signal CAN4_RADBErr: start 210, 1 bit, big-endian, i-signal-type=PRIMITIVE, init-value=constant-reference=Init_CAN4_RADBErr, base-type=uint8, implementation-data-type=uint8, transfer-property=TRIGGERED-ON-CHANGE
          signal CAN4_RADB_Hibeam_Indication: start 208, 1 bit, big-endian, i-signal-type=PRIMITIVE, init-value=constant-reference=Init_CAN4_RADB_Hibeam_Indication, base-type=uint8, implementation-data-type=uint8, transfer-property=PENDING
          signal CAN4_RADB_Operation_Status: start 223, 1 bit, big-endian, i-signal-type=PRIMITIVE, init-value=constant-reference=Init_CAN4_RADB_Operation_Status, base-type=uint8, implementation-data-type=uint8, transfer-property=PENDING
          signal CAN4_RADB_Warning: start 222, 1 bit, big-endian, i-signal-type=PRIMITIVE, init-value=constant-reference=Init_CAN4_RADB_Warning, base-type=uint8, implementation-data-type=uint8, transfer-property=PENDING
          signal CAN4_RAHB_Warning: start 220, 1 bit, big-endian, i-signal-type=PRIMITIVE, init-value=constant-reference=Init_CAN4_RAHB_Warning, base-type=uint8, implementation-data-type=uint8, transfer-property=PENDING
          signal CAN4_RDRLErr: start 209, 1 bit, big-endian, i-signal-type=PRIMITIVE, init-value=constant-reference=Init_CAN4_RDRLErr, base-type=uint8, implementation-data-type=uint8, transfer-property=TRIGGERED-ON-CHANGE
          signal CAN4_RDRL_Warning: start 218, 1 bit, big-endian, i-signal-type=PRIMITIVE, init-value=constant-reference=Init_CAN4_RDRL_Warning, base-type=uint8, implementation-data-type=uint8, transfer-property=PENDING
          signal CAN4_RH_BeamErr: start 211, 1 bit, big-endian, i-signal-type=PRIMITIVE, init-value=constant-reference=Init_CAN4_RH_BeamErr, base-type=uint8, implementation-data-type=uint8, transfer-property=TRIGGERED-ON-CHANGE
          signal CAN4_RLB_Warning: start 221, 1 bit, big-endian, i-signal-type=PRIMITIVE, init-value=constant-reference=Init_CAN4_RLB_Warning, base-type=uint8, implementation-data-type=uint8, transfer-property=PENDING
          signal CAN4_RL_BeamErr: start 212, 1 bit, big-endian, i-signal-type=PRIMITIVE, init-value=constant-reference=Init_CAN4_RL_BeamErr, base-type=uint8, implementation-data-type=uint8, transfer-property=TRIGGERED-ON-CHANGE
          signal CAN4_Rposition_Lamp_Warning: start 215, 1 bit, big-endian, i-signal-type=PRIMITIVE, init-value=constant-reference=Init_CAN4_Rposition_Lamp_Warning, base-type=uint8, implementation-data-type=uint8, transfer-property=PENDING
          signal CAN4_TrailerCheck: start 190, 1 bit, big-endian, i-signal-type=PRIMITIVE, init-value=constant-reference=Init_CAN4_TrailerCheck, base-type=uint8, implementation-data-type=uint8, transfer-property=TRIGGERED-ON-CHANGE
          signal CAN4_TrailerModeSta: start 189, 2 bit, big-endian, i-signal-type=PRIMITIVE, init-value=constant-reference=Init_CAN4_TrailerModeSta, base-type=uint8, implementation-data-type=uint8, transfer-property=TRIGGERED-ON-CHANGE
          signal CAN4_ZFR_BCM_ChargerDoorSW_Sta: start 187, 1 bit, big-endian, i-signal-type=PRIMITIVE, init-value=constant-reference=Init_CAN4_ZFR_BCM_ChargerDoorSW_Sta, base-type=uint8, implementation-data-type=uint8, transfer-property=TRIGGERED-ON-CHANGE
          signal CAN4_ZFR_EChrg_Active_Sta: start 186, 3 bit, big-endian, i-signal-type=PRIMITIVE, init-value=constant-reference=Init_CAN4_ZFR_EChrg_Active_Sta, base-type=uint8, implementation-data-type=uint8, transfer-property=TRIGGERED-ON-CHANGE
          signal CAN4_ZFR_EChrg_Sys_Sta: start 201, 2 bit, big-endian, i-signal-type=PRIMITIVE, init-value=constant-reference=Init_CAN4_ZFR_EChrg_Sys_Sta, base-type=uint8, implementation-data-type=uint8, transfer-property=TRIGGERED-ON-CHANGE
          signal CAN4_ZFR_THCM_CLEVentActY_Sta: start 262, 7 bit, big-endian, i-signal-type=PRIMITIVE, init-value=constant-reference=Init_CAN4_ZFR_THCM_CLEVentActY_Sta, base-type=uint8, implementation-data-type=uint8, transfer-property=PENDING
          signal CAN4_ZFR_THCM_CLEVentActZ_Sta: start 270, 7 bit, big-endian, i-signal-type=PRIMITIVE, init-value=constant-reference=Init_CAN4_ZFR_THCM_CLEVentActZ_Sta, base-type=uint8, implementation-data-type=uint8, transfer-property=PENDING
          signal CAN4_ZFR_THCM_CREVentActY_Sta: start 278, 7 bit, big-endian, i-signal-type=PRIMITIVE, init-value=constant-reference=Init_CAN4_ZFR_THCM_CREVentActY_Sta, base-type=uint8, implementation-data-type=uint8, transfer-property=PENDING
          signal CAN4_ZFR_THCM_CREVentActZ_Sta: start 286, 7 bit, big-endian, i-signal-type=PRIMITIVE, init-value=constant-reference=Init_CAN4_ZFR_THCM_CREVentActZ_Sta, base-type=uint8, implementation-data-type=uint8, transfer-property=PENDING
          signal CAN4_ZFR_THCM_DrEVentActY_Sta: start 230, 7 bit, big-endian, i-signal-type=PRIMITIVE, init-value=constant-reference=Init_CAN4_ZFR_THCM_DrEVentActY_Sta, base-type=uint8, implementation-data-type=uint8, transfer-property=PENDING
          signal CAN4_ZFR_THCM_DrEVentActZ_Sta: start 238, 7 bit, big-endian, i-signal-type=PRIMITIVE, init-value=constant-reference=Init_CAN4_ZFR_THCM_DrEVentActZ_Sta, base-type=uint8, implementation-data-type=uint8, transfer-property=PENDING
          signal CAN4_ZFR_THCM_PsEVentActY_Sta: start 246, 7 bit, big-endian, i-signal-type=PRIMITIVE, init-value=constant-reference=Init_CAN4_ZFR_THCM_PsEVentActY_Sta, base-type=uint8, implementation-data-type=uint8, transfer-property=PENDING
          signal CAN4_ZFR_THCM_PsEVentActZ_Sta: start 254, 7 bit, big-endian, i-signal-type=PRIMITIVE, init-value=constant-reference=Init_CAN4_ZFR_THCM_PsEVentActZ_Sta, base-type=uint8, implementation-data-type=uint8, transfer-property=PENDING
